VERSION ""

NS_ :

BS_:
BU_: Receiver ChassisBus VehicleBus PartyBus apb ui app aps bms gtwu odin cc cmp cp das dif dir di epas3p epas3s epbl epbr esp fc gtw hvp ibst ocs1p park pcs pmf pmr pm ptc radc rcm2 rcm sccm scm scs tas tpms umc vcfront vcleft vcright vcsec GTW
BO_ 12 ID00CUI_status: 8 VehicleBus
   SG_ UI_audioActive : 1|1@1+ (1,0) [0|1] "" Receiver
   SG_ UI_autopilotTrial : 12|2@1+ (1,0) [0|3] "" Receiver
   SG_ UI_bluetoothActive : 2|1@1+ (1,0) [0|1] "" Receiver
   SG_ UI_cameraActive : 41|1@1+ (1,0) [0|1] "" Receiver
   SG_ UI_cellActive : 3|1@1+ (1,0) [0|1] "" Receiver
   SG_ UI_cellConnected : 10|1@1+ (1,0) [0|1] "" Receiver
   SG_ UI_cellNetworkTechnology : 19|4@1+ (1,0) [0|15] "" Receiver
   SG_ UI_cellReceiverPower : 24|8@1+ (1,-128) [-128|127] "dB" Receiver
   SG_ UI_cellSignalBars : 42|3@1+ (1,0) [0|7] "" Receiver
   SG_ UI_cpuTemperature : 56|8@1- (1,40) [-20|100] "C" Receiver
   SG_ UI_developmentCar : 40|1@1+ (1,0) [0|1] "" Receiver
   SG_ UI_displayOn : 5|1@1+ (1,0) [0|1] "" Receiver
   SG_ UI_displayReady : 4|1@1+ (1,0) [0|1] "" Receiver
   SG_ UI_factoryReset : 14|2@1+ (1,0) [0|3] "" Receiver
   SG_ UI_falseTouchCounter : 32|8@1+ (1,0) [0|255] "1" Receiver
   SG_ UI_gpsActive : 16|1@1+ (1,0) [0|1] "" Receiver
   SG_ UI_pcbTemperature : 48|8@1- (1,40) [-20|100] "C" Receiver
   SG_ UI_radioActive : 18|1@1+ (1,0) [0|1] "" Receiver
   SG_ UI_readyForDrive : 9|1@1+ (1,0) [0|1] "" Receiver
   SG_ UI_screenshotActive : 17|1@1+ (1,0) [0|1] "" Receiver
   SG_ UI_systemActive : 8|1@1+ (1,0) [0|1] "" Receiver
   SG_ UI_touchActive : 0|1@1+ (1,0) [0|1] "" Receiver
   SG_ UI_vpnActive : 11|1@1+ (1,0) [0|1] "" Receiver
   SG_ UI_wifiActive : 6|1@1+ (1,0) [0|1] "" Receiver
   SG_ UI_wifiConnected : 7|1@1+ (1,0) [0|1] "" Receiver

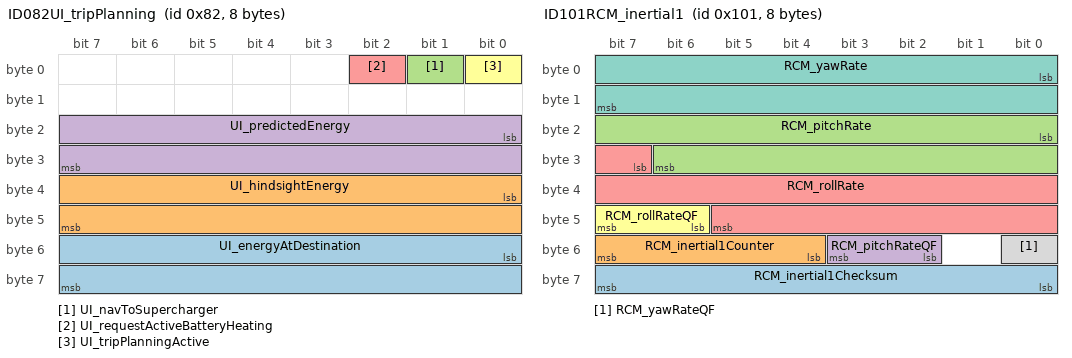
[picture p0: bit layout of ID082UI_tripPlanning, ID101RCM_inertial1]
BO_ 130 ID082UI_tripPlanning: 8 VehicleBus
   SG_ UI_energyAtDestination : 48|16@1- (0.01,0) [-327.67|327.67] "kWh" Receiver
   SG_ UI_hindsightEnergy : 32|16@1- (0.01,0) [-327.67|327.67] "kWh" Receiver
   SG_ UI_navToSupercharger : 1|1@1+ (1,0) [0|1] "" Receiver
   SG_ UI_predictedEnergy : 16|16@1- (0.01,0) [-327.67|327.67] "kWh" Receiver
   SG_ UI_requestActiveBatteryHeating : 2|1@1+ (1,0) [0|1] "" Receiver
   SG_ UI_tripPlanningActive : 0|1@1+ (1,0) [0|1] "" Receiver

BO_ 257 ID101RCM_inertial1: 8 ChassisBus
   SG_ RCM_inertial1Checksum : 56|8@1+ (1,0) [0|255] "" Receiver
   SG_ RCM_inertial1Counter : 52|4@1+ (1,0) [0|15] "" Receiver
   SG_ RCM_pitchRate : 16|15@1- (0.00025,0) [-4.096|4.09575] "rad/s" Receiver
   SG_ RCM_pitchRateQF : 50|2@1+ (1,0) [0|3] "" Receiver
   SG_ RCM_rollRate : 31|15@1- (0.00025,0) [-4.096|4.09575] "rad/s" Receiver
   SG_ RCM_rollRateQF : 46|2@1+ (1,0) [0|3] "" Receiver
   SG_ RCM_yawRate : 0|16@1- (0.0001,0) [-3.2766|3.2766] "rad/s" Receiver
   SG_ RCM_yawRateQF : 48|1@1+ (1,0) [0|1] "" Receiver

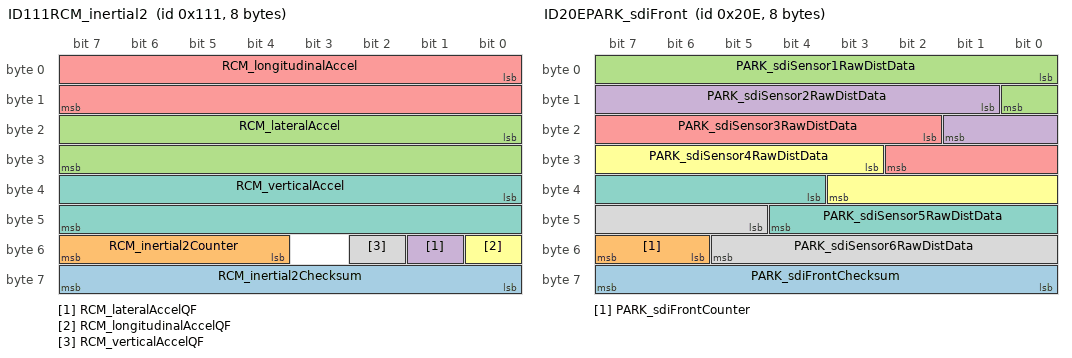
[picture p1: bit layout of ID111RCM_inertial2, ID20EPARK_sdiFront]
BO_ 273 ID111RCM_inertial2: 8 ChassisBus
   SG_ RCM_inertial2Checksum : 56|8@1+ (1,0) [0|255] "" Receiver
   SG_ RCM_inertial2Counter : 52|4@1+ (1,0) [0|15] "" Receiver
   SG_ RCM_lateralAccel : 16|16@1- (0.00125,0) [-40.9575|40.9575] "m/s^2" Receiver
   SG_ RCM_lateralAccelQF : 49|1@1+ (1,0) [0|1] "" Receiver
   SG_ RCM_longitudinalAccel : 0|16@1- (0.00125,0) [-40.9575|40.9575] "m/s^2" Receiver
   SG_ RCM_longitudinalAccelQF : 48|1@1+ (1,0) [0|1] "" Receiver
   SG_ RCM_verticalAccel : 32|16@1- (0.00125,0) [-40.9575|40.9575] "m/s^2" Receiver
   SG_ RCM_verticalAccelQF : 50|1@1+ (1,0) [0|1] "" Receiver

BO_ 258 ID102VCLEFT_doorStatus: 8 VehicleBus
   SG_ VCLEFT_frontHandlePWM : 16|7@1+ (1,0) [0|100] "%" Receiver
   SG_ VCLEFT_frontHandlePulled : 10|1@1+ (1,0) [0|1] "" Receiver
   SG_ VCLEFT_frontHandlePulledPersist : 62|1@1+ (1,0) [0|1] "" Receiver
   SG_ VCLEFT_frontIntSwitchPressed : 31|1@1+ (1,0) [0|1] "" Receiver
   SG_ VCLEFT_frontLatchStatus : 0|4@1+ (1,0) [0|8] "" Receiver
   SG_ VCLEFT_frontLatchSwitch : 8|1@1+ (1,0) [0|1] "" Receiver
   SG_ VCLEFT_frontRelActuatorSwitch : 12|1@1+ (1,0) [0|1] "" Receiver
   SG_ VCLEFT_mirrorDipped : 61|1@1+ (1,0) [0|1] "" Receiver
   SG_ VCLEFT_mirrorFoldState : 52|3@1+ (1,0) [0|4] "" Receiver
   SG_ VCLEFT_mirrorHeatState : 58|3@1+ (1,0) [0|4] "" Receiver
   SG_ VCLEFT_mirrorRecallState : 55|3@1+ (1,0) [0|5] "" Receiver
   SG_ VCLEFT_mirrorState : 49|3@1+ (1,0) [0|4] "" Receiver
   SG_ VCLEFT_mirrorTiltXPosition : 33|8@1+ (0.02,0) [0|5] "V" Receiver
   SG_ VCLEFT_mirrorTiltYPosition : 41|8@1+ (0.02,0) [0|5] "V" Receiver
   SG_ VCLEFT_rearHandlePWM : 24|7@1+ (1,0) [0|100] "%" Receiver
   SG_ VCLEFT_rearHandlePulled : 11|1@1+ (1,0) [0|1] "" Receiver
   SG_ VCLEFT_rearIntSwitchPressed : 32|1@1+ (1,0) [0|1] "" Receiver
   SG_ VCLEFT_rearLatchStatus : 4|4@1+ (1,0) [0|8] "" Receiver
   SG_ VCLEFT_rearLatchSwitch : 9|1@1+ (1,0) [0|1] "" Receiver
   SG_ VCLEFT_rearRelActuatorSwitch : 13|1@1+ (1,0) [0|1] "" Receiver

BO_ 259 ID103VCRIGHT_doorStatus: 8 VehicleBus
   SG_ VCRIGHT_frontHandlePWM : 14|7@1+ (1,0) [0|100] "%" Receiver
   SG_ VCRIGHT_frontHandlePulled : 10|1@1+ (1,0) [0|1] "" Receiver
   SG_ VCRIGHT_frontHandlePulledPersist : 30|1@1+ (1,0) [0|1] "" Receiver
   SG_ VCRIGHT_frontIntSwitchPressed : 31|1@1+ (1,0) [0|1] "" Receiver
   SG_ VCRIGHT_frontLatchStatus : 0|4@1+ (1,0) [0|8] "" Receiver
   SG_ VCRIGHT_frontLatchSwitch : 8|1@1+ (1,0) [0|1] "" Receiver
   SG_ VCRIGHT_frontRelActuatorSwitch : 12|1@1+ (1,0) [0|1] "" Receiver
   SG_ VCRIGHT_mirrorDipped : 63|1@1+ (1,0) [0|1] "" Receiver
   SG_ VCRIGHT_mirrorFoldState : 52|3@1+ (1,0) [0|4] "" Receiver
   SG_ VCRIGHT_mirrorRecallState : 60|3@1+ (1,0) [0|5] "" Receiver
   SG_ VCRIGHT_mirrorState : 49|3@1+ (1,0) [0|4] "" Receiver
   SG_ VCRIGHT_mirrorTiltXPosition : 33|8@1+ (0.02,0) [0|5] "V" Receiver
   SG_ VCRIGHT_mirrorTiltYPosition : 41|8@1+ (0.02,0) [0|5] "V" Receiver
   SG_ VCRIGHT_rearHandlePWM : 21|7@1+ (1,0) [0|100] "%" Receiver
   SG_ VCRIGHT_rearHandlePulled : 11|1@1+ (1,0) [0|1] "" Receiver
   SG_ VCRIGHT_rearIntSwitchPressed : 32|1@1+ (1,0) [0|1] "" Receiver
   SG_ VCRIGHT_rearLatchStatus : 4|4@1+ (1,0) [0|8] "" Receiver
   SG_ VCRIGHT_rearLatchSwitch : 9|1@1+ (1,0) [0|1] "" Receiver
   SG_ VCRIGHT_rearRelActuatorSwitch : 13|1@1+ (1,0) [0|1] "" Receiver
   SG_ VCRIGHT_reservedForBackCompat : 28|2@1+ (1,0) [0|3] "" Receiver
   SG_ VCRIGHT_trunkLatchStatus : 56|4@1+ (1,0) [0|8] "" Receiver

BO_ 291 ID123UI_alertMatrix1: 8 VehicleBus
   SG_ UI_a001_DriverDoorOpen : 0|1@1+ (1,0) [0|1] "" Receiver
   SG_ UI_a002_DoorOpen : 1|1@1+ (1,0) [0|1] "" Receiver
   SG_ UI_a003_TrunkOpen : 2|1@1+ (1,0) [0|1] "" Receiver
   SG_ UI_a004_FrunkOpen : 3|1@1+ (1,0) [0|1] "" Receiver
   SG_ UI_a005_HeadlightsOnDoorOpen : 4|1@1+ (1,0) [0|1] "" Receiver
   SG_ UI_a006_RemoteServiceAlert : 5|1@1+ (1,0) [0|1] "" Receiver
   SG_ UI_a007_SoftPackConfigMismatch : 6|1@1+ (1,0) [0|1] "" Receiver
   SG_ UI_a008_TouchScreenError : 7|1@1+ (1,0) [0|1] "" Receiver
   SG_ UI_a009_SquashfsError : 8|1@1+ (1,0) [0|1] "" Receiver
   SG_ UI_a010_MapsMissing : 9|1@1+ (1,0) [0|1] "" Receiver
   SG_ UI_a011_IncorrectMap : 10|1@1+ (1,0) [0|1] "" Receiver
   SG_ UI_a012_NotOnPrivateProperty : 11|1@1+ (1,0) [0|1] "" Receiver
   SG_ UI_a013_TPMSHardWarning : 12|1@1+ (1,0) [0|1] "" Receiver
   SG_ UI_a014_TPMSSoftWarning : 13|1@1+ (1,0) [0|1] "" Receiver
   SG_ UI_a015_TPMSOverPressureWarning : 14|1@1+ (1,0) [0|1] "" Receiver
   SG_ UI_a016_TPMSTemperatureWarning : 15|1@1+ (1,0) [0|1] "" Receiver
   SG_ UI_a017_TPMSSystemFault : 16|1@1+ (1,0) [0|1] "" Receiver
   SG_ UI_a018_SlipStartOn : 17|1@1+ (1,0) [0|1] "" Receiver
   SG_ UI_a019_ParkBrakeFault : 18|1@1+ (1,0) [0|1] "" Receiver
   SG_ UI_a020_SteeringReduced : 19|1@1+ (1,0) [0|1] "" Receiver
   SG_ UI_a021_RearSeatbeltUnbuckled : 20|1@1+ (1,0) [0|1] "" Receiver
   SG_ UI_a022_ApeFusesEtc : 21|1@1+ (1,0) [0|1] "" Receiver
   SG_ UI_a023_CellInternetCheckFailed : 22|1@1+ (1,0) [0|1] "" Receiver
   SG_ UI_a024_WifiInternetCheckFailed : 23|1@1+ (1,0) [0|1] "" Receiver
   SG_ UI_a025_WifiOnlineCheckFailed : 24|1@1+ (1,0) [0|1] "" Receiver
   SG_ UI_a026_ModemResetLoopDetected : 25|1@1+ (1,0) [0|1] "" Receiver
   SG_ UI_a027_AutoSteerMIA : 26|1@1+ (1,0) [0|1] "" Receiver
   SG_ UI_a028_FrontTrunkPopupClosed : 27|1@1+ (1,0) [0|1] "" Receiver
   SG_ UI_a029_ModemMIA : 28|1@1+ (1,0) [0|1] "" Receiver
   SG_ UI_a030_ModemVMCrash : 29|1@1+ (1,0) [0|1] "" Receiver
   SG_ UI_a031_BrakeFluidLow : 30|1@1+ (1,0) [0|1] "" Receiver
   SG_ UI_a032_CellModemRecoveryResets : 31|1@1+ (1,0) [0|1] "" Receiver
   SG_ UI_a033_ApTrialExpired : 32|1@1+ (1,0) [0|1] "" Receiver
   SG_ UI_a034_WakeupProblem : 33|1@1+ (1,0) [0|1] "" Receiver
   SG_ UI_a035_AudioWatchdogKernelError : 34|1@1+ (1,0) [0|1] "" Receiver
   SG_ UI_a036_AudioWatchdogHfpError : 35|1@1+ (1,0) [0|1] "" Receiver
   SG_ UI_a037_AudioWatchdogXrunStormEr : 36|1@1+ (1,0) [0|1] "" Receiver
   SG_ UI_a038_AudioWatchdogA2bI2cLocku : 37|1@1+ (1,0) [0|1] "" Receiver
   SG_ UI_a039_AudioA2bNeedRediscovery : 38|1@1+ (1,0) [0|1] "" Receiver
   SG_ UI_a040_HomelinkTransmit : 39|1@1+ (1,0) [0|1] "" Receiver
   SG_ UI_a041_AudioDmesgXrun : 40|1@1+ (1,0) [0|1] "" Receiver
   SG_ UI_a042_AudioDmesgRtThrottling : 41|1@1+ (1,0) [0|1] "" Receiver
   SG_ UI_a043_InvalidMapDataOverride : 42|1@1+ (1,0) [0|1] "" Receiver
   SG_ UI_a044_AudioDmesgDspException : 43|1@1+ (1,0) [0|1] "" Receiver
   SG_ UI_a045_ECallNeedsService : 44|1@1+ (1,0) [0|1] "" Receiver
   SG_ UI_a046_BackupCameraStreamError : 45|1@1+ (1,0) [0|1] "" Receiver
   SG_ UI_a047_CellRoamingDisallowed : 46|1@1+ (1,0) [0|1] "" Receiver
   SG_ UI_a048_AudioPremiumAmpCheckFail : 47|1@1+ (1,0) [0|1] "" Receiver
   SG_ UI_a049_BrakeShiftRequired : 48|1@1+ (1,0) [0|1] "" Receiver
   SG_ UI_a050_BackupCameraIPUTimeout : 49|1@1+ (1,0) [0|1] "" Receiver
   SG_ UI_a051_BackupCameraFrameTimeout : 50|1@1+ (1,0) [0|1] "" Receiver
   SG_ UI_a052_KernelPanicReported : 51|1@1+ (1,0) [0|1] "" Receiver
   SG_ UI_a053_QtCarExitError : 52|1@1+ (1,0) [0|1] "" Receiver
   SG_ UI_a054_AudioBoostPowerBad : 53|1@1+ (1,0) [0|1] "" Receiver
   SG_ UI_a055_ManualECallDisabled : 54|1@1+ (1,0) [0|1] "" Receiver
   SG_ UI_a056_ManualECallButtonDisconn : 55|1@1+ (1,0) [0|1] "" Receiver
   SG_ UI_a057_CellAntennaDisconnected : 56|1@1+ (1,0) [0|1] "" Receiver
   SG_ UI_a058_GPSAntennaDisconnected : 57|1@1+ (1,0) [0|1] "" Receiver
   SG_ UI_a059_ECallSpeakerDisconnected : 58|1@1+ (1,0) [0|1] "" Receiver
   SG_ UI_a060_ECallMicDisconnected : 59|1@1+ (1,0) [0|1] "" Receiver
   SG_ UI_a061_SIMTestFailed : 60|1@1+ (1,0) [0|1] "" Receiver
   SG_ UI_a062_ENSTestFailed : 61|1@1+ (1,0) [0|1] "" Receiver
   SG_ UI_a063_CellularTestFailed : 62|1@1+ (1,0) [0|1] "" Receiver
   SG_ UI_a064_ModemFirmwareTestFailed : 63|1@1+ (1,0) [0|1] "" Receiver

BO_ 322 ID142VCLEFT_liftgateStatus: 8 VehicleBus
   SG_ VCLEFT_liftgateStatusIndex M : 0|2@1+ (1,0) [0|2] "" Receiver
   SG_ VCLEFT_liftgateLatchRequest m0 : 61|3@1+ (1,0) [0|4] "" Receiver
   SG_ VCLEFT_liftgateMvmntNotAllowedCo m0 : 14|3@1+ (1,0) [0|5] "" Receiver
   SG_ VCLEFT_liftgatePhysicalChimeRequ m0 : 21|3@1+ (1,0) [0|4] "" Receiver
   SG_ VCLEFT_liftgatePosition m1 : 21|7@1- (1,33) [-5|70] "deg" Receiver
   SG_ VCLEFT_liftgatePositionCalibrate m0 : 17|1@1+ (1,0) [0|1] "" Receiver
   SG_ VCLEFT_liftgateRequestSource m0 : 7|3@1+ (1,0) [0|7] "" Receiver
   SG_ VCLEFT_liftgateSpeed m1 : 28|10@1- (0.1,0) [-30|30] "deg/s" Receiver
   SG_ VCLEFT_liftgateState m0 : 3|4@1+ (1,0) [0|12] "" Receiver
   SG_ VCLEFT_liftgateStoppingCondition m0 : 10|4@1+ (1,0) [0|11] "" Receiver
   SG_ VCLEFT_liftgateStrutCurrent m1 : 11|10@1- (0.1,0) [-30|30] "A" Receiver
   SG_ VCLEFT_liftgateStrutDutyCycle m1 : 3|8@1- (1,0) [-100|100] "%" Receiver
   SG_ VCLEFT_liftgateUIChimeRequest m0 : 18|3@1+ (1,0) [0|4] "" Receiver

BO_ 325 ID145ESP_status: 8 ChassisBus
   SG_ ESP_absBrakeEvent2 : 22|2@1+ (1,0) [0|3] "" Receiver
   SG_ ESP_absFaultLamp : 17|1@1+ (1,0) [0|1] "" Receiver
   SG_ ESP_brakeApply : 31|1@1+ (1,0) [0|1] "" Receiver
   SG_ ESP_brakeDiscWipingActive : 28|1@1+ (1,0) [0|1] "" Receiver
   SG_ ESP_brakeLamp : 21|1@1+ (1,0) [0|1] "" Receiver
   SG_ ESP_brakeTorqueTarget : 51|13@1+ (2,0) [0|16382] "Nm" Receiver
   SG_ ESP_btcTargetState : 38|2@1+ (1,0) [0|3] "" Receiver
   SG_ ESP_cdpStatus : 34|2@1+ (1,0) [0|3] "" Receiver
   SG_ ESP_driverBrakeApply : 29|2@1+ (1,0) [0|3] "" Receiver
   SG_ ESP_ebdFaultLamp : 16|1@1+ (1,0) [0|1] "" Receiver
   SG_ ESP_ebrStandstillSkid : 48|1@1+ (1,0) [0|1] "" Receiver
   SG_ ESP_ebrStatus : 49|2@1+ (1,0) [0|3] "" Receiver
   SG_ ESP_espFaultLamp : 18|1@1+ (1,0) [0|1] "" Receiver
   SG_ ESP_espLampFlash : 20|1@1+ (1,0) [0|1] "" Receiver
   SG_ ESP_espModeActive : 12|2@1+ (1,0) [0|3] "" Receiver
   SG_ ESP_hydraulicBoostEnabled : 19|1@1+ (1,0) [0|1] "" Receiver
   SG_ ESP_lateralAccelQF : 25|1@1+ (1,0) [0|1] "" Receiver
   SG_ ESP_longitudinalAccelQF : 24|1@1+ (1,0) [0|1] "" Receiver
   SG_ ESP_ptcTargetState : 36|2@1+ (1,0) [0|3] "" Receiver
   SG_ ESP_stabilityControlSts2 : 14|2@1+ (1,0) [0|3] "" Receiver
   SG_ ESP_statusChecksum : 0|8@1+ (1,0) [0|255] "" Receiver
   SG_ ESP_statusCounter : 8|4@1+ (1,0) [0|15] "" Receiver
   SG_ ESP_steeringAngleQF : 27|1@1+ (1,0) [0|1] "" Receiver
   SG_ ESP_yawRateQF : 26|1@1+ (1,0) [0|1] "" Receiver

BO_ 522 ID20AHVP_contactorState: 6 VehicleBus
   SG_ HVP_dcLinkAllowedToEnergize : 36|1@1+ (1,0) [0|1] "" Receiver
   SG_ HVP_fcContNegativeAuxOpen : 7|1@1+ (1,0) [0|1] "" Receiver
   SG_ HVP_fcContNegativeState : 12|3@1+ (1,0) [0|7] "" Receiver
   SG_ HVP_fcContPositiveAuxOpen : 6|1@1+ (1,0) [0|1] "" Receiver
   SG_ HVP_fcContPositiveState : 16|3@1+ (1,0) [0|7] "" Receiver
   SG_ HVP_fcContactorSetState : 19|4@1+ (1,0) [0|9] "" Receiver
   SG_ HVP_fcCtrsClosingAllowed : 29|1@1+ (1,0) [0|1] "" Receiver
   SG_ HVP_fcCtrsOpenNowRequested : 27|1@1+ (1,0) [0|1] "" Receiver
   SG_ HVP_fcCtrsOpenRequested : 28|1@1+ (1,0) [0|1] "" Receiver
   SG_ HVP_fcCtrsRequestStatus : 24|2@1+ (1,0) [0|2] "" Receiver
   SG_ HVP_fcCtrsResetRequestRequired : 26|1@1+ (1,0) [0|1] "" Receiver
   SG_ HVP_fcLinkAllowedToEnergize : 44|2@1+ (1,0) [0|2] "" Receiver
   SG_ HVP_hvilStatus : 40|4@1+ (1,0) [0|9] "" Receiver
   SG_ HVP_packContNegativeState : 0|3@1+ (1,0) [0|7] "" Receiver
   SG_ HVP_packContPositiveState : 3|3@1+ (1,0) [0|7] "" Receiver
   SG_ HVP_packContactorSetState : 8|4@1+ (1,0) [0|9] "" Receiver
   SG_ HVP_packCtrsClosingAllowed : 35|1@1+ (1,0) [0|1] "" Receiver
   SG_ HVP_packCtrsOpenNowRequested : 33|1@1+ (1,0) [0|1] "" Receiver
   SG_ HVP_packCtrsOpenRequested : 34|1@1+ (1,0) [0|1] "" Receiver
   SG_ HVP_packCtrsRequestStatus : 30|2@1+ (1,0) [0|2] "" Receiver
   SG_ HVP_packCtrsResetRequestRequired : 32|1@1+ (1,0) [0|1] "" Receiver
   SG_ HVP_pyroTestInProgress : 37|1@1+ (1,0) [0|1] "" Receiver

BO_ 526 ID20EPARK_sdiFront: 8 ChassisBus
   SG_ PARK_sdiFrontChecksum : 56|8@1+ (1,0) [0|255] "" Receiver
   SG_ PARK_sdiFrontCounter : 54|2@1+ (1,0) [0|3] "" Receiver
   SG_ PARK_sdiSensor1RawDistData : 0|9@1+ (1,0) [0|511] "cm" Receiver
   SG_ PARK_sdiSensor2RawDistData : 9|9@1+ (1,0) [0|511] "cm" Receiver
   SG_ PARK_sdiSensor3RawDistData : 18|9@1+ (1,0) [0|511] "cm" Receiver
   SG_ PARK_sdiSensor4RawDistData : 27|9@1+ (1,0) [0|511] "cm" Receiver
   SG_ PARK_sdiSensor5RawDistData : 36|9@1+ (1,0) [0|511] "cm" Receiver
   SG_ PARK_sdiSensor6RawDistData : 45|9@1+ (1,0) [0|511] "cm" Receiver

BO_ 537 ID219VCSEC_TPMSData: 5 ChassisBus
   SG_ VCSEC_TPMSDataIndex M : 0|2@1+ (1,0) [0|3] "" Receiver
   SG_ VCSEC_TPMSBatVoltage0 m0 : 24|8@1+ (0.01,1.5) [1.5|4.04] "V" Receiver
   SG_ VCSEC_TPMSBatVoltage1 m1 : 24|8@1+ (0.01,1.5) [1.5|4.04] "V" Receiver
   SG_ VCSEC_TPMSBatVoltage2 m2 : 24|8@1+ (0.01,1.5) [1.5|4.04] "V" Receiver
   SG_ VCSEC_TPMSBatVoltage3 m3 : 24|8@1+ (0.01,1.5) [1.5|4.04] "V" Receiver
   SG_ VCSEC_TPMSLocation0 m0 : 32|3@1+ (1,0) [0|4] "" Receiver
   SG_ VCSEC_TPMSLocation1 m1 : 32|3@1+ (1,0) [0|4] "" Receiver
   SG_ VCSEC_TPMSLocation2 m2 : 32|3@1+ (1,0) [0|4] "" Receiver
   SG_ VCSEC_TPMSLocation3 m3 : 32|3@1+ (1,0) [0|4] "" Receiver
   SG_ VCSEC_TPMSPressure0 m0 : 8|8@1+ (0.025,0) [0|6.35] "bar" Receiver
   SG_ VCSEC_TPMSPressure1 m1 : 8|8@1+ (0.025,0) [0|6.35] "bar" Receiver
   SG_ VCSEC_TPMSPressure2 m2 : 8|8@1+ (0.025,0) [0|6.35] "bar" Receiver
   SG_ VCSEC_TPMSPressure3 m3 : 8|8@1+ (0.025,0) [0|6.35] "bar" Receiver
   SG_ VCSEC_TPMSTemperature0 m0 : 16|8@1+ (1,-40) [-40|214] "C" Receiver
   SG_ VCSEC_TPMSTemperature1 m1 : 16|8@1+ (1,-40) [-40|214] "C" Receiver
   SG_ VCSEC_TPMSTemperature2 m2 : 16|8@1+ (1,-40) [-40|214] "C" Receiver
   SG_ VCSEC_TPMSTemperature3 m3 : 16|8@1+ (1,-40) [-40|214] "C" Receiver

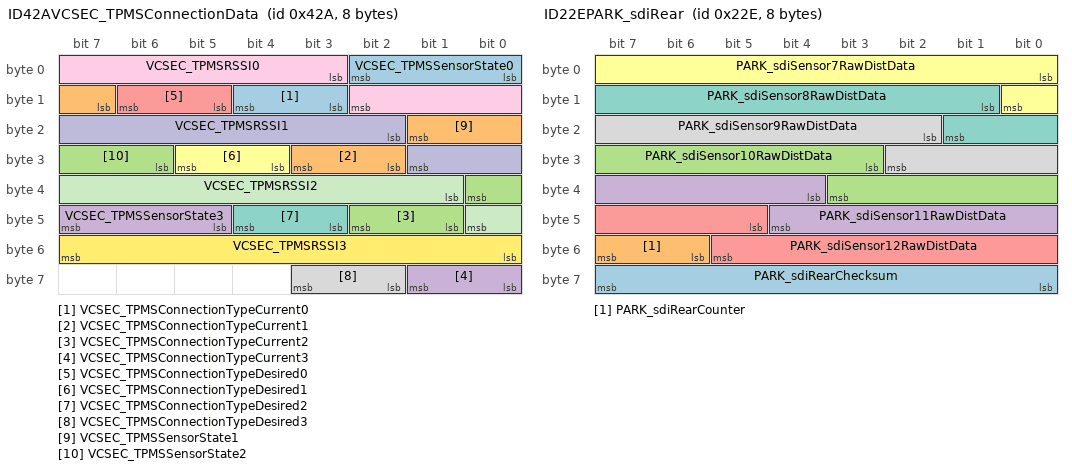
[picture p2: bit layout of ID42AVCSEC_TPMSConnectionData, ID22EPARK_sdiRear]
BO_ 1066 ID42AVCSEC_TPMSConnectionData: 8 VehicleBus
   SG_ VCSEC_TPMSConnectionTypeCurrent0 : 11|2@1+ (1,0) [0|2] "" Receiver
   SG_ VCSEC_TPMSConnectionTypeCurrent1 : 26|2@1+ (1,0) [0|2] "" Receiver
   SG_ VCSEC_TPMSConnectionTypeCurrent2 : 41|2@1+ (1,0) [0|2] "" Receiver
   SG_ VCSEC_TPMSConnectionTypeCurrent3 : 56|2@1+ (1,0) [0|2] "" Receiver
   SG_ VCSEC_TPMSConnectionTypeDesired0 : 13|2@1+ (1,0) [0|2] "" Receiver
   SG_ VCSEC_TPMSConnectionTypeDesired1 : 28|2@1+ (1,0) [0|2] "" Receiver
   SG_ VCSEC_TPMSConnectionTypeDesired2 : 43|2@1+ (1,0) [0|2] "" Receiver
   SG_ VCSEC_TPMSConnectionTypeDesired3 : 58|2@1+ (1,0) [0|2] "" Receiver
   SG_ VCSEC_TPMSRSSI0 : 3|8@1- (1,0) [-127|0] "dBm" Receiver
   SG_ VCSEC_TPMSRSSI1 : 18|8@1- (1,0) [-127|0] "dBm" Receiver
   SG_ VCSEC_TPMSRSSI2 : 33|8@1- (1,0) [-127|0] "dBm" Receiver
   SG_ VCSEC_TPMSRSSI3 : 48|8@1- (1,0) [-127|0] "dBm" Receiver
   SG_ VCSEC_TPMSSensorState0 : 0|3@1+ (1,0) [0|4] "" Receiver
   SG_ VCSEC_TPMSSensorState1 : 15|3@1+ (1,0) [0|4] "" Receiver
   SG_ VCSEC_TPMSSensorState2 : 30|3@1+ (1,0) [0|4] "" Receiver
   SG_ VCSEC_TPMSSensorState3 : 45|3@1+ (1,0) [0|4] "" Receiver

BO_ 558 ID22EPARK_sdiRear: 8 VehicleBus
   SG_ PARK_sdiRearChecksum : 56|8@1+ (1,0) [0|255] "" Receiver
   SG_ PARK_sdiRearCounter : 54|2@1+ (1,0) [0|3] "" Receiver
   SG_ PARK_sdiSensor10RawDistData : 27|9@1+ (1,0) [0|511] "cm" Receiver
   SG_ PARK_sdiSensor11RawDistData : 36|9@1+ (1,0) [0|511] "cm" Receiver
   SG_ PARK_sdiSensor12RawDistData : 45|9@1+ (1,0) [0|511] "cm" Receiver
   SG_ PARK_sdiSensor7RawDistData : 0|9@1+ (1,0) [0|511] "cm" Receiver
   SG_ PARK_sdiSensor8RawDistData : 9|9@1+ (1,0) [0|511] "cm" Receiver
   SG_ PARK_sdiSensor9RawDistData : 18|9@1+ (1,0) [0|511] "cm" Receiver

BO_ 568 ID238UI_driverAssistMapData: 8 ChassisBus
   SG_ UI_acceptBottsDots : 48|1@1+ (1,0) [0|1] "" Receiver
   SG_ UI_autosteerRestricted : 49|1@1+ (1,0) [0|1] "" Receiver
   SG_ UI_controlledAccess : 37|1@1+ (1,0) [0|1] "" Receiver
   SG_ UI_countryCode : 16|10@1+ (1,0) [0|1023] "" Receiver
   SG_ UI_gpsRoadMatch : 28|1@1+ (1,0) [0|1] "" Receiver
   SG_ UI_inSuperchargerGeofence : 6|1@1+ (1,0) [0|1] "" Receiver
   SG_ UI_mapDataChecksum : 56|8@1+ (1,0) [0|255] "" Receiver
   SG_ UI_mapDataCounter : 52|4@1+ (1,0) [0|15] "" Receiver
   SG_ UI_mapSpeedLimit : 8|5@1+ (1,0) [0|31] "" Receiver
   SG_ UI_mapSpeedLimitDependency : 0|3@1+ (1,0) [0|7] "" Receiver
   SG_ UI_mapSpeedLimitType : 13|3@1+ (1,0) [0|7] "" Receiver
   SG_ UI_mapSpeedUnits : 7|1@1+ (1,0) [0|1] "" Receiver
   SG_ UI_navRouteActive : 29|1@1+ (1,0) [0|1] "" Receiver
   SG_ UI_nextBranchDist : 32|5@1+ (10,0) [0|300] "m" Receiver
   SG_ UI_nextBranchLeftOffRamp : 38|1@1+ (1,0) [0|1] "" Receiver
   SG_ UI_nextBranchRightOffRamp : 39|1@1+ (1,0) [0|1] "" Receiver
   SG_ UI_parallelAutoparkEnabled : 30|1@1+ (1,0) [0|1] "" Receiver
   SG_ UI_perpendicularAutoparkEnabled : 31|1@1+ (1,0) [0|1] "" Receiver
   SG_ UI_pmmEnabled : 50|1@1+ (1,0) [0|1] "" Receiver
   SG_ UI_rejectAutosteer : 46|1@1+ (1,0) [0|1] "" Receiver
   SG_ UI_rejectHPP : 42|1@1+ (1,0) [0|1] "" Receiver
   SG_ UI_rejectHandsOn : 47|1@1+ (1,0) [0|1] "" Receiver
   SG_ UI_rejectLeftFreeSpace : 44|1@1+ (1,0) [0|1] "" Receiver
   SG_ UI_rejectLeftLane : 40|1@1+ (1,0) [0|1] "" Receiver
   SG_ UI_rejectNav : 43|1@1+ (1,0) [0|1] "" Receiver
   SG_ UI_rejectRightFreeSpace : 45|1@1+ (1,0) [0|1] "" Receiver
   SG_ UI_rejectRightLane : 41|1@1+ (1,0) [0|1] "" Receiver
   SG_ UI_roadClass : 3|3@1+ (1,0) [0|6] "" Receiver
   SG_ UI_scaEnabled : 51|1@1+ (1,0) [0|1] "" Receiver
   SG_ UI_streetCount : 26|2@1+ (1,0) [0|3] "" Receiver

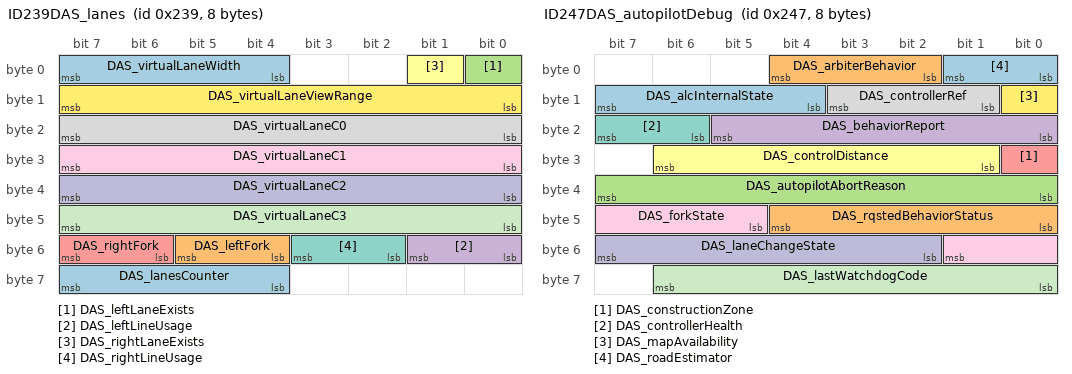
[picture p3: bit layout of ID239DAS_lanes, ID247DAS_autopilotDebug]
BO_ 569 ID239DAS_lanes: 8 ChassisBus
   SG_ DAS_lanesCounter : 60|4@1+ (1,0) [0|15] "" Receiver
   SG_ DAS_leftFork : 52|2@1+ (1,0) [0|3] "" Receiver
   SG_ DAS_leftLaneExists : 0|1@1+ (1,0) [0|1] "" Receiver
   SG_ DAS_leftLineUsage : 48|2@1+ (1,0) [0|3] "" Receiver
   SG_ DAS_rightFork : 54|2@1+ (1,0) [0|3] "" Receiver
   SG_ DAS_rightLaneExists : 1|1@1+ (1,0) [0|1] "" Receiver
   SG_ DAS_rightLineUsage : 50|2@1+ (1,0) [0|3] "" Receiver
   SG_ DAS_virtualLaneC0 : 16|8@1+ (0.035,-3.5) [-3.5|3.5] "m" Receiver
   SG_ DAS_virtualLaneC1 : 24|8@1+ (0.0016,-0.2) [-0.2|0.2] "rad" Receiver
   SG_ DAS_virtualLaneC2 : 32|8@1+ (2e-05,-0.0025) [-0.0025|0.0025] "m-1" Receiver
   SG_ DAS_virtualLaneC3 : 40|8@1+ (2.4e-07,-3e-05) [-3e-05|3e-05] "m-2" Receiver
   SG_ DAS_virtualLaneViewRange : 8|8@1+ (1,0) [0|160] "m" Receiver
   SG_ DAS_virtualLaneWidth : 4|4@1+ (0.3125,2) [2|6.6875] "m" Receiver

BO_ 583 ID247DAS_autopilotDebug: 8 VehicleBus
   SG_ DAS_alcInternalState : 12|4@1+ (1,0) [0|12] "" Receiver
   SG_ DAS_arbiterBehavior : 2|3@1+ (1,0) [0|4] "" Receiver
   SG_ DAS_autopilotAbortReason : 32|8@1+ (1,0) [0|255] "" Receiver
   SG_ DAS_behaviorReport : 16|6@1+ (1,0) [1|43] "" Receiver
   SG_ DAS_constructionZone : 24|1@1+ (1,0) [0|1] "" Receiver
   SG_ DAS_controlDistance : 25|6@1+ (2,0) [0|126] "m" Receiver
   SG_ DAS_controllerHealth : 22|2@1+ (1,0) [0|3] "" Receiver
   SG_ DAS_controllerRef : 9|3@1+ (1,0) [0|6] "" Receiver
   SG_ DAS_forkState : 45|5@1+ (1,0) [0|27] "" Receiver
   SG_ DAS_laneChangeState : 50|6@1+ (1,0) [0|63] "" Receiver
   SG_ DAS_lastWatchdogCode : 56|7@1+ (1,0) [0|80] "" Receiver
   SG_ DAS_mapAvailability : 8|1@1+ (1,0) [0|1] "" Receiver
   SG_ DAS_roadEstimator : 0|2@1+ (1,0) [0|3] "" Receiver
   SG_ DAS_rqstedBehaviorStatus : 40|5@1+ (1,0) [0|22] "" Receiver

BO_ 586 ID24ADAS_visualDebug: 8 ChassisBus
   SG_ DAS_accSmartSpeedActive : 48|1@1+ (1,0) [0|1] "" Receiver
   SG_ DAS_accSmartSpeedState : 49|3@1+ (1,0) [0|7] "" Receiver
   SG_ DAS_autosteerBottsDotsUsage : 12|2@1+ (1,0) [0|3] "" Receiver
   SG_ DAS_autosteerHPPUsage : 6|2@1+ (1,0) [0|3] "" Receiver
   SG_ DAS_autosteerHealthAnomalyLevel : 18|3@1+ (1,0) [0|7] "" Receiver
   SG_ DAS_autosteerHealthState : 21|3@1+ (1,0) [0|5] "" Receiver
   SG_ DAS_autosteerModelUsage : 10|2@1+ (1,0) [0|3] "" Receiver
   SG_ DAS_autosteerNavigationUsage : 8|2@1+ (1,0) [0|3] "" Receiver
   SG_ DAS_autosteerVehiclesUsage : 4|2@1+ (1,0) [0|3] "" Receiver
   SG_ DAS_behaviorType : 56|2@1+ (1,0) [0|3] "" Receiver
   SG_ DAS_devAppInterfaceEnabled : 38|1@1+ (1,0) [0|1] "" Receiver
   SG_ DAS_lastAutosteerAbortReason : 32|6@1+ (1,0) [0|34] "" Receiver
   SG_ DAS_lastLinePreferenceReason : 24|4@1+ (1,0) [0|15] "" Receiver
   SG_ DAS_navAvailable : 39|1@1+ (1,0) [0|1] "" Receiver
   SG_ DAS_navDistance : 40|8@1+ (100,0) [0|25500] "km" Receiver
   SG_ DAS_offsetSide : 14|2@1+ (1,0) [0|3] "" Receiver
   SG_ DAS_plannerState : 28|4@1+ (1,0) [0|7] "" Receiver
   SG_ DAS_rearLeftVehDetectedCurrent : 61|1@1+ (1,0) [0|1] "" Receiver
   SG_ DAS_rearLeftVehDetectedTrip : 63|1@1+ (1,0) [0|1] "" Receiver
   SG_ DAS_rearRightVehDetectedTrip : 62|1@1+ (1,0) [0|1] "" Receiver
   SG_ DAS_rearVehDetectedThisCycle : 60|1@1+ (1,0) [0|1] "" Receiver
   SG_ DAS_roadSurfaceType : 16|2@1+ (1,0) [0|2] "" Receiver
   SG_ DAS_ulcInProgress : 52|1@1+ (1,0) [0|1] "" Receiver
   SG_ DAS_ulcType : 58|2@1+ (1,0) [0|2] "" Receiver

BO_ 603 ID25BAPP_environment: 1 ChassisBus
   SG_ APP_environmentRainy : 0|1@1+ (1,0) [0|1] "" Receiver
   SG_ APP_environmentSnowy : 1|1@1+ (1,0) [0|1] "" Receiver

BO_ 605 ID25DCP_status: 8 VehicleBus
   SG_ CP_UHF_controlState : 38|4@1+ (1,0) [0|10] "" Receiver
   SG_ CP_UHF_handleFound : 42|1@1+ (1,0) [0|1] "" Receiver
   SG_ CP_apsVoltage : 24|8@1+ (0.0715686,0) [0|18.249] "V" Vector__XXX
   SG_ CP_chargeCablePresent : 3|1@1+ (1,0) [0|1] "" odin
   SG_ CP_chargeCableSecured : 4|1@1+ (1,0) [0|1] "" Receiver
   SG_ CP_chargeCableState : 14|2@1+ (1,0) [0|2] "" Receiver
   SG_ CP_chargeDoorOpen : 10|1@1+ (1,0) [0|1] "" Receiver
   SG_ CP_chargeDoorOpenUI : 51|1@1+ (1,0) [0|1] "" Receiver
   SG_ CP_coldWeatherMode : 60|1@1+ (1,0) [0|1] "" Receiver
   SG_ CP_coverClosed : 63|1@1+ (1,0) [0|1] "" Receiver
   SG_ CP_doorButtonPressed : 32|1@1+ (1,0) [0|1] "" Receiver
   SG_ CP_doorControlState : 11|3@1+ (1,0) [0|6] "" Receiver
   SG_ CP_doorOpenRequested : 43|1@1+ (1,0) [0|1] "" Receiver
   SG_ CP_faultLineSensed : 44|1@1+ (1,0) [0|1] "" Receiver
   SG_ CP_hvInletExposed : 61|1@1+ (1,0) [0|1] "" Receiver
   SG_ CP_inductiveDoorState : 45|3@1+ (1,0) [0|7] "" Receiver
   SG_ CP_inductiveSensorState : 48|3@1+ (1,0) [0|7] "" Receiver
   SG_ CP_insertEnableLine : 2|1@1+ (1,0) [0|1] "" Receiver
   SG_ CP_latch2ControlState : 19|3@1+ (1,0) [0|5] "" Receiver
   SG_ CP_latch2State : 8|2@1+ (1,0) [0|3] "" Receiver
   SG_ CP_latchControlState : 16|3@1+ (1,0) [0|5] "" Receiver
   SG_ CP_latchEngaged : 62|1@1+ (1,0) [0|1] "" Receiver
   SG_ CP_latchState : 5|2@1+ (1,0) [0|3] "" Receiver
   SG_ CP_ledColor : 33|4@1+ (1,0) [0|10] "" Receiver
   SG_ CP_numAlertsSet : 53|7@1+ (1,0) [0|127] "" Receiver
   SG_ CP_permanentPowerRequest : 7|1@1+ (1,0) [0|1] "" Receiver
   SG_ CP_swcanRelayClosed : 37|1@1+ (1,0) [0|1] "" Receiver
   SG_ CP_type : 0|2@1+ (1,0) [0|3] "" Receiver
   SG_ CP_vehicleUnlockRequest : 52|1@1+ (1,0) [0|1] "" Receiver

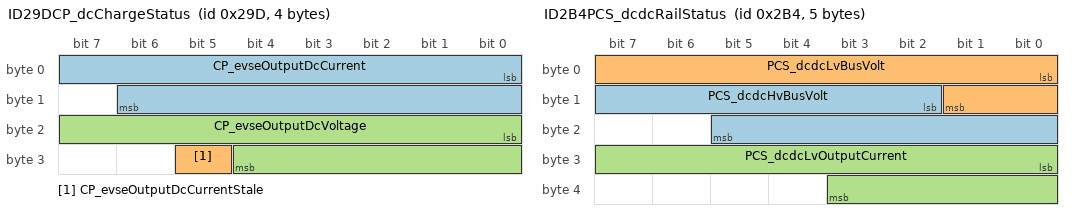
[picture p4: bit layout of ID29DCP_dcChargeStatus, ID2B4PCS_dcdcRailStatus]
BO_ 669 ID29DCP_dcChargeStatus: 4 VehicleBus
   SG_ CP_evseOutputDcCurrent : 0|15@1- (0.0732467,0) [-1200|1200] "A" Receiver
   SG_ CP_evseOutputDcCurrentStale : 29|1@1+ (1,0) [0|1] "" Receiver
   SG_ CP_evseOutputDcVoltage : 16|13@1+ (0.0732422,0) [0|599.927] "V" Receiver

BO_ 692 ID2B4PCS_dcdcRailStatus: 5 VehicleBus
   SG_ PCS_dcdcHvBusVolt : 10|12@1+ (0.146484,0) [0|599.854] "V" Receiver
   SG_ PCS_dcdcLvBusVolt : 0|10@1+ (0.0390625,0) [0|39.9609] "V" Receiver
   SG_ PCS_dcdcLvOutputCurrent : 24|12@1+ (0.1,0) [0|400] "A" Receiver

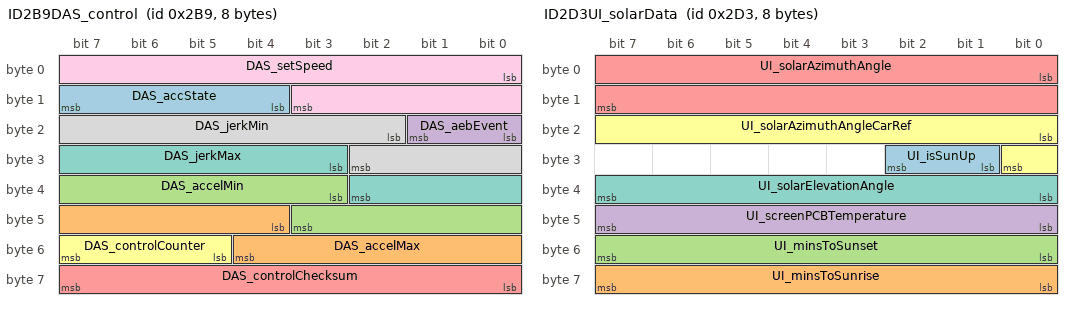
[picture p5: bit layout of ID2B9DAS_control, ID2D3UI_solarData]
BO_ 697 ID2B9DAS_control: 8 ChassisBus
   SG_ DAS_accState : 12|4@1+ (1,0) [0|15] "" Receiver
   SG_ DAS_accelMax : 44|9@1+ (0.04,-15) [-15|5.44] "m/s^2" Receiver
   SG_ DAS_accelMin : 35|9@1+ (0.04,-15) [-15|5.44] "m/s^2" Receiver
   SG_ DAS_aebEvent : 16|2@1+ (1,0) [0|3] "" Receiver
   SG_ DAS_controlChecksum : 56|8@1+ (1,0) [0|255] "" Receiver
   SG_ DAS_controlCounter : 53|3@1+ (1,0) [0|7] "" Receiver
   SG_ DAS_jerkMax : 27|8@1+ (0.059,0) [0|15.045] "m/s^3" Receiver
   SG_ DAS_jerkMin : 18|9@1+ (0.03,-15.232) [-15.232|0.098] "m/s^3" Receiver
   SG_ DAS_setSpeed : 0|12@1+ (0.1,0) [0|409.4] "kph" Receiver

BO_ 723 ID2D3UI_solarData: 8 ChassisBus
   SG_ UI_isSunUp : 25|2@1+ (1,0) [0|3] "" Receiver
   SG_ UI_minsToSunrise : 56|8@1+ (10,0) [0|2550] "min" Receiver
   SG_ UI_minsToSunset : 48|8@1+ (10,0) [0|2550] "min" Receiver
   SG_ UI_screenPCBTemperature : 40|8@1- (0.5,40) [-20|100] "C" Receiver
   SG_ UI_solarAzimuthAngle : 0|16@1- (1,0) [-32767|32767] "deg" Receiver
   SG_ UI_solarAzimuthAngleCarRef : 16|9@1- (1,0) [-256|254] "deg" Receiver
   SG_ UI_solarElevationAngle : 32|8@1- (1,0) [-128|126] "deg" Receiver

BO_ 777 ID309DAS_object: 8 VehicleBus
   SG_ DAS_objectId M : 0|3@1+ (1,0) [0|5] "" Receiver
   SG_ DAS_cutinVehDx m3 : 8|8@1+ (0.5,0) [0|127] "m" Receiver
   SG_ DAS_cutinVehDy m3 : 20|7@1+ (0.35,-22.05) [-22.05|22.4] "m" Receiver
   SG_ DAS_cutinVehHeading m5 : 56|8@1+ (0.0245437,-3.14159) [-3.14159|3.09251] "rad" Receiver
   SG_ DAS_cutinVehId m3 : 27|7@1+ (1,0) [0|127] "" Receiver
   SG_ DAS_cutinVehRelevantForControl m3 : 7|1@1+ (1,0) [0|1] "" Receiver
   SG_ DAS_cutinVehType m3 : 3|3@1+ (1,0) [0|5] "" Receiver
   SG_ DAS_cutinVehVxRel m3 : 16|4@1+ (4,-30) [-30|26] "m/s" Receiver
   SG_ DAS_leadVeh2Dx m0 : 39|8@1+ (0.5,0) [0|127] "m" Receiver
   SG_ DAS_leadVeh2Dy m0 : 51|7@1+ (0.35,-22.05) [-22.05|22.4] "m" Receiver
   SG_ DAS_leadVeh2Heading m5 : 16|8@1+ (0.0245437,-3.14159) [-3.14159|3.09251] "rad" Receiver
   SG_ DAS_leadVeh2Id m0 : 58|6@1+ (1,0) [0|63] "" Receiver
   SG_ DAS_leadVeh2RelevantForControl m0 : 38|1@1+ (1,0) [0|1] "" Receiver
   SG_ DAS_leadVeh2Type m0 : 34|3@1+ (1,0) [0|5] "" Receiver
   SG_ DAS_leadVeh2VxRel m0 : 47|4@1+ (4,-30) [-30|26] "m/s" Receiver
   SG_ DAS_leadVehDx m0 : 8|8@1+ (0.5,0) [0|127] "m" Receiver
   SG_ DAS_leadVehDy m0 : 20|7@1+ (0.35,-22.05) [-22.05|22.4] "m" Receiver
   SG_ DAS_leadVehHeading m5 : 8|8@1+ (0.0245437,-3.14159) [-3.14159|3.09251] "rad" Receiver
   SG_ DAS_leadVehId m0 : 27|7@1+ (1,0) [0|127] "" Receiver
   SG_ DAS_leadVehRelevantForControl m0 : 7|1@1+ (1,0) [0|1] "" Receiver
   SG_ DAS_leadVehType m0 : 3|3@1+ (1,0) [0|6] "" Receiver
   SG_ DAS_leadVehVxRel m0 : 16|4@1+ (4,-30) [-30|26] "m/s" Receiver
   SG_ DAS_leftVeh2Dx m1 : 39|8@1+ (0.5,0) [0|127] "m" Receiver
   SG_ DAS_leftVeh2Dy m1 : 51|7@1+ (0.35,-22.05) [-22.05|22.4] "m" Receiver
   SG_ DAS_leftVeh2Heading m5 : 32|8@1+ (0.0245437,-3.14159) [-3.14159|3.09251] "rad" Receiver
   SG_ DAS_leftVeh2Id m1 : 58|6@1+ (1,0) [0|63] "" Receiver
   SG_ DAS_leftVeh2RelevantForControl m1 : 38|1@1+ (1,0) [0|1] "" Receiver
   SG_ DAS_leftVeh2Type m1 : 34|3@1+ (1,0) [0|5] "" Receiver
   SG_ DAS_leftVeh2VxRel m1 : 47|4@1+ (4,-30) [-30|26] "m/s" Receiver
   SG_ DAS_leftVehDx m1 : 8|8@1+ (0.5,0) [0|127] "m" Receiver
   SG_ DAS_leftVehDy m1 : 20|7@1+ (0.35,-22.05) [-22.05|22.4] "m" Receiver
   SG_ DAS_leftVehHeading m5 : 24|8@1+ (0.0245437,-3.14159) [-3.14159|3.09251] "rad" Receiver
   SG_ DAS_leftVehId m1 : 27|7@1+ (1,0) [0|127] "" Receiver
   SG_ DAS_leftVehRelevantForControl m1 : 7|1@1+ (1,0) [0|1] "" Receiver
   SG_ DAS_leftVehType m1 : 3|3@1+ (1,0) [0|5] "" Receiver
   SG_ DAS_leftVehVxRel m1 : 16|4@1+ (4,-30) [-30|26] "m/s" Receiver
   SG_ DAS_rightVeh2Dx m2 : 39|8@1+ (0.5,0) [0|127] "m" Receiver
   SG_ DAS_rightVeh2Dy m2 : 51|7@1+ (0.35,-22.05) [-22.05|22.4] "m" Receiver
   SG_ DAS_rightVeh2Heading m5 : 48|8@1+ (0.0245437,-3.14159) [-3.14159|3.09251] "rad" Receiver
   SG_ DAS_rightVeh2Id m2 : 58|6@1+ (1,0) [0|63] "" Receiver
   SG_ DAS_rightVeh2RelevantForControl m2 : 38|1@1+ (1,0) [0|1] "" Receiver
   SG_ DAS_rightVeh2Type m2 : 34|3@1+ (1,0) [0|5] "" Receiver
   SG_ DAS_rightVeh2VxRel m2 : 47|4@1+ (4,-30) [-30|26] "m/s" Receiver
   SG_ DAS_rightVehDx m2 : 8|8@1+ (0.5,0) [0|127] "m" Receiver
   SG_ DAS_rightVehDy m2 : 20|7@1+ (0.35,-22.05) [-22.05|22.4] "m" Receiver
   SG_ DAS_rightVehHeading m5 : 40|8@1+ (0.0245437,-3.14159) [-3.14159|3.09251] "rad" Receiver
   SG_ DAS_rightVehId m2 : 27|7@1+ (1,0) [0|127] "" Receiver
   SG_ DAS_rightVehRelevantForControl m2 : 7|1@1+ (1,0) [0|1] "" Receiver
   SG_ DAS_rightVehType m2 : 3|3@1+ (1,0) [0|5] "" Receiver
   SG_ DAS_rightVehVxRel m2 : 16|4@1+ (4,-30) [-30|26] "m/s" Receiver
   SG_ DAS_roadSignArrow m4 : 27|3@1+ (1,0) [0|4] "" Receiver
   SG_ DAS_roadSignColor m4 : 3|3@1+ (1,0) [0|4] "" Receiver
   SG_ DAS_roadSignControlActive m4 : 24|1@1+ (1,0) [0|1] "" Receiver
   SG_ DAS_roadSignId m4 : 6|8@1+ (1,0) [0|255] "" Receiver
   SG_ DAS_roadSignOrientation m4 : 30|2@1+ (1,0) [0|2] "" Receiver
   SG_ DAS_roadSignSource m4 : 25|2@1+ (1,0) [0|2] "" Receiver
   SG_ DAS_roadSignStopLineDist m4 : 14|10@1+ (0.2,-20) [-20|184.4] "m" Receiver

BA_DEF_ BO_ "GenMsgSendType" ENUM "Cyclic","SendType1","SendType2","SendType3","SendType4","SendType5","SendType6","SendType7","SendType8","SendType9";
BA_DEF_ BO_ "GenMsgCycleTime" INT 0 0;
BA_DEF_ BO_ "GenMsgAutoGenSnd" ENUM "Cyclic","SendType1","SendType2","SendType3","SendType4","SendType5","SendType6","SendType7","SendType8","SendType9","Cyclic","SendType1","SendType2","SendType3","SendType4","SendType5","SendType6","SendType7","SendType8","SendType9","Cyclic","SendType1","SendType2","SendType3","SendType4","SendType5","SendType6","SendType7","SendType8","SendType9","Cyclic","SendType1","SendType2","SendType3","SendType4","SendType5","SendType6","SendType7","SendType8","SendType9","Cyclic","SendType1","SendType2","SendType3","SendType4","SendType5","SendType6","SendType7","SendType8","SendType9","No","Yes";
BA_DEF_ BO_ "GenMsgAutoGenDsp" ENUM "Cyclic","SendType1","SendType2","SendType3","SendType4","SendType5","SendType6","SendType7","SendType8","SendType9","Cyclic","SendType1","SendType2","SendType3","SendType4","SendType5","SendType6","SendType7","SendType8","SendType9","Cyclic","SendType1","SendType2","SendType3","SendType4","SendType5","SendType6","SendType7","SendType8","SendType9","Cyclic","SendType1","SendType2","SendType3","SendType4","SendType5","SendType6","SendType7","SendType8","SendType9","Cyclic","SendType1","SendType2","SendType3","SendType4","SendType5","SendType6","SendType7","SendType8","SendType9","No","Yes","Cyclic","SendType1","SendType2","SendType3","SendType4","SendType5","SendType6","SendType7","SendType8","SendType9","Cyclic","SendType1","SendType2","SendType3","SendType4","SendType5","SendType6","SendType7","SendType8","SendType9","Cyclic","SendType1","SendType2","SendType3","SendType4","SendType5","SendType6","SendType7","SendType8","SendType9","Cyclic","SendType1","SendType2","SendType3","SendType4","SendType5","SendType6","SendType7","SendType8","SendType9","No","Yes","Cyclic","SendType1","SendType2","SendType3","SendType4","SendType5","SendType6","SendType7","SendType8","SendType9","Cyclic","SendType1","SendType2","SendType3","SendType4","SendType5","SendType6","SendType7","SendType8","SendType9","Cyclic","SendType1","SendType2","SendType3","SendType4","SendType5","SendType6","SendType7","SendType8","SendType9","No","Yes","Cyclic","SendType1","SendType2","SendType3","SendType4","SendType5","SendType6","SendType7","SendType8","SendType9","Cyclic","SendType1","SendType2","SendType3","SendType4","SendType5","SendType6","SendType7","SendType8","SendType9","No","Yes","Cyclic","SendType1","SendType2","SendType3","SendType4","SendType5","SendType6","SendType7","SendType8","SendType9","No","Yes","No","Yes";
BA_DEF_ SG_ "GenSigAutoGenSnd" ENUM "Cyclic","SendType1","SendType2","SendType3","SendType4","SendType5","SendType6","SendType7","SendType8","SendType9","Cyclic","SendType1","SendType2","SendType3","SendType4","SendType5","SendType6","SendType7","SendType8","SendType9","Cyclic","SendType1","SendType2","SendType3","SendType4","SendType5","SendType6","SendType7","SendType8","SendType9","Cyclic","SendType1","SendType2","SendType3","SendType4","SendType5","SendType6","SendType7","SendType8","SendType9","Cyclic","SendType1","SendType2","SendType3","SendType4","SendType5","SendType6","SendType7","SendType8","SendType9","No","Yes","Cyclic","SendType1","SendType2","SendType3","SendType4","SendType5","SendType6","SendType7","SendType8","SendType9","Cyclic","SendType1","SendType2","SendType3","SendType4","SendType5","SendType6","SendType7","SendType8","SendType9","Cyclic","SendType1","SendType2","SendType3","SendType4","SendType5","SendType6","SendType7","SendType8","SendType9","Cyclic","SendType1","SendType2","SendType3","SendType4","SendType5","SendType6","SendType7","SendType8","SendType9","No","Yes","Cyclic","SendType1","SendType2","SendType3","SendType4","SendType5","SendType6","SendType7","SendType8","SendType9","Cyclic","SendType1","SendType2","SendType3","SendType4","SendType5","SendType6","SendType7","SendType8","SendType9","Cyclic","SendType1","SendType2","SendType3","SendType4","SendType5","SendType6","SendType7","SendType8","SendType9","No","Yes","Cyclic","SendType1","SendType2","SendType3","SendType4","SendType5","SendType6","SendType7","SendType8","SendType9","Cyclic","SendType1","SendType2","SendType3","SendType4","SendType5","SendType6","SendType7","SendType8","SendType9","No","Yes","Cyclic","SendType1","SendType2","SendType3","SendType4","SendType5","SendType6","SendType7","SendType8","SendType9","No","Yes","No","Yes","Cyclic","SendType1","SendType2","SendType3","SendType4","SendType5","SendType6","SendType7","SendType8","SendType9","Cyclic","SendType1","SendType2","SendType3","SendType4","SendType5","SendType6","SendType7","SendType8","SendType9","Cyclic","SendType1","SendType2","SendType3","SendType4","SendType5","SendType6","SendType7","SendType8","SendType9","Cyclic","SendType1","SendType2","SendType3","SendType4","SendType5","SendType6","SendType7","SendType8","SendType9","No","Yes","Cyclic","SendType1","SendType2","SendType3","SendType4","SendType5","SendType6","SendType7","SendType8","SendType9","Cyclic","SendType1","SendType2","SendType3","SendType4","SendType5","SendType6","SendType7","SendType8","SendType9","Cyclic","SendType1","SendType2","SendType3","SendType4","SendType5","SendType6","SendType7","SendType8","SendType9","No","Yes","Cyclic","SendType1","SendType2","SendType3","SendType4","SendType5","SendType6","SendType7","SendType8","SendType9","Cyclic","SendType1","SendType2","SendType3","SendType4","SendType5","SendType6","SendType7","SendType8","SendType9","No","Yes","Cyclic","SendType1","SendType2","SendType3","SendType4","SendType5","SendType6","SendType7","SendType8","SendType9","No","Yes","No","Yes","Cyclic","SendType1","SendType2","SendType3","SendType4","SendType5","SendType6","SendType7","SendType8","SendType9","Cyclic","SendType1","SendType2","SendType3","SendType4","SendType5","SendType6","SendType7","SendType8","SendType9","Cyclic","SendType1","SendType2","SendType3","SendType4","SendType5","SendType6","SendType7","SendType8","SendType9","No","Yes","Cyclic","SendType1","SendType2","SendType3","SendType4","SendType5","SendType6","SendType7","SendType8","SendType9","Cyclic","SendType1","SendType2","SendType3","SendType4","SendType5","SendType6","SendType7","SendType8","SendType9","No","Yes","Cyclic","SendType1","SendType2","SendType3","SendType4","SendType5","SendType6","SendType7","SendType8","SendType9","No","Yes","No","Yes","Cyclic","SendType1","SendType2","SendType3","SendType4","SendType5","SendType6","SendType7","SendType8","SendType9","Cyclic","SendType1","SendType2","SendType3","SendType4","SendType5","SendType6","SendType7","SendType8","SendType9","No","Yes","Cyclic","SendType1","SendType2","SendType3","SendType4","SendType5","SendType6","SendType7","SendType8","SendType9","No","Yes","No","Yes","Cyclic","SendType1","SendType2","SendType3","SendType4","SendType5","SendType6","SendType7","SendType8","SendType9","No","Yes","No","Yes","No","Yes";
BA_DEF_ SG_ "GenSigAutoGenDsp" ENUM "Cyclic","SendType1","SendType2","SendType3","SendType4","SendType5","SendType6","SendType7","SendType8","SendType9","Cyclic","SendType1","SendType2","SendType3","SendType4","SendType5","SendType6","SendType7","SendType8","SendType9","Cyclic","SendType1","SendType2","SendType3","SendType4","SendType5","SendType6","SendType7","SendType8","SendType9","Cyclic","SendType1","SendType2","SendType3","SendType4","SendType5","SendType6","SendType7","SendType8","SendType9","Cyclic","SendType1","SendType2","SendType3","SendType4","SendType5","SendType6","SendType7","SendType8","SendType9","No","Yes","Cyclic","SendType1","SendType2","SendType3","SendType4","SendType5","SendType6","SendType7","SendType8","SendType9","Cyclic","SendType1","SendType2","SendType3","SendType4","SendType5","SendType6","SendType7","SendType8","SendType9","Cyclic","SendType1","SendType2","SendType3","SendType4","SendType5","SendType6","SendType7","SendType8","SendType9","Cyclic","SendType1","SendType2","SendType3","SendType4","SendType5","SendType6","SendType7","SendType8","SendType9","No","Yes","Cyclic","SendType1","SendType2","SendType3","SendType4","SendType5","SendType6","SendType7","SendType8","SendType9","Cyclic","SendType1","SendType2","SendType3","SendType4","SendType5","SendType6","SendType7","SendType8","SendType9","Cyclic","SendType1","SendType2","SendType3","SendType4","SendType5","SendType6","SendType7","SendType8","SendType9","No","Yes","Cyclic","SendType1","SendType2","SendType3","SendType4","SendType5","SendType6","SendType7","SendType8","SendType9","Cyclic","SendType1","SendType2","SendType3","SendType4","SendType5","SendType6","SendType7","SendType8","SendType9","No","Yes","Cyclic","SendType1","SendType2","SendType3","SendType4","SendType5","SendType6","SendType7","SendType8","SendType9","No","Yes","No","Yes","Cyclic","SendType1","SendType2","SendType3","SendType4","SendType5","SendType6","SendType7","SendType8","SendType9","Cyclic","SendType1","SendType2","SendType3","SendType4","SendType5","SendType6","SendType7","SendType8","SendType9","Cyclic","SendType1","SendType2","SendType3","SendType4","SendType5","SendType6","SendType7","SendType8","SendType9","Cyclic","SendType1","SendType2","SendType3","SendType4","SendType5","SendType6","SendType7","SendType8","SendType9","No","Yes","Cyclic","SendType1","SendType2","SendType3","SendType4","SendType5","SendType6","SendType7","SendType8","SendType9","Cyclic","SendType1","SendType2","SendType3","SendType4","SendType5","SendType6","SendType7","SendType8","SendType9","Cyclic","SendType1","SendType2","SendType3","SendType4","SendType5","SendType6","SendType7","SendType8","SendType9","No","Yes","Cyclic","SendType1","SendType2","SendType3","SendType4","SendType5","SendType6","SendType7","SendType8","SendType9","Cyclic","SendType1","SendType2","SendType3","SendType4","SendType5","SendType6","SendType7","SendType8","SendType9","No","Yes","Cyclic","SendType1","SendType2","SendType3","SendType4","SendType5","SendType6","SendType7","SendType8","SendType9","No","Yes","No","Yes","Cyclic","SendType1","SendType2","SendType3","SendType4","SendType5","SendType6","SendType7","SendType8","SendType9","Cyclic","SendType1","SendType2","SendType3","SendType4","SendType5","SendType6","SendType7","SendType8","SendType9","Cyclic","SendType1","SendType2","SendType3","SendType4","SendType5","SendType6","SendType7","SendType8","SendType9","No","Yes","Cyclic","SendType1","SendType2","SendType3","SendType4","SendType5","SendType6","SendType7","SendType8","SendType9","Cyclic","SendType1","SendType2","SendType3","SendType4","SendType5","SendType6","SendType7","SendType8","SendType9","No","Yes","Cyclic","SendType1","SendType2","SendType3","SendType4","SendType5","SendType6","SendType7","SendType8","SendType9","No","Yes","No","Yes","Cyclic","SendType1","SendType2","SendType3","SendType4","SendType5","SendType6","SendType7","SendType8","SendType9","Cyclic","SendType1","SendType2","SendType3","SendType4","SendType5","SendType6","SendType7","SendType8","SendType9","No","Yes","Cyclic","SendType1","SendType2","SendType3","SendType4","SendType5","SendType6","SendType7","SendType8","SendType9","No","Yes","No","Yes","Cyclic","SendType1","SendType2","SendType3","SendType4","SendType5","SendType6","SendType7","SendType8","SendType9","No","Yes","No","Yes","No","Yes","Cyclic","SendType1","SendType2","SendType3","SendType4","SendType5","SendType6","SendType7","SendType8","SendType9","Cyclic","SendType1","SendType2","SendType3","SendType4","SendType5","SendType6","SendType7","SendType8","SendType9","Cyclic","SendType1","SendType2","SendType3","SendType4","SendType5","SendType6","SendType7","SendType8","SendType9","Cyclic","SendType1","SendType2","SendType3","SendType4","SendType5","SendType6","SendType7","SendType8","SendType9","No","Yes","Cyclic","SendType1","SendType2","SendType3","SendType4","SendType5","SendType6","SendType7","SendType8","SendType9","Cyclic","SendType1","SendType2","SendType3","SendType4","SendType5","SendType6","SendType7","SendType8","SendType9","Cyclic","SendType1","SendType2","SendType3","SendType4","SendType5","SendType6","SendType7","SendType8","SendType9","No","Yes","Cyclic","SendType1","SendType2","SendType3","SendType4","SendType5","SendType6","SendType7","SendType8","SendType9","Cyclic","SendType1","SendType2","SendType3","SendType4","SendType5","SendType6","SendType7","SendType8","SendType9","No","Yes","Cyclic","SendType1","SendType2","SendType3","SendType4","SendType5","SendType6","SendType7","SendType8","SendType9","No","Yes","No","Yes","Cyclic","SendType1","SendType2","SendType3","SendType4","SendType5","SendType6","SendType7","SendType8","SendType9","Cyclic","SendType1","SendType2","SendType3","SendType4","SendType5","SendType6","SendType7","SendType8","SendType9","Cyclic","SendType1","SendType2","SendType3","SendType4","SendType5","SendType6","SendType7","SendType8","SendType9","No","Yes","Cyclic","SendType1","SendType2","SendType3","SendType4","SendType5","SendType6","SendType7","SendType8","SendType9","Cyclic","SendType1","SendType2","SendType3","SendType4","SendType5","SendType6","SendType7","SendType8","SendType9","No","Yes","Cyclic","SendType1","SendType2","SendType3","SendType4","SendType5","SendType6","SendType7","SendType8","SendType9","No","Yes","No","Yes","Cyclic","SendType1","SendType2","SendType3","SendType4","SendType5","SendType6","SendType7","SendType8","SendType9","Cyclic","SendType1","SendType2","SendType3","SendType4","SendType5","SendType6","SendType7","SendType8","SendType9","No","Yes","Cyclic","SendType1","SendType2","SendType3","SendType4","SendType5","SendType6","SendType7","SendType8","SendType9","No","Yes","No","Yes","Cyclic","SendType1","SendType2","SendType3","SendType4","SendType5","SendType6","SendType7","SendType8","SendType9","No","Yes","No","Yes","No","Yes","Cyclic","SendType1","SendType2","SendType3","SendType4","SendType5","SendType6","SendType7","SendType8","SendType9","Cyclic","SendType1","SendType2","SendType3","SendType4","SendType5","SendType6","SendType7","SendType8","SendType9","Cyclic","SendType1","SendType2","SendType3","SendType4","SendType5","SendType6","SendType7","SendType8","SendType9","No","Yes","Cyclic","SendType1","SendType2","SendType3","SendType4","SendType5","SendType6","SendType7","SendType8","SendType9","Cyclic","SendType1","SendType2","SendType3","SendType4","SendType5","SendType6","SendType7","SendType8","SendType9","No","Yes","Cyclic","SendType1","SendType2","SendType3","SendType4","SendType5","SendType6","SendType7","SendType8","SendType9","No","Yes","No","Yes","Cyclic","SendType1","SendType2","SendType3","SendType4","SendType5","SendType6","SendType7","SendType8","SendType9","Cyclic","SendType1","SendType2","SendType3","SendType4","SendType5","SendType6","SendType7","SendType8","SendType9","No","Yes","Cyclic","SendType1","SendType2","SendType3","SendType4","SendType5","SendType6","SendType7","SendType8","SendType9","No","Yes","No","Yes","Cyclic","SendType1","SendType2","SendType3","SendType4","SendType5","SendType6","SendType7","SendType8","SendType9","No","Yes","No","Yes","No","Yes","Cyclic","SendType1","SendType2","SendType3","SendType4","SendType5","SendType6","SendType7","SendType8","SendType9","Cyclic","SendType1","SendType2","SendType3","SendType4","SendType5","SendType6","SendType7","SendType8","SendType9","No","Yes","Cyclic","SendType1","SendType2","SendType3","SendType4","SendType5","SendType6","SendType7","SendType8","SendType9","No","Yes","No","Yes","Cyclic","SendType1","SendType2","SendType3","SendType4","SendType5","SendType6","SendType7","SendType8","SendType9","No","Yes","No","Yes","No","Yes","Cyclic","SendType1","SendType2","SendType3","SendType4","SendType5","SendType6","SendType7","SendType8","SendType9","No","Yes","No","Yes","No","Yes","No","Yes";
BA_DEF_ SG_ "GenSigEnvVarType" ENUM "Cyclic","SendType1","SendType2","SendType3","SendType4","SendType5","SendType6","SendType7","SendType8","SendType9","Cyclic","SendType1","SendType2","SendType3","SendType4","SendType5","SendType6","SendType7","SendType8","SendType9","Cyclic","SendType1","SendType2","SendType3","SendType4","SendType5","SendType6","SendType7","SendType8","SendType9","Cyclic","SendType1","SendType2","SendType3","SendType4","SendType5","SendType6","SendType7","SendType8","SendType9","Cyclic","SendType1","SendType2","SendType3","SendType4","SendType5","SendType6","SendType7","SendType8","SendType9","No","Yes","Cyclic","SendType1","SendType2","SendType3","SendType4","SendType5","SendType6","SendType7","SendType8","SendType9","Cyclic","SendType1","SendType2","SendType3","SendType4","SendType5","SendType6","SendType7","SendType8","SendType9","Cyclic","SendType1","SendType2","SendType3","SendType4","SendType5","SendType6","SendType7","SendType8","SendType9","Cyclic","SendType1","SendType2","SendType3","SendType4","SendType5","SendType6","SendType7","SendType8","SendType9","No","Yes","Cyclic","SendType1","SendType2","SendType3","SendType4","SendType5","SendType6","SendType7","SendType8","SendType9","Cyclic","SendType1","SendType2","SendType3","SendType4","SendType5","SendType6","SendType7","SendType8","SendType9","Cyclic","SendType1","SendType2","SendType3","SendType4","SendType5","SendType6","SendType7","SendType8","SendType9","No","Yes","Cyclic","SendType1","SendType2","SendType3","SendType4","SendType5","SendType6","SendType7","SendType8","SendType9","Cyclic","SendType1","SendType2","SendType3","SendType4","SendType5","SendType6","SendType7","SendType8","SendType9","No","Yes","Cyclic","SendType1","SendType2","SendType3","SendType4","SendType5","SendType6","SendType7","SendType8","SendType9","No","Yes","No","Yes","Cyclic","SendType1","SendType2","SendType3","SendType4","SendType5","SendType6","SendType7","SendType8","SendType9","Cyclic","SendType1","SendType2","SendType3","SendType4","SendType5","SendType6","SendType7","SendType8","SendType9","Cyclic","SendType1","SendType2","SendType3","SendType4","SendType5","SendType6","SendType7","SendType8","SendType9","Cyclic","SendType1","SendType2","SendType3","SendType4","SendType5","SendType6","SendType7","SendType8","SendType9","No","Yes","Cyclic","SendType1","SendType2","SendType3","SendType4","SendType5","SendType6","SendType7","SendType8","SendType9","Cyclic","SendType1","SendType2","SendType3","SendType4","SendType5","SendType6","SendType7","SendType8","SendType9","Cyclic","SendType1","SendType2","SendType3","SendType4","SendType5","SendType6","SendType7","SendType8","SendType9","No","Yes","Cyclic","SendType1","SendType2","SendType3","SendType4","SendType5","SendType6","SendType7","SendType8","SendType9","Cyclic","SendType1","SendType2","SendType3","SendType4","SendType5","SendType6","SendType7","SendType8","SendType9","No","Yes","Cyclic","SendType1","SendType2","SendType3","SendType4","SendType5","SendType6","SendType7","SendType8","SendType9","No","Yes","No","Yes","Cyclic","SendType1","SendType2","SendType3","SendType4","SendType5","SendType6","SendType7","SendType8","SendType9","Cyclic","SendType1","SendType2","SendType3","SendType4","SendType5","SendType6","SendType7","SendType8","SendType9","Cyclic","SendType1","SendType2","SendType3","SendType4","SendType5","SendType6","SendType7","SendType8","SendType9","No","Yes","Cyclic","SendType1","SendType2","SendType3","SendType4","SendType5","SendType6","SendType7","SendType8","SendType9","Cyclic","SendType1","SendType2","SendType3","SendType4","SendType5","SendType6","SendType7","SendType8","SendType9","No","Yes","Cyclic","SendType1","SendType2","SendType3","SendType4","SendType5","SendType6","SendType7","SendType8","SendType9","No","Yes","No","Yes","Cyclic","SendType1","SendType2","SendType3","SendType4","SendType5","SendType6","SendType7","SendType8","SendType9","Cyclic","SendType1","SendType2","SendType3","SendType4","SendType5","SendType6","SendType7","SendType8","SendType9","No","Yes","Cyclic","SendType1","SendType2","SendType3","SendType4","SendType5","SendType6","SendType7","SendType8","SendType9","No","Yes","No","Yes","Cyclic","SendType1","SendType2","SendType3","SendType4","SendType5","SendType6","SendType7","SendType8","SendType9","No","Yes","No","Yes","No","Yes","Cyclic","SendType1","SendType2","SendType3","SendType4","SendType5","SendType6","SendType7","SendType8","SendType9","Cyclic","SendType1","SendType2","SendType3","SendType4","SendType5","SendType6","SendType7","SendType8","SendType9","Cyclic","SendType1","SendType2","SendType3","SendType4","SendType5","SendType6","SendType7","SendType8","SendType9","Cyclic","SendType1","SendType2","SendType3","SendType4","SendType5","SendType6","SendType7","SendType8","SendType9","No","Yes","Cyclic","SendType1","SendType2","SendType3","SendType4","SendType5","SendType6","SendType7","SendType8","SendType9","Cyclic","SendType1","SendType2","SendType3","SendType4","SendType5","SendType6","SendType7","SendType8","SendType9","Cyclic","SendType1","SendType2","SendType3","SendType4","SendType5","SendType6","SendType7","SendType8","SendType9","No","Yes","Cyclic","SendType1","SendType2","SendType3","SendType4","SendType5","SendType6","SendType7","SendType8","SendType9","Cyclic","SendType1","SendType2","SendType3","SendType4","SendType5","SendType6","SendType7","SendType8","SendType9","No","Yes","Cyclic","SendType1","SendType2","SendType3","SendType4","SendType5","SendType6","SendType7","SendType8","SendType9","No","Yes","No","Yes","Cyclic","SendType1","SendType2","SendType3","SendType4","SendType5","SendType6","SendType7","SendType8","SendType9","Cyclic","SendType1","SendType2","SendType3","SendType4","SendType5","SendType6","SendType7","SendType8","SendType9","Cyclic","SendType1","SendType2","SendType3","SendType4","SendType5","SendType6","SendType7","SendType8","SendType9","No","Yes","Cyclic","SendType1","SendType2","SendType3","SendType4","SendType5","SendType6","SendType7","SendType8","SendType9","Cyclic","SendType1","SendType2","SendType3","SendType4","SendType5","SendType6","SendType7","SendType8","SendType9","No","Yes","Cyclic","SendType1","SendType2","SendType3","SendType4","SendType5","SendType6","SendType7","SendType8","SendType9","No","Yes","No","Yes","Cyclic","SendType1","SendType2","SendType3","SendType4","SendType5","SendType6","SendType7","SendType8","SendType9","Cyclic","SendType1","SendType2","SendType3","SendType4","SendType5","SendType6","SendType7","SendType8","SendType9","No","Yes","Cyclic","SendType1","SendType2","SendType3","SendType4","SendType5","SendType6","SendType7","SendType8","SendType9","No","Yes","No","Yes","Cyclic","SendType1","SendType2","SendType3","SendType4","SendType5","SendType6","SendType7","SendType8","SendType9","No","Yes","No","Yes","No","Yes","Cyclic","SendType1","SendType2","SendType3","SendType4","SendType5","SendType6","SendType7","SendType8","SendType9","Cyclic","SendType1","SendType2","SendType3","SendType4","SendType5","SendType6","SendType7","SendType8","SendType9","Cyclic","SendType1","SendType2","SendType3","SendType4","SendType5","SendType6","SendType7","SendType8","SendType9","No","Yes","Cyclic","SendType1","SendType2","SendType3","SendType4","SendType5","SendType6","SendType7","SendType8","SendType9","Cyclic","SendType1","SendType2","SendType3","SendType4","SendType5","SendType6","SendType7","SendType8","SendType9","No","Yes","Cyclic","SendType1","SendType2","SendType3","SendType4","SendType5","SendType6","SendType7","SendType8","SendType9","No","Yes","No","Yes","Cyclic","SendType1","SendType2","SendType3","SendType4","SendType5","SendType6","SendType7","SendType8","SendType9","Cyclic","SendType1","SendType2","SendType3","SendType4","SendType5","SendType6","SendType7","SendType8","SendType9","No","Yes","Cyclic","SendType1","SendType2","SendType3","SendType4","SendType5","SendType6","SendType7","SendType8","SendType9","No","Yes","No","Yes","Cyclic","SendType1","SendType2","SendType3","SendType4","SendType5","SendType6","SendType7","SendType8","SendType9","No","Yes","No","Yes","No","Yes","Cyclic","SendType1","SendType2","SendType3","SendType4","SendType5","SendType6","SendType7","SendType8","SendType9","Cyclic","SendType1","SendType2","SendType3","SendType4","SendType5","SendType6","SendType7","SendType8","SendType9","No","Yes","Cyclic","SendType1","SendType2","SendType3","SendType4","SendType5","SendType6","SendType7","SendType8","SendType9","No","Yes","No","Yes","Cyclic","SendType1","SendType2","SendType3","SendType4","SendType5","SendType6","SendType7","SendType8","SendType9","No","Yes","No","Yes","No","Yes","Cyclic","SendType1","SendType2","SendType3","SendType4","SendType5","SendType6","SendType7","SendType8","SendType9","No","Yes","No","Yes","No","Yes","No","Yes","Cyclic","SendType1","SendType2","SendType3","SendType4","SendType5","SendType6","SendType7","SendType8","SendType9","Cyclic","SendType1","SendType2","SendType3","SendType4","SendType5","SendType6","SendType7","SendType8","SendType9","Cyclic","SendType1","SendType2","SendType3","SendType4","SendType5","SendType6","SendType7","SendType8","SendType9","Cyclic","SendType1","SendType2","SendType3","SendType4","SendType5","SendType6","SendType7","SendType8","SendType9","No","Yes","Cyclic","SendType1","SendType2","SendType3","SendType4","SendType5","SendType6","SendType7","SendType8","SendType9","Cyclic","SendType1","SendType2","SendType3","SendType4","SendType5","SendType6","SendType7","SendType8","SendType9","Cyclic","SendType1","SendType2","SendType3","SendType4","SendType5","SendType6","SendType7","SendType8","SendType9","No","Yes","Cyclic","SendType1","SendType2","SendType3","SendType4","SendType5","SendType6","SendType7","SendType8","SendType9","Cyclic","SendType1","SendType2","SendType3","SendType4","SendType5","SendType6","SendType7","SendType8","SendType9","No","Yes","Cyclic","SendType1","SendType2","SendType3","SendType4","SendType5","SendType6","SendType7","SendType8","SendType9","No","Yes","No","Yes","Cyclic","SendType1","SendType2","SendType3","SendType4","SendType5","SendType6","SendType7","SendType8","SendType9","Cyclic","SendType1","SendType2","SendType3","SendType4","SendType5","SendType6","SendType7","SendType8","SendType9","Cyclic","SendType1","SendType2","SendType3","SendType4","SendType5","SendType6","SendType7","SendType8","SendType9","No","Yes","Cyclic","SendType1","SendType2","SendType3","SendType4","SendType5","SendType6","SendType7","SendType8","SendType9","Cyclic","SendType1","SendType2","SendType3","SendType4","SendType5","SendType6","SendType7","SendType8","SendType9","No","Yes","Cyclic","SendType1","SendType2","SendType3","SendType4","SendType5","SendType6","SendType7","SendType8","SendType9","No","Yes","No","Yes","Cyclic","SendType1","SendType2","SendType3","SendType4","SendType5","SendType6","SendType7","SendType8","SendType9","Cyclic","SendType1","SendType2","SendType3","SendType4","SendType5","SendType6","SendType7","SendType8","SendType9","No","Yes","Cyclic","SendType1","SendType2","SendType3","SendType4","SendType5","SendType6","SendType7","SendType8","SendType9","No","Yes","No","Yes","Cyclic","SendType1","SendType2","SendType3","SendType4","SendType5","SendType6","SendType7","SendType8","SendType9","No","Yes","No","Yes","No","Yes","Cyclic","SendType1","SendType2","SendType3","SendType4","SendType5","SendType6","SendType7","SendType8","SendType9","Cyclic","SendType1","SendType2","SendType3","SendType4","SendType5","SendType6","SendType7","SendType8","SendType9","Cyclic","SendType1","SendType2","SendType3","SendType4","SendType5","SendType6","SendType7","SendType8","SendType9","No","Yes","Cyclic","SendType1","SendType2","SendType3","SendType4","SendType5","SendType6","SendType7","SendType8","SendType9","Cyclic","SendType1","SendType2","SendType3","SendType4","SendType5","SendType6","SendType7","SendType8","SendType9","No","Yes","Cyclic","SendType1","SendType2","SendType3","SendType4","SendType5","SendType6","SendType7","SendType8","SendType9","No","Yes","No","Yes","Cyclic","SendType1","SendType2","SendType3","SendType4","SendType5","SendType6","SendType7","SendType8","SendType9","Cyclic","SendType1","SendType2","SendType3","SendType4","SendType5","SendType6","SendType7","SendType8","SendType9","No","Yes","Cyclic","SendType1","SendType2","SendType3","SendType4","SendType5","SendType6","SendType7","SendType8","SendType9","No","Yes","No","Yes","Cyclic","SendType1","SendType2","SendType3","SendType4","SendType5","SendType6","SendType7","SendType8","SendType9","No","Yes","No","Yes","No","Yes","Cyclic","SendType1","SendType2","SendType3","SendType4","SendType5","SendType6","SendType7","SendType8","SendType9","Cyclic","SendType1","SendType2","SendType3","SendType4","SendType5","SendType6","SendType7","SendType8","SendType9","No","Yes","Cyclic","SendType1","SendType2","SendType3","SendType4","SendType5","SendType6","SendType7","SendType8","SendType9","No","Yes","No","Yes","Cyclic","SendType1","SendType2","SendType3","SendType4","SendType5","SendType6","SendType7","SendType8","SendType9","No","Yes","No","Yes","No","Yes","Cyclic","SendType1","SendType2","SendType3","SendType4","SendType5","SendType6","SendType7","SendType8","SendType9","No","Yes","No","Yes","No","Yes","No","Yes","Cyclic","SendType1","SendType2","SendType3","SendType4","SendType5","SendType6","SendType7","SendType8","SendType9","Cyclic","SendType1","SendType2","SendType3","SendType4","SendType5","SendType6","SendType7","SendType8","SendType9","Cyclic","SendType1","SendType2","SendType3","SendType4","SendType5","SendType6","SendType7","SendType8","SendType9","No","Yes","Cyclic","SendType1","SendType2","SendType3","SendType4","SendType5","SendType6","SendType7","SendType8","SendType9","Cyclic","SendType1","SendType2","SendType3","SendType4","SendType5","SendType6","SendType7","SendType8","SendType9","No","Yes","Cyclic","SendType1","SendType2","SendType3","SendType4","SendType5","SendType6","SendType7","SendType8","SendType9","No","Yes","No","Yes","Cyclic","SendType1","SendType2","SendType3","SendType4","SendType5","SendType6","SendType7","SendType8","SendType9","Cyclic","SendType1","SendType2","SendType3","SendType4","SendType5","SendType6","SendType7","SendType8","SendType9","No","Yes","Cyclic","SendType1","SendType2","SendType3","SendType4","SendType5","SendType6","SendType7","SendType8","SendType9","No","Yes","No","Yes","Cyclic","SendType1","SendType2","SendType3","SendType4","SendType5","SendType6","SendType7","SendType8","SendType9","No","Yes","No","Yes","No","Yes","Cyclic","SendType1","SendType2","SendType3","SendType4","SendType5","SendType6","SendType7","SendType8","SendType9","Cyclic","SendType1","SendType2","SendType3","SendType4","SendType5","SendType6","SendType7","SendType8","SendType9","No","Yes","Cyclic","SendType1","SendType2","SendType3","SendType4","SendType5","SendType6","SendType7","SendType8","SendType9","No","Yes","No","Yes","Cyclic","SendType1","SendType2","SendType3","SendType4","SendType5","SendType6","SendType7","SendType8","SendType9","No","Yes","No","Yes","No","Yes","Cyclic","SendType1","SendType2","SendType3","SendType4","SendType5","SendType6","SendType7","SendType8","SendType9","No","Yes","No","Yes","No","Yes","No","Yes","Cyclic","SendType1","SendType2","SendType3","SendType4","SendType5","SendType6","SendType7","SendType8","SendType9","Cyclic","SendType1","SendType2","SendType3","SendType4","SendType5","SendType6","SendType7","SendType8","SendType9","No","Yes","Cyclic","SendType1","SendType2","SendType3","SendType4","SendType5","SendType6","SendType7","SendType8","SendType9","No","Yes","No","Yes","Cyclic","SendType1","SendType2","SendType3","SendType4","SendType5","SendType6","SendType7","SendType8","SendType9","No","Yes","No","Yes","No","Yes","Cyclic","SendType1","SendType2","SendType3","SendType4","SendType5","SendType6","SendType7","SendType8","SendType9","No","Yes","No","Yes","No","Yes","No","Yes","Cyclic","SendType1","SendType2","SendType3","SendType4","SendType5","SendType6","SendType7","SendType8","SendType9","No","Yes","No","Yes","No","Yes","No","Yes","int","float","undef";
BA_DEF_ BU_ "GenNodAutoGenSnd" ENUM "Cyclic","SendType1","SendType2","SendType3","SendType4","SendType5","SendType6","SendType7","SendType8","SendType9","Cyclic","SendType1","SendType2","SendType3","SendType4","SendType5","SendType6","SendType7","SendType8","SendType9","Cyclic","SendType1","SendType2","SendType3","SendType4","SendType5","SendType6","SendType7","SendType8","SendType9","Cyclic","SendType1","SendType2","SendType3","SendType4","SendType5","SendType6","SendType7","SendType8","SendType9","Cyclic","SendType1","SendType2","SendType3","SendType4","SendType5","SendType6","SendType7","SendType8","SendType9","No","Yes","Cyclic","SendType1","SendType2","SendType3","SendType4","SendType5","SendType6","SendType7","SendType8","SendType9","Cyclic","SendType1","SendType2","SendType3","SendType4","SendType5","SendType6","SendType7","SendType8","SendType9","Cyclic","SendType1","SendType2","SendType3","SendType4","SendType5","SendType6","SendType7","SendType8","SendType9","Cyclic","SendType1","SendType2","SendType3","SendType4","SendType5","SendType6","SendType7","SendType8","SendType9","No","Yes","Cyclic","SendType1","SendType2","SendType3","SendType4","SendType5","SendType6","SendType7","SendType8","SendType9","Cyclic","SendType1","SendType2","SendType3","SendType4","SendType5","SendType6","SendType7","SendType8","SendType9","Cyclic","SendType1","SendType2","SendType3","SendType4","SendType5","SendType6","SendType7","SendType8","SendType9","No","Yes","Cyclic","SendType1","SendType2","SendType3","SendType4","SendType5","SendType6","SendType7","SendType8","SendType9","Cyclic","SendType1","SendType2","SendType3","SendType4","SendType5","SendType6","SendType7","SendType8","SendType9","No","Yes","Cyclic","SendType1","SendType2","SendType3","SendType4","SendType5","SendType6","SendType7","SendType8","SendType9","No","Yes","No","Yes","Cyclic","SendType1","SendType2","SendType3","SendType4","SendType5","SendType6","SendType7","SendType8","SendType9","Cyclic","SendType1","SendType2","SendType3","SendType4","SendType5","SendType6","SendType7","SendType8","SendType9","Cyclic","SendType1","SendType2","SendType3","SendType4","SendType5","SendType6","SendType7","SendType8","SendType9","Cyclic","SendType1","SendType2","SendType3","SendType4","SendType5","SendType6","SendType7","SendType8","SendType9","No","Yes","Cyclic","SendType1","SendType2","SendType3","SendType4","SendType5","SendType6","SendType7","SendType8","SendType9","Cyclic","SendType1","SendType2","SendType3","SendType4","SendType5","SendType6","SendType7","SendType8","SendType9","Cyclic","SendType1","SendType2","SendType3","SendType4","SendType5","SendType6","SendType7","SendType8","SendType9","No","Yes","Cyclic","SendType1","SendType2","SendType3","SendType4","SendType5","SendType6","SendType7","SendType8","SendType9","Cyclic","SendType1","SendType2","SendType3","SendType4","SendType5","SendType6","SendType7","SendType8","SendType9","No","Yes","Cyclic","SendType1","SendType2","SendType3","SendType4","SendType5","SendType6","SendType7","SendType8","SendType9","No","Yes","No","Yes","Cyclic","SendType1","SendType2","SendType3","SendType4","SendType5","SendType6","SendType7","SendType8","SendType9","Cyclic","SendType1","SendType2","SendType3","SendType4","SendType5","SendType6","SendType7","SendType8","SendType9","Cyclic","SendType1","SendType2","SendType3","SendType4","SendType5","SendType6","SendType7","SendType8","SendType9","No","Yes","Cyclic","SendType1","SendType2","SendType3","SendType4","SendType5","SendType6","SendType7","SendType8","SendType9","Cyclic","SendType1","SendType2","SendType3","SendType4","SendType5","SendType6","SendType7","SendType8","SendType9","No","Yes","Cyclic","SendType1","SendType2","SendType3","SendType4","SendType5","SendType6","SendType7","SendType8","SendType9","No","Yes","No","Yes","Cyclic","SendType1","SendType2","SendType3","SendType4","SendType5","SendType6","SendType7","SendType8","SendType9","Cyclic","SendType1","SendType2","SendType3","SendType4","SendType5","SendType6","SendType7","SendType8","SendType9","No","Yes","Cyclic","SendType1","SendType2","SendType3","SendType4","SendType5","SendType6","SendType7","SendType8","SendType9","No","Yes","No","Yes","Cyclic","SendType1","SendType2","SendType3","SendType4","SendType5","SendType6","SendType7","SendType8","SendType9","No","Yes","No","Yes","No","Yes","Cyclic","SendType1","SendType2","SendType3","SendType4","SendType5","SendType6","SendType7","SendType8","SendType9","Cyclic","SendType1","SendType2","SendType3","SendType4","SendType5","SendType6","SendType7","SendType8","SendType9","Cyclic","SendType1","SendType2","SendType3","SendType4","SendType5","SendType6","SendType7","SendType8","SendType9","Cyclic","SendType1","SendType2","SendType3","SendType4","SendType5","SendType6","SendType7","SendType8","SendType9","No","Yes","Cyclic","SendType1","SendType2","SendType3","SendType4","SendType5","SendType6","SendType7","SendType8","SendType9","Cyclic","SendType1","SendType2","SendType3","SendType4","SendType5","SendType6","SendType7","SendType8","SendType9","Cyclic","SendType1","SendType2","SendType3","SendType4","SendType5","SendType6","SendType7","SendType8","SendType9","No","Yes","Cyclic","SendType1","SendType2","SendType3","SendType4","SendType5","SendType6","SendType7","SendType8","SendType9","Cyclic","SendType1","SendType2","SendType3","SendType4","SendType5","SendType6","SendType7","SendType8","SendType9","No","Yes","Cyclic","SendType1","SendType2","SendType3","SendType4","SendType5","SendType6","SendType7","SendType8","SendType9","No","Yes","No","Yes","Cyclic","SendType1","SendType2","SendType3","SendType4","SendType5","SendType6","SendType7","SendType8","SendType9","Cyclic","SendType1","SendType2","SendType3","SendType4","SendType5","SendType6","SendType7","SendType8","SendType9","Cyclic","SendType1","SendType2","SendType3","SendType4","SendType5","SendType6","SendType7","SendType8","SendType9","No","Yes","Cyclic","SendType1","SendType2","SendType3","SendType4","SendType5","SendType6","SendType7","SendType8","SendType9","Cyclic","SendType1","SendType2","SendType3","SendType4","SendType5","SendType6","SendType7","SendType8","SendType9","No","Yes","Cyclic","SendType1","SendType2","SendType3","SendType4","SendType5","SendType6","SendType7","SendType8","SendType9","No","Yes","No","Yes","Cyclic","SendType1","SendType2","SendType3","SendType4","SendType5","SendType6","SendType7","SendType8","SendType9","Cyclic","SendType1","SendType2","SendType3","SendType4","SendType5","SendType6","SendType7","SendType8","SendType9","No","Yes","Cyclic","SendType1","SendType2","SendType3","SendType4","SendType5","SendType6","SendType7","SendType8","SendType9","No","Yes","No","Yes","Cyclic","SendType1","SendType2","SendType3","SendType4","SendType5","SendType6","SendType7","SendType8","SendType9","No","Yes","No","Yes","No","Yes","Cyclic","SendType1","SendType2","SendType3","SendType4","SendType5","SendType6","SendType7","SendType8","SendType9","Cyclic","SendType1","SendType2","SendType3","SendType4","SendType5","SendType6","SendType7","SendType8","SendType9","Cyclic","SendType1","SendType2","SendType3","SendType4","SendType5","SendType6","SendType7","SendType8","SendType9","No","Yes","Cyclic","SendType1","SendType2","SendType3","SendType4","SendType5","SendType6","SendType7","SendType8","SendType9","Cyclic","SendType1","SendType2","SendType3","SendType4","SendType5","SendType6","SendType7","SendType8","SendType9","No","Yes","Cyclic","SendType1","SendType2","SendType3","SendType4","SendType5","SendType6","SendType7","SendType8","SendType9","No","Yes","No","Yes","Cyclic","SendType1","SendType2","SendType3","SendType4","SendType5","SendType6","SendType7","SendType8","SendType9","Cyclic","SendType1","SendType2","SendType3","SendType4","SendType5","SendType6","SendType7","SendType8","SendType9","No","Yes","Cyclic","SendType1","SendType2","SendType3","SendType4","SendType5","SendType6","SendType7","SendType8","SendType9","No","Yes","No","Yes","Cyclic","SendType1","SendType2","SendType3","SendType4","SendType5","SendType6","SendType7","SendType8","SendType9","No","Yes","No","Yes","No","Yes","Cyclic","SendType1","SendType2","SendType3","SendType4","SendType5","SendType6","SendType7","SendType8","SendType9","Cyclic","SendType1","SendType2","SendType3","SendType4","SendType5","SendType6","SendType7","SendType8","SendType9","No","Yes","Cyclic","SendType1","SendType2","SendType3","SendType4","SendType5","SendType6","SendType7","SendType8","SendType9","No","Yes","No","Yes","Cyclic","SendType1","SendType2","SendType3","SendType4","SendType5","SendType6","SendType7","SendType8","SendType9","No","Yes","No","Yes","No","Yes","Cyclic","SendType1","SendType2","SendType3","SendType4","SendType5","SendType6","SendType7","SendType8","SendType9","No","Yes","No","Yes","No","Yes","No","Yes","Cyclic","SendType1","SendType2","SendType3","SendType4","SendType5","SendType6","SendType7","SendType8","SendType9","Cyclic","SendType1","SendType2","SendType3","SendType4","SendType5","SendType6","SendType7","SendType8","SendType9","Cyclic","SendType1","SendType2","SendType3","SendType4","SendType5","SendType6","SendType7","SendType8","SendType9","Cyclic","SendType1","SendType2","SendType3","SendType4","SendType5","SendType6","SendType7","SendType8","SendType9","No","Yes","Cyclic","SendType1","SendType2","SendType3","SendType4","SendType5","SendType6","SendType7","SendType8","SendType9","Cyclic","SendType1","SendType2","SendType3","SendType4","SendType5","SendType6","SendType7","SendType8","SendType9","Cyclic","SendType1","SendType2","SendType3","SendType4","SendType5","SendType6","SendType7","SendType8","SendType9","No","Yes","Cyclic","SendType1","SendType2","SendType3","SendType4","SendType5","SendType6","SendType7","SendType8","SendType9","Cyclic","SendType1","SendType2","SendType3","SendType4","SendType5","SendType6","SendType7","SendType8","SendType9","No","Yes","Cyclic","SendType1","SendType2","SendType3","SendType4","SendType5","SendType6","SendType7","SendType8","SendType9","No","Yes","No","Yes","Cyclic","SendType1","SendType2","SendType3","SendType4","SendType5","SendType6","SendType7","SendType8","SendType9","Cyclic","SendType1","SendType2","SendType3","SendType4","SendType5","SendType6","SendType7","SendType8","SendType9","Cyclic","SendType1","SendType2","SendType3","SendType4","SendType5","SendType6","SendType7","SendType8","SendType9","No","Yes","Cyclic","SendType1","SendType2","SendType3","SendType4","SendType5","SendType6","SendType7","SendType8","SendType9","Cyclic","SendType1","SendType2","SendType3","SendType4","SendType5","SendType6","SendType7","SendType8","SendType9","No","Yes","Cyclic","SendType1","SendType2","SendType3","SendType4","SendType5","SendType6","SendType7","SendType8","SendType9","No","Yes","No","Yes","Cyclic","SendType1","SendType2","SendType3","SendType4","SendType5","SendType6","SendType7","SendType8","SendType9","Cyclic","SendType1","SendType2","SendType3","SendType4","SendType5","SendType6","SendType7","SendType8","SendType9","No","Yes","Cyclic","SendType1","SendType2","SendType3","SendType4","SendType5","SendType6","SendType7","SendType8","SendType9","No","Yes","No","Yes","Cyclic","SendType1","SendType2","SendType3","SendType4","SendType5","SendType6","SendType7","SendType8","SendType9","No","Yes","No","Yes","No","Yes","Cyclic","SendType1","SendType2","SendType3","SendType4","SendType5","SendType6","SendType7","SendType8","SendType9","Cyclic","SendType1","SendType2","SendType3","SendType4","SendType5","SendType6","SendType7","SendType8","SendType9","Cyclic","SendType1","SendType2","SendType3","SendType4","SendType5","SendType6","SendType7","SendType8","SendType9","No","Yes","Cyclic","SendType1","SendType2","SendType3","SendType4","SendType5","SendType6","SendType7","SendType8","SendType9","Cyclic","SendType1","SendType2","SendType3","SendType4","SendType5","SendType6","SendType7","SendType8","SendType9","No","Yes","Cyclic","SendType1","SendType2","SendType3","SendType4","SendType5","SendType6","SendType7","SendType8","SendType9","No","Yes","No","Yes","Cyclic","SendType1","SendType2","SendType3","SendType4","SendType5","SendType6","SendType7","SendType8","SendType9","Cyclic","SendType1","SendType2","SendType3","SendType4","SendType5","SendType6","SendType7","SendType8","SendType9","No","Yes","Cyclic","SendType1","SendType2","SendType3","SendType4","SendType5","SendType6","SendType7","SendType8","SendType9","No","Yes","No","Yes","Cyclic","SendType1","SendType2","SendType3","SendType4","SendType5","SendType6","SendType7","SendType8","SendType9","No","Yes","No","Yes","No","Yes","Cyclic","SendType1","SendType2","SendType3","SendType4","SendType5","SendType6","SendType7","SendType8","SendType9","Cyclic","SendType1","SendType2","SendType3","SendType4","SendType5","SendType6","SendType7","SendType8","SendType9","No","Yes","Cyclic","SendType1","SendType2","SendType3","SendType4","SendType5","SendType6","SendType7","SendType8","SendType9","No","Yes","No","Yes","Cyclic","SendType1","SendType2","SendType3","SendType4","SendType5","SendType6","SendType7","SendType8","SendType9","No","Yes","No","Yes","No","Yes","Cyclic","SendType1","SendType2","SendType3","SendType4","SendType5","SendType6","SendType7","SendType8","SendType9","No","Yes","No","Yes","No","Yes","No","Yes","Cyclic","SendType1","SendType2","SendType3","SendType4","SendType5","SendType6","SendType7","SendType8","SendType9","Cyclic","SendType1","SendType2","SendType3","SendType4","SendType5","SendType6","SendType7","SendType8","SendType9","Cyclic","SendType1","SendType2","SendType3","SendType4","SendType5","SendType6","SendType7","SendType8","SendType9","No","Yes","Cyclic","SendType1","SendType2","SendType3","SendType4","SendType5","SendType6","SendType7","SendType8","SendType9","Cyclic","SendType1","SendType2","SendType3","SendType4","SendType5","SendType6","SendType7","SendType8","SendType9","No","Yes","Cyclic","SendType1","SendType2","SendType3","SendType4","SendType5","SendType6","SendType7","SendType8","SendType9","No","Yes","No","Yes","Cyclic","SendType1","SendType2","SendType3","SendType4","SendType5","SendType6","SendType7","SendType8","SendType9","Cyclic","SendType1","SendType2","SendType3","SendType4","SendType5","SendType6","SendType7","SendType8","SendType9","No","Yes","Cyclic","SendType1","SendType2","SendType3","SendType4","SendType5","SendType6","SendType7","SendType8","SendType9","No","Yes","No","Yes","Cyclic","SendType1","SendType2","SendType3","SendType4","SendType5","SendType6","SendType7","SendType8","SendType9","No","Yes","No","Yes","No","Yes","Cyclic","SendType1","SendType2","SendType3","SendType4","SendType5","SendType6","SendType7","SendType8","SendType9","Cyclic","SendType1","SendType2","SendType3","SendType4","SendType5","SendType6","SendType7","SendType8","SendType9","No","Yes","Cyclic","SendType1","SendType2","SendType3","SendType4","SendType5","SendType6","SendType7","SendType8","SendType9","No","Yes","No","Yes","Cyclic","SendType1","SendType2","SendType3","SendType4","SendType5","SendType6","SendType7","SendType8","SendType9","No","Yes","No","Yes","No","Yes","Cyclic","SendType1","SendType2","SendType3","SendType4","SendType5","SendType6","SendType7","SendType8","SendType9","No","Yes","No","Yes","No","Yes","No","Yes","Cyclic","SendType1","SendType2","SendType3","SendType4","SendType5","SendType6","SendType7","SendType8","SendType9","Cyclic","SendType1","SendType2","SendType3","SendType4","SendType5","SendType6","SendType7","SendType8","SendType9","No","Yes","Cyclic","SendType1","SendType2","SendType3","SendType4","SendType5","SendType6","SendType7","SendType8","SendType9","No","Yes","No","Yes","Cyclic","SendType1","SendType2","SendType3","SendType4","SendType5","SendType6","SendType7","SendType8","SendType9","No","Yes","No","Yes","No","Yes","Cyclic","SendType1","SendType2","SendType3","SendType4","SendType5","SendType6","SendType7","SendType8","SendType9","No","Yes","No","Yes","No","Yes","No","Yes","Cyclic","SendType1","SendType2","SendType3","SendType4","SendType5","SendType6","SendType7","SendType8","SendType9","No","Yes","No","Yes","No","Yes","No","Yes","int","float","undef","Cyclic","SendType1","SendType2","SendType3","SendType4","SendType5","SendType6","SendType7","SendType8","SendType9","Cyclic","SendType1","SendType2","SendType3","SendType4","SendType5","SendType6","SendType7","SendType8","SendType9","Cyclic","SendType1","SendType2","SendType3","SendType4","SendType5","SendType6","SendType7","SendType8","SendType9","Cyclic","SendType1","SendType2","SendType3","SendType4","SendType5","SendType6","SendType7","SendType8","SendType9","No","Yes","Cyclic","SendType1","SendType2","SendType3","SendType4","SendType5","SendType6","SendType7","SendType8","SendType9","Cyclic","SendType1","SendType2","SendType3","SendType4","SendType5","SendType6","SendType7","SendType8","SendType9","Cyclic","SendType1","SendType2","SendType3","SendType4","SendType5","SendType6","SendType7","SendType8","SendType9","No","Yes","Cyclic","SendType1","SendType2","SendType3","SendType4","SendType5","SendType6","SendType7","SendType8","SendType9","Cyclic","SendType1","SendType2","SendType3","SendType4","SendType5","SendType6","SendType7","SendType8","SendType9","No","Yes","Cyclic","SendType1","SendType2","SendType3","SendType4","SendType5","SendType6","SendType7","SendType8","SendType9","No","Yes","No","Yes","Cyclic","SendType1","SendType2","SendType3","SendType4","SendType5","SendType6","SendType7","SendType8","SendType9","Cyclic","SendType1","SendType2","SendType3","SendType4","SendType5","SendType6","SendType7","SendType8","SendType9","Cyclic","SendType1","SendType2","SendType3","SendType4","SendType5","SendType6","SendType7","SendType8","SendType9","No","Yes","Cyclic","SendType1","SendType2","SendType3","SendType4","SendType5","SendType6","SendType7","SendType8","SendType9","Cyclic","SendType1","SendType2","SendType3","SendType4","SendType5","SendType6","SendType7","SendType8","SendType9","No","Yes","Cyclic","SendType1","SendType2","SendType3","SendType4","SendType5","SendType6","SendType7","SendType8","SendType9","No","Yes","No","Yes","Cyclic","SendType1","SendType2","SendType3","SendType4","SendType5","SendType6","SendType7","SendType8","SendType9","Cyclic","SendType1","SendType2","SendType3","SendType4","SendType5","SendType6","SendType7","SendType8","SendType9","No","Yes","Cyclic","SendType1","SendType2","SendType3","SendType4","SendType5","SendType6","SendType7","SendType8","SendType9","No","Yes","No","Yes","Cyclic","SendType1","SendType2","SendType3","SendType4","SendType5","SendType6","SendType7","SendType8","SendType9","No","Yes","No","Yes","No","Yes","Cyclic","SendType1","SendType2","SendType3","SendType4","SendType5","SendType6","SendType7","SendType8","SendType9","Cyclic","SendType1","SendType2","SendType3","SendType4","SendType5","SendType6","SendType7","SendType8","SendType9","Cyclic","SendType1","SendType2","SendType3","SendType4","SendType5","SendType6","SendType7","SendType8","SendType9","No","Yes","Cyclic","SendType1","SendType2","SendType3","SendType4","SendType5","SendType6","SendType7","SendType8","SendType9","Cyclic","SendType1","SendType2","SendType3","SendType4","SendType5","SendType6","SendType7","SendType8","SendType9","No","Yes","Cyclic","SendType1","SendType2","SendType3","SendType4","SendType5","SendType6","SendType7","SendType8","SendType9","No","Yes","No","Yes","Cyclic","SendType1","SendType2","SendType3","SendType4","SendType5","SendType6","SendType7","SendType8","SendType9","Cyclic","SendType1","SendType2","SendType3","SendType4","SendType5","SendType6","SendType7","SendType8","SendType9","No","Yes","Cyclic","SendType1","SendType2","SendType3","SendType4","SendType5","SendType6","SendType7","SendType8","SendType9","No","Yes","No","Yes","Cyclic","SendType1","SendType2","SendType3","SendType4","SendType5","SendType6","SendType7","SendType8","SendType9","No","Yes","No","Yes","No","Yes","Cyclic","SendType1","SendType2","SendType3","SendType4","SendType5","SendType6","SendType7","SendType8","SendType9","Cyclic","SendType1","SendType2","SendType3","SendType4","SendType5","SendType6","SendType7","SendType8","SendType9","No","Yes","Cyclic","SendType1","SendType2","SendType3","SendType4","SendType5","SendType6","SendType7","SendType8","SendType9","No","Yes","No","Yes","Cyclic","SendType1","SendType2","SendType3","SendType4","SendType5","SendType6","SendType7","SendType8","SendType9","No","Yes","No","Yes","No","Yes","Cyclic","SendType1","SendType2","SendType3","SendType4","SendType5","SendType6","SendType7","SendType8","SendType9","No","Yes","No","Yes","No","Yes","No","Yes","Cyclic","SendType1","SendType2","SendType3","SendType4","SendType5","SendType6","SendType7","SendType8","SendType9","Cyclic","SendType1","SendType2","SendType3","SendType4","SendType5","SendType6","SendType7","SendType8","SendType9","Cyclic","SendType1","SendType2","SendType3","SendType4","SendType5","SendType6","SendType7","SendType8","SendType9","No","Yes","Cyclic","SendType1","SendType2","SendType3","SendType4","SendType5","SendType6","SendType7","SendType8","SendType9","Cyclic","SendType1","SendType2","SendType3","SendType4","SendType5","SendType6","SendType7","SendType8","SendType9","No","Yes","Cyclic","SendType1","SendType2","SendType3","SendType4","SendType5","SendType6","SendType7","SendType8","SendType9","No","Yes","No","Yes","Cyclic","SendType1","SendType2","SendType3","SendType4","SendType5","SendType6","SendType7","SendType8","SendType9","Cyclic","SendType1","SendType2","SendType3","SendType4","SendType5","SendType6","SendType7","SendType8","SendType9","No","Yes","Cyclic","SendType1","SendType2","SendType3","SendType4","SendType5","SendType6","SendType7","SendType8","SendType9","No","Yes","No","Yes","Cyclic","SendType1","SendType2","SendType3","SendType4","SendType5","SendType6","SendType7","SendType8","SendType9","No","Yes","No","Yes","No","Yes","Cyclic","SendType1","SendType2","SendType3","SendType4","SendType5","SendType6","SendType7","SendType8","SendType9","Cyclic","SendType1","SendType2","SendType3","SendType4","SendType5","SendType6","SendType7","SendType8","SendType9","No","Yes","Cyclic","SendType1","SendType2","SendType3","SendType4","SendType5","SendType6","SendType7","SendType8","SendType9","No","Yes","No","Yes","Cyclic","SendType1","SendType2","SendType3","SendType4","SendType5","SendType6","SendType7","SendType8","SendType9","No","Yes","No","Yes","No","Yes","Cyclic","SendType1","SendType2","SendType3","SendType4","SendType5","SendType6","SendType7","SendType8","SendType9","No","Yes","No","Yes","No","Yes","No","Yes","Cyclic","SendType1","SendType2","SendType3","SendType4","SendType5","SendType6","SendType7","SendType8","SendType9","Cyclic","SendType1","SendType2","SendType3","SendType4","SendType5","SendType6","SendType7","SendType8","SendType9","No","Yes","Cyclic","SendType1","SendType2","SendType3","SendType4","SendType5","SendType6","SendType7","SendType8","SendType9","No","Yes","No","Yes","Cyclic","SendType1","SendType2","SendType3","SendType4","SendType5","SendType6","SendType7","SendType8","SendType9","No","Yes","No","Yes","No","Yes","Cyclic","SendType1","SendType2","SendType3","SendType4","SendType5","SendType6","SendType7","SendType8","SendType9","No","Yes","No","Yes","No","Yes","No","Yes","Cyclic","SendType1","SendType2","SendType3","SendType4","SendType5","SendType6","SendType7","SendType8","SendType9","No","Yes","No","Yes","No","Yes","No","Yes","int","float","undef","Cyclic","SendType1","SendType2","SendType3","SendType4","SendType5","SendType6","SendType7","SendType8","SendType9","Cyclic","SendType1","SendType2","SendType3","SendType4","SendType5","SendType6","SendType7","SendType8","SendType9","Cyclic","SendType1","SendType2","SendType3","SendType4","SendType5","SendType6","SendType7","SendType8","SendType9","No","Yes","Cyclic","SendType1","SendType2","SendType3","SendType4","SendType5","SendType6","SendType7","SendType8","SendType9","Cyclic","SendType1","SendType2","SendType3","SendType4","SendType5","SendType6","SendType7","SendType8","SendType9","No","Yes","Cyclic","SendType1","SendType2","SendType3","SendType4","SendType5","SendType6","SendType7","SendType8","SendType9","No","Yes","No","Yes","Cyclic","SendType1","SendType2","SendType3","SendType4","SendType5","SendType6","SendType7","SendType8","SendType9","Cyclic","SendType1","SendType2","SendType3","SendType4","SendType5","SendType6","SendType7","SendType8","SendType9","No","Yes","Cyclic","SendType1","SendType2","SendType3","SendType4","SendType5","SendType6","SendType7","SendType8","SendType9","No","Yes","No","Yes","Cyclic","SendType1","SendType2","SendType3","SendType4","SendType5","SendType6","SendType7","SendType8","SendType9","No","Yes","No","Yes","No","Yes","Cyclic","SendType1","SendType2","SendType3","SendType4","SendType5","SendType6","SendType7","SendType8","SendType9","Cyclic","SendType1","SendType2","SendType3","SendType4","SendType5","SendType6","SendType7","SendType8","SendType9","No","Yes","Cyclic","SendType1","SendType2","SendType3","SendType4","SendType5","SendType6","SendType7","SendType8","SendType9","No","Yes","No","Yes","Cyclic","SendType1","SendType2","SendType3","SendType4","SendType5","SendType6","SendType7","SendType8","SendType9","No","Yes","No","Yes","No","Yes","Cyclic","SendType1","SendType2","SendType3","SendType4","SendType5","SendType6","SendType7","SendType8","SendType9","No","Yes","No","Yes","No","Yes","No","Yes","Cyclic","SendType1","SendType2","SendType3","SendType4","SendType5","SendType6","SendType7","SendType8","SendType9","Cyclic","SendType1","SendType2","SendType3","SendType4","SendType5","SendType6","SendType7","SendType8","SendType9","No","Yes","Cyclic","SendType1","SendType2","SendType3","SendType4","SendType5","SendType6","SendType7","SendType8","SendType9","No","Yes","No","Yes","Cyclic","SendType1","SendType2","SendType3","SendType4","SendType5","SendType6","SendType7","SendType8","SendType9","No","Yes","No","Yes","No","Yes","Cyclic","SendType1","SendType2","SendType3","SendType4","SendType5","SendType6","SendType7","SendType8","SendType9","No","Yes","No","Yes","No","Yes","No","Yes","Cyclic","SendType1","SendType2","SendType3","SendType4","SendType5","SendType6","SendType7","SendType8","SendType9","No","Yes","No","Yes","No","Yes","No","Yes","int","float","undef","Cyclic","SendType1","SendType2","SendType3","SendType4","SendType5","SendType6","SendType7","SendType8","SendType9","Cyclic","SendType1","SendType2","SendType3","SendType4","SendType5","SendType6","SendType7","SendType8","SendType9","No","Yes","Cyclic","SendType1","SendType2","SendType3","SendType4","SendType5","SendType6","SendType7","SendType8","SendType9","No","Yes","No","Yes","Cyclic","SendType1","SendType2","SendType3","SendType4","SendType5","SendType6","SendType7","SendType8","SendType9","No","Yes","No","Yes","No","Yes","Cyclic","SendType1","SendType2","SendType3","SendType4","SendType5","SendType6","SendType7","SendType8","SendType9","No","Yes","No","Yes","No","Yes","No","Yes","Cyclic","SendType1","SendType2","SendType3","SendType4","SendType5","SendType6","SendType7","SendType8","SendType9","No","Yes","No","Yes","No","Yes","No","Yes","int","float","undef","Cyclic","SendType1","SendType2","SendType3","SendType4","SendType5","SendType6","SendType7","SendType8","SendType9","No","Yes","No","Yes","No","Yes","No","Yes","int","float","undef","No","Yes";
BA_DEF_ BU_ "GenNodAutoGenDsp" ENUM "Cyclic","SendType1","SendType2","SendType3","SendType4","SendType5","SendType6","SendType7","SendType8","SendType9","Cyclic","SendType1","SendType2","SendType3","SendType4","SendType5","SendType6","SendType7","SendType8","SendType9","Cyclic","SendType1","SendType2","SendType3","SendType4","SendType5","SendType6","SendType7","SendType8","SendType9","Cyclic","SendType1","SendType2","SendType3","SendType4","SendType5","SendType6","SendType7","SendType8","SendType9","Cyclic","SendType1","SendType2","SendType3","SendType4","SendType5","SendType6","SendType7","SendType8","SendType9","No","Yes","Cyclic","SendType1","SendType2","SendType3","SendType4","SendType5","SendType6","SendType7","SendType8","SendType9","Cyclic","SendType1","SendType2","SendType3","SendType4","SendType5","SendType6","SendType7","SendType8","SendType9","Cyclic","SendType1","SendType2","SendType3","SendType4","SendType5","SendType6","SendType7","SendType8","SendType9","Cyclic","SendType1","SendType2","SendType3","SendType4","SendType5","SendType6","SendType7","SendType8","SendType9","No","Yes","Cyclic","SendType1","SendType2","SendType3","SendType4","SendType5","SendType6","SendType7","SendType8","SendType9","Cyclic","SendType1","SendType2","SendType3","SendType4","SendType5","SendType6","SendType7","SendType8","SendType9","Cyclic","SendType1","SendType2","SendType3","SendType4","SendType5","SendType6","SendType7","SendType8","SendType9","No","Yes","Cyclic","SendType1","SendType2","SendType3","SendType4","SendType5","SendType6","SendType7","SendType8","SendType9","Cyclic","SendType1","SendType2","SendType3","SendType4","SendType5","SendType6","SendType7","SendType8","SendType9","No","Yes","Cyclic","SendType1","SendType2","SendType3","SendType4","SendType5","SendType6","SendType7","SendType8","SendType9","No","Yes","No","Yes","Cyclic","SendType1","SendType2","SendType3","SendType4","SendType5","SendType6","SendType7","SendType8","SendType9","Cyclic","SendType1","SendType2","SendType3","SendType4","SendType5","SendType6","SendType7","SendType8","SendType9","Cyclic","SendType1","SendType2","SendType3","SendType4","SendType5","SendType6","SendType7","SendType8","SendType9","Cyclic","SendType1","SendType2","SendType3","SendType4","SendType5","SendType6","SendType7","SendType8","SendType9","No","Yes","Cyclic","SendType1","SendType2","SendType3","SendType4","SendType5","SendType6","SendType7","SendType8","SendType9","Cyclic","SendType1","SendType2","SendType3","SendType4","SendType5","SendType6","SendType7","SendType8","SendType9","Cyclic","SendType1","SendType2","SendType3","SendType4","SendType5","SendType6","SendType7","SendType8","SendType9","No","Yes","Cyclic","SendType1","SendType2","SendType3","SendType4","SendType5","SendType6","SendType7","SendType8","SendType9","Cyclic","SendType1","SendType2","SendType3","SendType4","SendType5","SendType6","SendType7","SendType8","SendType9","No","Yes","Cyclic","SendType1","SendType2","SendType3","SendType4","SendType5","SendType6","SendType7","SendType8","SendType9","No","Yes","No","Yes","Cyclic","SendType1","SendType2","SendType3","SendType4","SendType5","SendType6","SendType7","SendType8","SendType9","Cyclic","SendType1","SendType2","SendType3","SendType4","SendType5","SendType6","SendType7","SendType8","SendType9","Cyclic","SendType1","SendType2","SendType3","SendType4","SendType5","SendType6","SendType7","SendType8","SendType9","No","Yes","Cyclic","SendType1","SendType2","SendType3","SendType4","SendType5","SendType6","SendType7","SendType8","SendType9","Cyclic","SendType1","SendType2","SendType3","SendType4","SendType5","SendType6","SendType7","SendType8","SendType9","No","Yes","Cyclic","SendType1","SendType2","SendType3","SendType4","SendType5","SendType6","SendType7","SendType8","SendType9","No","Yes","No","Yes","Cyclic","SendType1","SendType2","SendType3","SendType4","SendType5","SendType6","SendType7","SendType8","SendType9","Cyclic","SendType1","SendType2","SendType3","SendType4","SendType5","SendType6","SendType7","SendType8","SendType9","No","Yes","Cyclic","SendType1","SendType2","SendType3","SendType4","SendType5","SendType6","SendType7","SendType8","SendType9","No","Yes","No","Yes","Cyclic","SendType1","SendType2","SendType3","SendType4","SendType5","SendType6","SendType7","SendType8","SendType9","No","Yes","No","Yes","No","Yes","Cyclic","SendType1","SendType2","SendType3","SendType4","SendType5","SendType6","SendType7","SendType8","SendType9","Cyclic","SendType1","SendType2","SendType3","SendType4","SendType5","SendType6","SendType7","SendType8","SendType9","Cyclic","SendType1","SendType2","SendType3","SendType4","SendType5","SendType6","SendType7","SendType8","SendType9","Cyclic","SendType1","SendType2","SendType3","SendType4","SendType5","SendType6","SendType7","SendType8","SendType9","No","Yes","Cyclic","SendType1","SendType2","SendType3","SendType4","SendType5","SendType6","SendType7","SendType8","SendType9","Cyclic","SendType1","SendType2","SendType3","SendType4","SendType5","SendType6","SendType7","SendType8","SendType9","Cyclic","SendType1","SendType2","SendType3","SendType4","SendType5","SendType6","SendType7","SendType8","SendType9","No","Yes","Cyclic","SendType1","SendType2","SendType3","SendType4","SendType5","SendType6","SendType7","SendType8","SendType9","Cyclic","SendType1","SendType2","SendType3","SendType4","SendType5","SendType6","SendType7","SendType8","SendType9","No","Yes","Cyclic","SendType1","SendType2","SendType3","SendType4","SendType5","SendType6","SendType7","SendType8","SendType9","No","Yes","No","Yes","Cyclic","SendType1","SendType2","SendType3","SendType4","SendType5","SendType6","SendType7","SendType8","SendType9","Cyclic","SendType1","SendType2","SendType3","SendType4","SendType5","SendType6","SendType7","SendType8","SendType9","Cyclic","SendType1","SendType2","SendType3","SendType4","SendType5","SendType6","SendType7","SendType8","SendType9","No","Yes","Cyclic","SendType1","SendType2","SendType3","SendType4","SendType5","SendType6","SendType7","SendType8","SendType9","Cyclic","SendType1","SendType2","SendType3","SendType4","SendType5","SendType6","SendType7","SendType8","SendType9","No","Yes","Cyclic","SendType1","SendType2","SendType3","SendType4","SendType5","SendType6","SendType7","SendType8","SendType9","No","Yes","No","Yes","Cyclic","SendType1","SendType2","SendType3","SendType4","SendType5","SendType6","SendType7","SendType8","SendType9","Cyclic","SendType1","SendType2","SendType3","SendType4","SendType5","SendType6","SendType7","SendType8","SendType9","No","Yes","Cyclic","SendType1","SendType2","SendType3","SendType4","SendType5","SendType6","SendType7","SendType8","SendType9","No","Yes","No","Yes","Cyclic","SendType1","SendType2","SendType3","SendType4","SendType5","SendType6","SendType7","SendType8","SendType9","No","Yes","No","Yes","No","Yes","Cyclic","SendType1","SendType2","SendType3","SendType4","SendType5","SendType6","SendType7","SendType8","SendType9","Cyclic","SendType1","SendType2","SendType3","SendType4","SendType5","SendType6","SendType7","SendType8","SendType9","Cyclic","SendType1","SendType2","SendType3","SendType4","SendType5","SendType6","SendType7","SendType8","SendType9","No","Yes","Cyclic","SendType1","SendType2","SendType3","SendType4","SendType5","SendType6","SendType7","SendType8","SendType9","Cyclic","SendType1","SendType2","SendType3","SendType4","SendType5","SendType6","SendType7","SendType8","SendType9","No","Yes","Cyclic","SendType1","SendType2","SendType3","SendType4","SendType5","SendType6","SendType7","SendType8","SendType9","No","Yes","No","Yes","Cyclic","SendType1","SendType2","SendType3","SendType4","SendType5","SendType6","SendType7","SendType8","SendType9","Cyclic","SendType1","SendType2","SendType3","SendType4","SendType5","SendType6","SendType7","SendType8","SendType9","No","Yes","Cyclic","SendType1","SendType2","SendType3","SendType4","SendType5","SendType6","SendType7","SendType8","SendType9","No","Yes","No","Yes","Cyclic","SendType1","SendType2","SendType3","SendType4","SendType5","SendType6","SendType7","SendType8","SendType9","No","Yes","No","Yes","No","Yes","Cyclic","SendType1","SendType2","SendType3","SendType4","SendType5","SendType6","SendType7","SendType8","SendType9","Cyclic","SendType1","SendType2","SendType3","SendType4","SendType5","SendType6","SendType7","SendType8","SendType9","No","Yes","Cyclic","SendType1","SendType2","SendType3","SendType4","SendType5","SendType6","SendType7","SendType8","SendType9","No","Yes","No","Yes","Cyclic","SendType1","SendType2","SendType3","SendType4","SendType5","SendType6","SendType7","SendType8","SendType9","No","Yes","No","Yes","No","Yes","Cyclic","SendType1","SendType2","SendType3","SendType4","SendType5","SendType6","SendType7","SendType8","SendType9","No","Yes","No","Yes","No","Yes","No","Yes","Cyclic","SendType1","SendType2","SendType3","SendType4","SendType5","SendType6","SendType7","SendType8","SendType9","Cyclic","SendType1","SendType2","SendType3","SendType4","SendType5","SendType6","SendType7","SendType8","SendType9","Cyclic","SendType1","SendType2","SendType3","SendType4","SendType5","SendType6","SendType7","SendType8","SendType9","Cyclic","SendType1","SendType2","SendType3","SendType4","SendType5","SendType6","SendType7","SendType8","SendType9","No","Yes","Cyclic","SendType1","SendType2","SendType3","SendType4","SendType5","SendType6","SendType7","SendType8","SendType9","Cyclic","SendType1","SendType2","SendType3","SendType4","SendType5","SendType6","SendType7","SendType8","SendType9","Cyclic","SendType1","SendType2","SendType3","SendType4","SendType5","SendType6","SendType7","SendType8","SendType9","No","Yes","Cyclic","SendType1","SendType2","SendType3","SendType4","SendType5","SendType6","SendType7","SendType8","SendType9","Cyclic","SendType1","SendType2","SendType3","SendType4","SendType5","SendType6","SendType7","SendType8","SendType9","No","Yes","Cyclic","SendType1","SendType2","SendType3","SendType4","SendType5","SendType6","SendType7","SendType8","SendType9","No","Yes","No","Yes","Cyclic","SendType1","SendType2","SendType3","SendType4","SendType5","SendType6","SendType7","SendType8","SendType9","Cyclic","SendType1","SendType2","SendType3","SendType4","SendType5","SendType6","SendType7","SendType8","SendType9","Cyclic","SendType1","SendType2","SendType3","SendType4","SendType5","SendType6","SendType7","SendType8","SendType9","No","Yes","Cyclic","SendType1","SendType2","SendType3","SendType4","SendType5","SendType6","SendType7","SendType8","SendType9","Cyclic","SendType1","SendType2","SendType3","SendType4","SendType5","SendType6","SendType7","SendType8","SendType9","No","Yes","Cyclic","SendType1","SendType2","SendType3","SendType4","SendType5","SendType6","SendType7","SendType8","SendType9","No","Yes","No","Yes","Cyclic","SendType1","SendType2","SendType3","SendType4","SendType5","SendType6","SendType7","SendType8","SendType9","Cyclic","SendType1","SendType2","SendType3","SendType4","SendType5","SendType6","SendType7","SendType8","SendType9","No","Yes","Cyclic","SendType1","SendType2","SendType3","SendType4","SendType5","SendType6","SendType7","SendType8","SendType9","No","Yes","No","Yes","Cyclic","SendType1","SendType2","SendType3","SendType4","SendType5","SendType6","SendType7","SendType8","SendType9","No","Yes","No","Yes","No","Yes","Cyclic","SendType1","SendType2","SendType3","SendType4","SendType5","SendType6","SendType7","SendType8","SendType9","Cyclic","SendType1","SendType2","SendType3","SendType4","SendType5","SendType6","SendType7","SendType8","SendType9","Cyclic","SendType1","SendType2","SendType3","SendType4","SendType5","SendType6","SendType7","SendType8","SendType9","No","Yes","Cyclic","SendType1","SendType2","SendType3","SendType4","SendType5","SendType6","SendType7","SendType8","SendType9","Cyclic","SendType1","SendType2","SendType3","SendType4","SendType5","SendType6","SendType7","SendType8","SendType9","No","Yes","Cyclic","SendType1","SendType2","SendType3","SendType4","SendType5","SendType6","SendType7","SendType8","SendType9","No","Yes","No","Yes","Cyclic","SendType1","SendType2","SendType3","SendType4","SendType5","SendType6","SendType7","SendType8","SendType9","Cyclic","SendType1","SendType2","SendType3","SendType4","SendType5","SendType6","SendType7","SendType8","SendType9","No","Yes","Cyclic","SendType1","SendType2","SendType3","SendType4","SendType5","SendType6","SendType7","SendType8","SendType9","No","Yes","No","Yes","Cyclic","SendType1","SendType2","SendType3","SendType4","SendType5","SendType6","SendType7","SendType8","SendType9","No","Yes","No","Yes","No","Yes","Cyclic","SendType1","SendType2","SendType3","SendType4","SendType5","SendType6","SendType7","SendType8","SendType9","Cyclic","SendType1","SendType2","SendType3","SendType4","SendType5","SendType6","SendType7","SendType8","SendType9","No","Yes","Cyclic","SendType1","SendType2","SendType3","SendType4","SendType5","SendType6","SendType7","SendType8","SendType9","No","Yes","No","Yes","Cyclic","SendType1","SendType2","SendType3","SendType4","SendType5","SendType6","SendType7","SendType8","SendType9","No","Yes","No","Yes","No","Yes","Cyclic","SendType1","SendType2","SendType3","SendType4","SendType5","SendType6","SendType7","SendType8","SendType9","No","Yes","No","Yes","No","Yes","No","Yes","Cyclic","SendType1","SendType2","SendType3","SendType4","SendType5","SendType6","SendType7","SendType8","SendType9","Cyclic","SendType1","SendType2","SendType3","SendType4","SendType5","SendType6","SendType7","SendType8","SendType9","Cyclic","SendType1","SendType2","SendType3","SendType4","SendType5","SendType6","SendType7","SendType8","SendType9","No","Yes","Cyclic","SendType1","SendType2","SendType3","SendType4","SendType5","SendType6","SendType7","SendType8","SendType9","Cyclic","SendType1","SendType2","SendType3","SendType4","SendType5","SendType6","SendType7","SendType8","SendType9","No","Yes","Cyclic","SendType1","SendType2","SendType3","SendType4","SendType5","SendType6","SendType7","SendType8","SendType9","No","Yes","No","Yes","Cyclic","SendType1","SendType2","SendType3","SendType4","SendType5","SendType6","SendType7","SendType8","SendType9","Cyclic","SendType1","SendType2","SendType3","SendType4","SendType5","SendType6","SendType7","SendType8","SendType9","No","Yes","Cyclic","SendType1","SendType2","SendType3","SendType4","SendType5","SendType6","SendType7","SendType8","SendType9","No","Yes","No","Yes","Cyclic","SendType1","SendType2","SendType3","SendType4","SendType5","SendType6","SendType7","SendType8","SendType9","No","Yes","No","Yes","No","Yes","Cyclic","SendType1","SendType2","SendType3","SendType4","SendType5","SendType6","SendType7","SendType8","SendType9","Cyclic","SendType1","SendType2","SendType3","SendType4","SendType5","SendType6","SendType7","SendType8","SendType9","No","Yes","Cyclic","SendType1","SendType2","SendType3","SendType4","SendType5","SendType6","SendType7","SendType8","SendType9","No","Yes","No","Yes","Cyclic","SendType1","SendType2","SendType3","SendType4","SendType5","SendType6","SendType7","SendType8","SendType9","No","Yes","No","Yes","No","Yes","Cyclic","SendType1","SendType2","SendType3","SendType4","SendType5","SendType6","SendType7","SendType8","SendType9","No","Yes","No","Yes","No","Yes","No","Yes","Cyclic","SendType1","SendType2","SendType3","SendType4","SendType5","SendType6","SendType7","SendType8","SendType9","Cyclic","SendType1","SendType2","SendType3","SendType4","SendType5","SendType6","SendType7","SendType8","SendType9","No","Yes","Cyclic","SendType1","SendType2","SendType3","SendType4","SendType5","SendType6","SendType7","SendType8","SendType9","No","Yes","No","Yes","Cyclic","SendType1","SendType2","SendType3","SendType4","SendType5","SendType6","SendType7","SendType8","SendType9","No","Yes","No","Yes","No","Yes","Cyclic","SendType1","SendType2","SendType3","SendType4","SendType5","SendType6","SendType7","SendType8","SendType9","No","Yes","No","Yes","No","Yes","No","Yes","Cyclic","SendType1","SendType2","SendType3","SendType4","SendType5","SendType6","SendType7","SendType8","SendType9","No","Yes","No","Yes","No","Yes","No","Yes","int","float","undef","Cyclic","SendType1","SendType2","SendType3","SendType4","SendType5","SendType6","SendType7","SendType8","SendType9","Cyclic","SendType1","SendType2","SendType3","SendType4","SendType5","SendType6","SendType7","SendType8","SendType9","Cyclic","SendType1","SendType2","SendType3","SendType4","SendType5","SendType6","SendType7","SendType8","SendType9","Cyclic","SendType1","SendType2","SendType3","SendType4","SendType5","SendType6","SendType7","SendType8","SendType9","No","Yes","Cyclic","SendType1","SendType2","SendType3","SendType4","SendType5","SendType6","SendType7","SendType8","SendType9","Cyclic","SendType1","SendType2","SendType3","SendType4","SendType5","SendType6","SendType7","SendType8","SendType9","Cyclic","SendType1","SendType2","SendType3","SendType4","SendType5","SendType6","SendType7","SendType8","SendType9","No","Yes","Cyclic","SendType1","SendType2","SendType3","SendType4","SendType5","SendType6","SendType7","SendType8","SendType9","Cyclic","SendType1","SendType2","SendType3","SendType4","SendType5","SendType6","SendType7","SendType8","SendType9","No","Yes","Cyclic","SendType1","SendType2","SendType3","SendType4","SendType5","SendType6","SendType7","SendType8","SendType9","No","Yes","No","Yes","Cyclic","SendType1","SendType2","SendType3","SendType4","SendType5","SendType6","SendType7","SendType8","SendType9","Cyclic","SendType1","SendType2","SendType3","SendType4","SendType5","SendType6","SendType7","SendType8","SendType9","Cyclic","SendType1","SendType2","SendType3","SendType4","SendType5","SendType6","SendType7","SendType8","SendType9","No","Yes","Cyclic","SendType1","SendType2","SendType3","SendType4","SendType5","SendType6","SendType7","SendType8","SendType9","Cyclic","SendType1","SendType2","SendType3","SendType4","SendType5","SendType6","SendType7","SendType8","SendType9","No","Yes","Cyclic","SendType1","SendType2","SendType3","SendType4","SendType5","SendType6","SendType7","SendType8","SendType9","No","Yes","No","Yes","Cyclic","SendType1","SendType2","SendType3","SendType4","SendType5","SendType6","SendType7","SendType8","SendType9","Cyclic","SendType1","SendType2","SendType3","SendType4","SendType5","SendType6","SendType7","SendType8","SendType9","No","Yes","Cyclic","SendType1","SendType2","SendType3","SendType4","SendType5","SendType6","SendType7","SendType8","SendType9","No","Yes","No","Yes","Cyclic","SendType1","SendType2","SendType3","SendType4","SendType5","SendType6","SendType7","SendType8","SendType9","No","Yes","No","Yes","No","Yes","Cyclic","SendType1","SendType2","SendType3","SendType4","SendType5","SendType6","SendType7","SendType8","SendType9","Cyclic","SendType1","SendType2","SendType3","SendType4","SendType5","SendType6","SendType7","SendType8","SendType9","Cyclic","SendType1","SendType2","SendType3","SendType4","SendType5","SendType6","SendType7","SendType8","SendType9","No","Yes","Cyclic","SendType1","SendType2","SendType3","SendType4","SendType5","SendType6","SendType7","SendType8","SendType9","Cyclic","SendType1","SendType2","SendType3","SendType4","SendType5","SendType6","SendType7","SendType8","SendType9","No","Yes","Cyclic","SendType1","SendType2","SendType3","SendType4","SendType5","SendType6","SendType7","SendType8","SendType9","No","Yes","No","Yes","Cyclic","SendType1","SendType2","SendType3","SendType4","SendType5","SendType6","SendType7","SendType8","SendType9","Cyclic","SendType1","SendType2","SendType3","SendType4","SendType5","SendType6","SendType7","SendType8","SendType9","No","Yes","Cyclic","SendType1","SendType2","SendType3","SendType4","SendType5","SendType6","SendType7","SendType8","SendType9","No","Yes","No","Yes","Cyclic","SendType1","SendType2","SendType3","SendType4","SendType5","SendType6","SendType7","SendType8","SendType9","No","Yes","No","Yes","No","Yes","Cyclic","SendType1","SendType2","SendType3","SendType4","SendType5","SendType6","SendType7","SendType8","SendType9","Cyclic","SendType1","SendType2","SendType3","SendType4","SendType5","SendType6","SendType7","SendType8","SendType9","No","Yes","Cyclic","SendType1","SendType2","SendType3","SendType4","SendType5","SendType6","SendType7","SendType8","SendType9","No","Yes","No","Yes","Cyclic","SendType1","SendType2","SendType3","SendType4","SendType5","SendType6","SendType7","SendType8","SendType9","No","Yes","No","Yes","No","Yes","Cyclic","SendType1","SendType2","SendType3","SendType4","SendType5","SendType6","SendType7","SendType8","SendType9","No","Yes","No","Yes","No","Yes","No","Yes","Cyclic","SendType1","SendType2","SendType3","SendType4","SendType5","SendType6","SendType7","SendType8","SendType9","Cyclic","SendType1","SendType2","SendType3","SendType4","SendType5","SendType6","SendType7","SendType8","SendType9","Cyclic","SendType1","SendType2","SendType3","SendType4","SendType5","SendType6","SendType7","SendType8","SendType9","No","Yes","Cyclic","SendType1","SendType2","SendType3","SendType4","SendType5","SendType6","SendType7","SendType8","SendType9","Cyclic","SendType1","SendType2","SendType3","SendType4","SendType5","SendType6","SendType7","SendType8","SendType9","No","Yes","Cyclic","SendType1","SendType2","SendType3","SendType4","SendType5","SendType6","SendType7","SendType8","SendType9","No","Yes","No","Yes","Cyclic","SendType1","SendType2","SendType3","SendType4","SendType5","SendType6","SendType7","SendType8","SendType9","Cyclic","SendType1","SendType2","SendType3","SendType4","SendType5","SendType6","SendType7","SendType8","SendType9","No","Yes","Cyclic","SendType1","SendType2","SendType3","SendType4","SendType5","SendType6","SendType7","SendType8","SendType9","No","Yes","No","Yes","Cyclic","SendType1","SendType2","SendType3","SendType4","SendType5","SendType6","SendType7","SendType8","SendType9","No","Yes","No","Yes","No","Yes","Cyclic","SendType1","SendType2","SendType3","SendType4","SendType5","SendType6","SendType7","SendType8","SendType9","Cyclic","SendType1","SendType2","SendType3","SendType4","SendType5","SendType6","SendType7","SendType8","SendType9","No","Yes","Cyclic","SendType1","SendType2","SendType3","SendType4","SendType5","SendType6","SendType7","SendType8","SendType9","No","Yes","No","Yes","Cyclic","SendType1","SendType2","SendType3","SendType4","SendType5","SendType6","SendType7","SendType8","SendType9","No","Yes","No","Yes","No","Yes","Cyclic","SendType1","SendType2","SendType3","SendType4","SendType5","SendType6","SendType7","SendType8","SendType9","No","Yes","No","Yes","No","Yes","No","Yes","Cyclic","SendType1","SendType2","SendType3","SendType4","SendType5","SendType6","SendType7","SendType8","SendType9","Cyclic","SendType1","SendType2","SendType3","SendType4","SendType5","SendType6","SendType7","SendType8","SendType9","No","Yes","Cyclic","SendType1","SendType2","SendType3","SendType4","SendType5","SendType6","SendType7","SendType8","SendType9","No","Yes","No","Yes","Cyclic","SendType1","SendType2","SendType3","SendType4","SendType5","SendType6","SendType7","SendType8","SendType9","No","Yes","No","Yes","No","Yes","Cyclic","SendType1","SendType2","SendType3","SendType4","SendType5","SendType6","SendType7","SendType8","SendType9","No","Yes","No","Yes","No","Yes","No","Yes","Cyclic","SendType1","SendType2","SendType3","SendType4","SendType5","SendType6","SendType7","SendType8","SendType9","No","Yes","No","Yes","No","Yes","No","Yes","int","float","undef","Cyclic","SendType1","SendType2","SendType3","SendType4","SendType5","SendType6","SendType7","SendType8","SendType9","Cyclic","SendType1","SendType2","SendType3","SendType4","SendType5","SendType6","SendType7","SendType8","SendType9","Cyclic","SendType1","SendType2","SendType3","SendType4","SendType5","SendType6","SendType7","SendType8","SendType9","No","Yes","Cyclic","SendType1","SendType2","SendType3","SendType4","SendType5","SendType6","SendType7","SendType8","SendType9","Cyclic","SendType1","SendType2","SendType3","SendType4","SendType5","SendType6","SendType7","SendType8","SendType9","No","Yes","Cyclic","SendType1","SendType2","SendType3","SendType4","SendType5","SendType6","SendType7","SendType8","SendType9","No","Yes","No","Yes","Cyclic","SendType1","SendType2","SendType3","SendType4","SendType5","SendType6","SendType7","SendType8","SendType9","Cyclic","SendType1","SendType2","SendType3","SendType4","SendType5","SendType6","SendType7","SendType8","SendType9","No","Yes","Cyclic","SendType1","SendType2","SendType3","SendType4","SendType5","SendType6","SendType7","SendType8","SendType9","No","Yes","No","Yes","Cyclic","SendType1","SendType2","SendType3","SendType4","SendType5","SendType6","SendType7","SendType8","SendType9","No","Yes","No","Yes","No","Yes","Cyclic","SendType1","SendType2","SendType3","SendType4","SendType5","SendType6","SendType7","SendType8","SendType9","Cyclic","SendType1","SendType2","SendType3","SendType4","SendType5","SendType6","SendType7","SendType8","SendType9","No","Yes","Cyclic","SendType1","SendType2","SendType3","SendType4","SendType5","SendType6","SendType7","SendType8","SendType9","No","Yes","No","Yes","Cyclic","SendType1","SendType2","SendType3","SendType4","SendType5","SendType6","SendType7","SendType8","SendType9","No","Yes","No","Yes","No","Yes","Cyclic","SendType1","SendType2","SendType3","SendType4","SendType5","SendType6","SendType7","SendType8","SendType9","No","Yes","No","Yes","No","Yes","No","Yes","Cyclic","SendType1","SendType2","SendType3","SendType4","SendType5","SendType6","SendType7","SendType8","SendType9","Cyclic","SendType1","SendType2","SendType3","SendType4","SendType5","SendType6","SendType7","SendType8","SendType9","No","Yes","Cyclic","SendType1","SendType2","SendType3","SendType4","SendType5","SendType6","SendType7","SendType8","SendType9","No","Yes","No","Yes","Cyclic","SendType1","SendType2","SendType3","SendType4","SendType5","SendType6","SendType7","SendType8","SendType9","No","Yes","No","Yes","No","Yes","Cyclic","SendType1","SendType2","SendType3","SendType4","SendType5","SendType6","SendType7","SendType8","SendType9","No","Yes","No","Yes","No","Yes","No","Yes","Cyclic","SendType1","SendType2","SendType3","SendType4","SendType5","SendType6","SendType7","SendType8","SendType9","No","Yes","No","Yes","No","Yes","No","Yes","int","float","undef","Cyclic","SendType1","SendType2","SendType3","SendType4","SendType5","SendType6","SendType7","SendType8","SendType9","Cyclic","SendType1","SendType2","SendType3","SendType4","SendType5","SendType6","SendType7","SendType8","SendType9","No","Yes","Cyclic","SendType1","SendType2","SendType3","SendType4","SendType5","SendType6","SendType7","SendType8","SendType9","No","Yes","No","Yes","Cyclic","SendType1","SendType2","SendType3","SendType4","SendType5","SendType6","SendType7","SendType8","SendType9","No","Yes","No","Yes","No","Yes","Cyclic","SendType1","SendType2","SendType3","SendType4","SendType5","SendType6","SendType7","SendType8","SendType9","No","Yes","No","Yes","No","Yes","No","Yes","Cyclic","SendType1","SendType2","SendType3","SendType4","SendType5","SendType6","SendType7","SendType8","SendType9","No","Yes","No","Yes","No","Yes","No","Yes","int","float","undef","Cyclic","SendType1","SendType2","SendType3","SendType4","SendType5","SendType6","SendType7","SendType8","SendType9","No","Yes","No","Yes","No","Yes","No","Yes","int","float","undef","No","Yes","Cyclic","SendType1","SendType2","SendType3","SendType4","SendType5","SendType6","SendType7","SendType8","SendType9","Cyclic","SendType1","SendType2","SendType3","SendType4","SendType5","SendType6","SendType7","SendType8","SendType9","Cyclic","SendType1","SendType2","SendType3","SendType4","SendType5","SendType6","SendType7","SendType8","SendType9","Cyclic","SendType1","SendType2","SendType3","SendType4","SendType5","SendType6","SendType7","SendType8","SendType9","No","Yes","Cyclic","SendType1","SendType2","SendType3","SendType4","SendType5","SendType6","SendType7","SendType8","SendType9","Cyclic","SendType1","SendType2","SendType3","SendType4","SendType5","SendType6","SendType7","SendType8","SendType9","Cyclic","SendType1","SendType2","SendType3","SendType4","SendType5","SendType6","SendType7","SendType8","SendType9","No","Yes","Cyclic","SendType1","SendType2","SendType3","SendType4","SendType5","SendType6","SendType7","SendType8","SendType9","Cyclic","SendType1","SendType2","SendType3","SendType4","SendType5","SendType6","SendType7","SendType8","SendType9","No","Yes","Cyclic","SendType1","SendType2","SendType3","SendType4","SendType5","SendType6","SendType7","SendType8","SendType9","No","Yes","No","Yes","Cyclic","SendType1","SendType2","SendType3","SendType4","SendType5","SendType6","SendType7","SendType8","SendType9","Cyclic","SendType1","SendType2","SendType3","SendType4","SendType5","SendType6","SendType7","SendType8","SendType9","Cyclic","SendType1","SendType2","SendType3","SendType4","SendType5","SendType6","SendType7","SendType8","SendType9","No","Yes","Cyclic","SendType1","SendType2","SendType3","SendType4","SendType5","SendType6","SendType7","SendType8","SendType9","Cyclic","SendType1","SendType2","SendType3","SendType4","SendType5","SendType6","SendType7","SendType8","SendType9","No","Yes","Cyclic","SendType1","SendType2","SendType3","SendType4","SendType5","SendType6","SendType7","SendType8","SendType9","No","Yes","No","Yes","Cyclic","SendType1","SendType2","SendType3","SendType4","SendType5","SendType6","SendType7","SendType8","SendType9","Cyclic","SendType1","SendType2","SendType3","SendType4","SendType5","SendType6","SendType7","SendType8","SendType9","No","Yes","Cyclic","SendType1","SendType2","SendType3","SendType4","SendType5","SendType6","SendType7","SendType8","SendType9","No","Yes","No","Yes","Cyclic","SendType1","SendType2","SendType3","SendType4","SendType5","SendType6","SendType7","SendType8","SendType9","No","Yes","No","Yes","No","Yes","Cyclic","SendType1","SendType2","SendType3","SendType4","SendType5","SendType6","SendType7","SendType8","SendType9","Cyclic","SendType1","SendType2","SendType3","SendType4","SendType5","SendType6","SendType7","SendType8","SendType9","Cyclic","SendType1","SendType2","SendType3","SendType4","SendType5","SendType6","SendType7","SendType8","SendType9","No","Yes","Cyclic","SendType1","SendType2","SendType3","SendType4","SendType5","SendType6","SendType7","SendType8","SendType9","Cyclic","SendType1","SendType2","SendType3","SendType4","SendType5","SendType6","SendType7","SendType8","SendType9","No","Yes","Cyclic","SendType1","SendType2","SendType3","SendType4","SendType5","SendType6","SendType7","SendType8","SendType9","No","Yes","No","Yes","Cyclic","SendType1","SendType2","SendType3","SendType4","SendType5","SendType6","SendType7","SendType8","SendType9","Cyclic","SendType1","SendType2","SendType3","SendType4","SendType5","SendType6","SendType7","SendType8","SendType9","No","Yes","Cyclic","SendType1","SendType2","SendType3","SendType4","SendType5","SendType6","SendType7","SendType8","SendType9","No","Yes","No","Yes","Cyclic","SendType1","SendType2","SendType3","SendType4","SendType5","SendType6","SendType7","SendType8","SendType9","No","Yes","No","Yes","No","Yes","Cyclic","SendType1","SendType2","SendType3","SendType4","SendType5","SendType6","SendType7","SendType8","SendType9","Cyclic","SendType1","SendType2","SendType3","SendType4","SendType5","SendType6","SendType7","SendType8","SendType9","No","Yes","Cyclic","SendType1","SendType2","SendType3","SendType4","SendType5","SendType6","SendType7","SendType8","SendType9","No","Yes","No","Yes","Cyclic","SendType1","SendType2","SendType3","SendType4","SendType5","SendType6","SendType7","SendType8","SendType9","No","Yes","No","Yes","No","Yes","Cyclic","SendType1","SendType2","SendType3","SendType4","SendType5","SendType6","SendType7","SendType8","SendType9","No","Yes","No","Yes","No","Yes","No","Yes","Cyclic","SendType1","SendType2","SendType3","SendType4","SendType5","SendType6","SendType7","SendType8","SendType9","Cyclic","SendType1","SendType2","SendType3","SendType4","SendType5","SendType6","SendType7","SendType8","SendType9","Cyclic","SendType1","SendType2","SendType3","SendType4","SendType5","SendType6","SendType7","SendType8","SendType9","No","Yes","Cyclic","SendType1","SendType2","SendType3","SendType4","SendType5","SendType6","SendType7","SendType8","SendType9","Cyclic","SendType1","SendType2","SendType3","SendType4","SendType5","SendType6","SendType7","SendType8","SendType9","No","Yes","Cyclic","SendType1","SendType2","SendType3","SendType4","SendType5","SendType6","SendType7","SendType8","SendType9","No","Yes","No","Yes","Cyclic","SendType1","SendType2","SendType3","SendType4","SendType5","SendType6","SendType7","SendType8","SendType9","Cyclic","SendType1","SendType2","SendType3","SendType4","SendType5","SendType6","SendType7","SendType8","SendType9","No","Yes","Cyclic","SendType1","SendType2","SendType3","SendType4","SendType5","SendType6","SendType7","SendType8","SendType9","No","Yes","No","Yes","Cyclic","SendType1","SendType2","SendType3","SendType4","SendType5","SendType6","SendType7","SendType8","SendType9","No","Yes","No","Yes","No","Yes","Cyclic","SendType1","SendType2","SendType3","SendType4","SendType5","SendType6","SendType7","SendType8","SendType9","Cyclic","SendType1","SendType2","SendType3","SendType4","SendType5","SendType6","SendType7","SendType8","SendType9","No","Yes","Cyclic","SendType1","SendType2","SendType3","SendType4","SendType5","SendType6","SendType7","SendType8","SendType9","No","Yes","No","Yes","Cyclic","SendType1","SendType2","SendType3","SendType4","SendType5","SendType6","SendType7","SendType8","SendType9","No","Yes","No","Yes","No","Yes","Cyclic","SendType1","SendType2","SendType3","SendType4","SendType5","SendType6","SendType7","SendType8","SendType9","No","Yes","No","Yes","No","Yes","No","Yes","Cyclic","SendType1","SendType2","SendType3","SendType4","SendType5","SendType6","SendType7","SendType8","SendType9","Cyclic","SendType1","SendType2","SendType3","SendType4","SendType5","SendType6","SendType7","SendType8","SendType9","No","Yes","Cyclic","SendType1","SendType2","SendType3","SendType4","SendType5","SendType6","SendType7","SendType8","SendType9","No","Yes","No","Yes","Cyclic","SendType1","SendType2","SendType3","SendType4","SendType5","SendType6","SendType7","SendType8","SendType9","No","Yes","No","Yes","No","Yes","Cyclic","SendType1","SendType2","SendType3","SendType4","SendType5","SendType6","SendType7","SendType8","SendType9","No","Yes","No","Yes","No","Yes","No","Yes","Cyclic","SendType1","SendType2","SendType3","SendType4","SendType5","SendType6","SendType7","SendType8","SendType9","No","Yes","No","Yes","No","Yes","No","Yes","int","float","undef","Cyclic","SendType1","SendType2","SendType3","SendType4","SendType5","SendType6","SendType7","SendType8","SendType9","Cyclic","SendType1","SendType2","SendType3","SendType4","SendType5","SendType6","SendType7","SendType8","SendType9","Cyclic","SendType1","SendType2","SendType3","SendType4","SendType5","SendType6","SendType7","SendType8","SendType9","No","Yes","Cyclic","SendType1","SendType2","SendType3","SendType4","SendType5","SendType6","SendType7","SendType8","SendType9","Cyclic","SendType1","SendType2","SendType3","SendType4","SendType5","SendType6","SendType7","SendType8","SendType9","No","Yes","Cyclic","SendType1","SendType2","SendType3","SendType4","SendType5","SendType6","SendType7","SendType8","SendType9","No","Yes","No","Yes","Cyclic","SendType1","SendType2","SendType3","SendType4","SendType5","SendType6","SendType7","SendType8","SendType9","Cyclic","SendType1","SendType2","SendType3","SendType4","SendType5","SendType6","SendType7","SendType8","SendType9","No","Yes","Cyclic","SendType1","SendType2","SendType3","SendType4","SendType5","SendType6","SendType7","SendType8","SendType9","No","Yes","No","Yes","Cyclic","SendType1","SendType2","SendType3","SendType4","SendType5","SendType6","SendType7","SendType8","SendType9","No","Yes","No","Yes","No","Yes","Cyclic","SendType1","SendType2","SendType3","SendType4","SendType5","SendType6","SendType7","SendType8","SendType9","Cyclic","SendType1","SendType2","SendType3","SendType4","SendType5","SendType6","SendType7","SendType8","SendType9","No","Yes","Cyclic","SendType1","SendType2","SendType3","SendType4","SendType5","SendType6","SendType7","SendType8","SendType9","No","Yes","No","Yes","Cyclic","SendType1","SendType2","SendType3","SendType4","SendType5","SendType6","SendType7","SendType8","SendType9","No","Yes","No","Yes","No","Yes","Cyclic","SendType1","SendType2","SendType3","SendType4","SendType5","SendType6","SendType7","SendType8","SendType9","No","Yes","No","Yes","No","Yes","No","Yes","Cyclic","SendType1","SendType2","SendType3","SendType4","SendType5","SendType6","SendType7","SendType8","SendType9","Cyclic","SendType1","SendType2","SendType3","SendType4","SendType5","SendType6","SendType7","SendType8","SendType9","No","Yes","Cyclic","SendType1","SendType2","SendType3","SendType4","SendType5","SendType6","SendType7","SendType8","SendType9","No","Yes","No","Yes","Cyclic","SendType1","SendType2","SendType3","SendType4","SendType5","SendType6","SendType7","SendType8","SendType9","No","Yes","No","Yes","No","Yes","Cyclic","SendType1","SendType2","SendType3","SendType4","SendType5","SendType6","SendType7","SendType8","SendType9","No","Yes","No","Yes","No","Yes","No","Yes","Cyclic","SendType1","SendType2","SendType3","SendType4","SendType5","SendType6","SendType7","SendType8","SendType9","No","Yes","No","Yes","No","Yes","No","Yes","int","float","undef","Cyclic","SendType1","SendType2","SendType3","SendType4","SendType5","SendType6","SendType7","SendType8","SendType9","Cyclic","SendType1","SendType2","SendType3","SendType4","SendType5","SendType6","SendType7","SendType8","SendType9","No","Yes","Cyclic","SendType1","SendType2","SendType3","SendType4","SendType5","SendType6","SendType7","SendType8","SendType9","No","Yes","No","Yes","Cyclic","SendType1","SendType2","SendType3","SendType4","SendType5","SendType6","SendType7","SendType8","SendType9","No","Yes","No","Yes","No","Yes","Cyclic","SendType1","SendType2","SendType3","SendType4","SendType5","SendType6","SendType7","SendType8","SendType9","No","Yes","No","Yes","No","Yes","No","Yes","Cyclic","SendType1","SendType2","SendType3","SendType4","SendType5","SendType6","SendType7","SendType8","SendType9","No","Yes","No","Yes","No","Yes","No","Yes","int","float","undef","Cyclic","SendType1","SendType2","SendType3","SendType4","SendType5","SendType6","SendType7","SendType8","SendType9","No","Yes","No","Yes","No","Yes","No","Yes","int","float","undef","No","Yes","Cyclic","SendType1","SendType2","SendType3","SendType4","SendType5","SendType6","SendType7","SendType8","SendType9","Cyclic","SendType1","SendType2","SendType3","SendType4","SendType5","SendType6","SendType7","SendType8","SendType9","Cyclic","SendType1","SendType2","SendType3","SendType4","SendType5","SendType6","SendType7","SendType8","SendType9","No","Yes","Cyclic","SendType1","SendType2","SendType3","SendType4","SendType5","SendType6","SendType7","SendType8","SendType9","Cyclic","SendType1","SendType2","SendType3","SendType4","SendType5","SendType6","SendType7","SendType8","SendType9","No","Yes","Cyclic","SendType1","SendType2","SendType3","SendType4","SendType5","SendType6","SendType7","SendType8","SendType9","No","Yes","No","Yes","Cyclic","SendType1","SendType2","SendType3","SendType4","SendType5","SendType6","SendType7","SendType8","SendType9","Cyclic","SendType1","SendType2","SendType3","SendType4","SendType5","SendType6","SendType7","SendType8","SendType9","No","Yes","Cyclic","SendType1","SendType2","SendType3","SendType4","SendType5","SendType6","SendType7","SendType8","SendType9","No","Yes","No","Yes","Cyclic","SendType1","SendType2","SendType3","SendType4","SendType5","SendType6","SendType7","SendType8","SendType9","No","Yes","No","Yes","No","Yes","Cyclic","SendType1","SendType2","SendType3","SendType4","SendType5","SendType6","SendType7","SendType8","SendType9","Cyclic","SendType1","SendType2","SendType3","SendType4","SendType5","SendType6","SendType7","SendType8","SendType9","No","Yes","Cyclic","SendType1","SendType2","SendType3","SendType4","SendType5","SendType6","SendType7","SendType8","SendType9","No","Yes","No","Yes","Cyclic","SendType1","SendType2","SendType3","SendType4","SendType5","SendType6","SendType7","SendType8","SendType9","No","Yes","No","Yes","No","Yes","Cyclic","SendType1","SendType2","SendType3","SendType4","SendType5","SendType6","SendType7","SendType8","SendType9","No","Yes","No","Yes","No","Yes","No","Yes","Cyclic","SendType1","SendType2","SendType3","SendType4","SendType5","SendType6","SendType7","SendType8","SendType9","Cyclic","SendType1","SendType2","SendType3","SendType4","SendType5","SendType6","SendType7","SendType8","SendType9","No","Yes","Cyclic","SendType1","SendType2","SendType3","SendType4","SendType5","SendType6","SendType7","SendType8","SendType9","No","Yes","No","Yes","Cyclic","SendType1","SendType2","SendType3","SendType4","SendType5","SendType6","SendType7","SendType8","SendType9","No","Yes","No","Yes","No","Yes","Cyclic","SendType1","SendType2","SendType3","SendType4","SendType5","SendType6","SendType7","SendType8","SendType9","No","Yes","No","Yes","No","Yes","No","Yes","Cyclic","SendType1","SendType2","SendType3","SendType4","SendType5","SendType6","SendType7","SendType8","SendType9","No","Yes","No","Yes","No","Yes","No","Yes","int","float","undef","Cyclic","SendType1","SendType2","SendType3","SendType4","SendType5","SendType6","SendType7","SendType8","SendType9","Cyclic","SendType1","SendType2","SendType3","SendType4","SendType5","SendType6","SendType7","SendType8","SendType9","No","Yes","Cyclic","SendType1","SendType2","SendType3","SendType4","SendType5","SendType6","SendType7","SendType8","SendType9","No","Yes","No","Yes","Cyclic","SendType1","SendType2","SendType3","SendType4","SendType5","SendType6","SendType7","SendType8","SendType9","No","Yes","No","Yes","No","Yes","Cyclic","SendType1","SendType2","SendType3","SendType4","SendType5","SendType6","SendType7","SendType8","SendType9","No","Yes","No","Yes","No","Yes","No","Yes","Cyclic","SendType1","SendType2","SendType3","SendType4","SendType5","SendType6","SendType7","SendType8","SendType9","No","Yes","No","Yes","No","Yes","No","Yes","int","float","undef","Cyclic","SendType1","SendType2","SendType3","SendType4","SendType5","SendType6","SendType7","SendType8","SendType9","No","Yes","No","Yes","No","Yes","No","Yes","int","float","undef","No","Yes","Cyclic","SendType1","SendType2","SendType3","SendType4","SendType5","SendType6","SendType7","SendType8","SendType9","Cyclic","SendType1","SendType2","SendType3","SendType4","SendType5","SendType6","SendType7","SendType8","SendType9","No","Yes","Cyclic","SendType1","SendType2","SendType3","SendType4","SendType5","SendType6","SendType7","SendType8","SendType9","No","Yes","No","Yes","Cyclic","SendType1","SendType2","SendType3","SendType4","SendType5","SendType6","SendType7","SendType8","SendType9","No","Yes","No","Yes","No","Yes","Cyclic","SendType1","SendType2","SendType3","SendType4","SendType5","SendType6","SendType7","SendType8","SendType9","No","Yes","No","Yes","No","Yes","No","Yes","Cyclic","SendType1","SendType2","SendType3","SendType4","SendType5","SendType6","SendType7","SendType8","SendType9","No","Yes","No","Yes","No","Yes","No","Yes","int","float","undef","Cyclic","SendType1","SendType2","SendType3","SendType4","SendType5","SendType6","SendType7","SendType8","SendType9","No","Yes","No","Yes","No","Yes","No","Yes","int","float","undef","No","Yes","Cyclic","SendType1","SendType2","SendType3","SendType4","SendType5","SendType6","SendType7","SendType8","SendType9","No","Yes","No","Yes","No","Yes","No","Yes","int","float","undef","No","Yes","No","Yes";
BA_DEF_ "GenEnvVarEndingDsp" STRING ;
BA_DEF_ "GenEnvVarEndingSnd" STRING ;
BA_DEF_ "GenEnvVarPrefix" STRING ;
BA_DEF_ "Modified" STRING ;
BA_DEF_ SG_ "SystemSignalLongSymbol" STRING ;
BA_DEF_ BO_ "SystemMessageLongSymbol" STRING ;
BA_DEF_ BO_ "GenMsgBackgroundColor" STRING ;
BA_DEF_ BO_ "GenMsgForegroundColor" STRING ;
BA_ "SystemSignalLongSymbol" SG_ 291 UI_a037_AudioWatchdogXrunStormEr "UI_a037_AudioWatchdogXrunStormEr";
BA_ "SystemSignalLongSymbol" SG_ 291 UI_a038_AudioWatchdogA2bI2cLocku "UI_a038_AudioWatchdogA2bI2cLocku";
BA_ "SystemSignalLongSymbol" SG_ 291 UI_a048_AudioPremiumAmpCheckFail "UI_a048_AudioPremiumAmpCheckFail";
BA_ "SystemSignalLongSymbol" SG_ 291 UI_a056_ManualECallButtonDisconn "UI_a056_ManualECallButtonDisconn";
BA_DEF_DEF_ "GenMsgSendType" "Cyclic";
BA_DEF_DEF_ "GenMsgCycleTime" 0;
BA_DEF_DEF_ "GenMsgAutoGenSnd" "Yes";
BA_DEF_DEF_ "GenMsgAutoGenDsp" "Yes";
BA_DEF_DEF_ "GenSigAutoGenSnd" "Cyclic";
BA_DEF_DEF_ "GenSigAutoGenDsp" "Cyclic";
BA_DEF_DEF_ "GenSigEnvVarType" "undef";
BA_DEF_DEF_ "GenNodAutoGenSnd" "Yes";
BA_DEF_DEF_ "GenNodAutoGenDsp" "Yes";
BA_DEF_DEF_ "GenEnvVarEndingDsp" "Dsp";
BA_DEF_DEF_ "GenEnvVarEndingSnd" "Snd";
BA_DEF_DEF_ "GenEnvVarPrefix" "Env";
BA_DEF_DEF_ "Modified" "JW2020Jul22";
BA_DEF_DEF_ "SystemSignalLongSymbol" "";
BA_DEF_DEF_ "SystemMessageLongSymbol" "";
BA_DEF_DEF_ "GenMsgBackgroundColor" "#ffffff";
BA_DEF_DEF_ "GenMsgForegroundColor" "#000000";
CM_ SG_ 130 UI_tripPlanningActive "Navigation Active";
CM_ SG_ 257 RCM_pitchRate "Pitch";
CM_ SG_ 257 RCM_rollRate "Roll";
CM_ SG_ 257 RCM_yawRate "Yaw";
CM_ SG_ 273 RCM_lateralAccel "L/R Acceleration";
CM_ SG_ 273 RCM_longitudinalAccel "F/B Acceleration";
CM_ SG_ 273 RCM_verticalAccel "Vertical Acceleration";
CM_ SG_ 692 PCS_dcdcHvBusVolt "DCDC HV Voltage";
CM_ SG_ 692 PCS_dcdcLvBusVolt "DCDC 12v Voltage";
CM_ SG_ 692 PCS_dcdcLvOutputCurrent "DCDC 12v Output Current";
VAL_ 12 UI_autopilotTrial 3 "ACTIVE" 0 "NONE" 1 "START" 2 "STOP";
VAL_ 12 UI_cellNetworkTechnology 9 "CELL_NETWORK_CDMA" 2 "CELL_NETWORK_EDGE" 1 "CELL_NETWORK_GPRS" 8 "CELL_NETWORK_GSM" 4 "CELL_NETWORK_HSDPA" 6 "CELL_NETWORK_HSPA" 5 "CELL_NETWORK_HSUPA" 7 "CELL_NETWORK_LTE" 0 "CELL_NETWORK_NONE" 15 "CELL_NETWORK_SNA" 3 "CELL_NETWORK_UMTS" 10 "CELL_NETWORK_WCDMA";
VAL_ 12 UI_cellSignalBars 5 "FIVE" 4 "FOUR" 1 "ONE" 7 "SNA" 3 "THREE" 2 "TWO" 0 "ZERO";
VAL_ 12 UI_factoryReset 3 "CUSTOMER" 1 "DEVELOPER" 2 "DIAGNOSTIC" 0 "NONE_SNA";
VAL_ 130 UI_energyAtDestination 32768 "SNA" 32767 "TRIP_TOO_LONG";
VAL_ 130 UI_hindsightEnergy 32768 "SNA" 32767 "TRIP_TOO_LONG";
VAL_ 130 UI_predictedEnergy 32768 "SNA" 32767 "TRIP_TOO_LONG";
VAL_ 257 RCM_pitchRate 16384 "SNA";
VAL_ 257 RCM_pitchRateQF 3 "FAULTED" 0 "INIT" 2 "TEMP_INVALID" 1 "VALID";
VAL_ 257 RCM_rollRate 16384 "SNA";
VAL_ 257 RCM_rollRateQF 3 "FAULTED" 0 "INIT" 2 "TEMP_INVALID" 1 "VALID";
VAL_ 257 RCM_yawRate 32768 "SNA";
VAL_ 257 RCM_yawRateQF 0 "FAULTED" 1 "NOT_FAULTED";
VAL_ 273 RCM_lateralAccel 32768 "SNA";
VAL_ 273 RCM_lateralAccelQF 0 "FAULTED" 1 "NOT_FAULTED";
VAL_ 273 RCM_longitudinalAccel 32768 "SNA";
VAL_ 273 RCM_longitudinalAccelQF 0 "FAULTED" 1 "NOT_FAULTED";
VAL_ 273 RCM_verticalAccel 32768 "SNA";
VAL_ 273 RCM_verticalAccelQF 0 "FAULTED" 1 "NOT_FAULTED";
VAL_ 258 VCLEFT_frontLatchStatus 5 "LATCH_AJAR" 2 "LATCH_CLOSED" 3 "LATCH_CLOSING" 7 "LATCH_DEFAULT" 8 "LATCH_FAULT" 1 "LATCH_OPENED" 4 "LATCH_OPENING" 0 "LATCH_SNA" 6 "LATCH_TIMEOUT";
VAL_ 258 VCLEFT_mirrorFoldState 1 "MIRROR_FOLD_STATE_FOLDED" 3 "MIRROR_FOLD_STATE_FOLDING" 2 "MIRROR_FOLD_STATE_UNFOLDED" 4 "MIRROR_FOLD_STATE_UNFOLDING" 0 "MIRROR_FOLD_STATE_UNKNOWN";
VAL_ 258 VCLEFT_mirrorHeatState 4 "HEATER_STATE_FAULT" 2 "HEATER_STATE_OFF" 3 "HEATER_STATE_OFF_UNAVAILABLE" 1 "HEATER_STATE_ON" 0 "HEATER_STATE_SNA";
VAL_ 258 VCLEFT_mirrorRecallState 0 "MIRROR_RECALL_STATE_INIT" 1 "MIRROR_RECALL_STATE_RECALLING_AXIS_1" 2 "MIRROR_RECALL_STATE_RECALLING_AXIS_2" 3 "MIRROR_RECALL_STATE_RECALLING_COMPLETE" 4 "MIRROR_RECALL_STATE_RECALLING_FAILED" 5 "MIRROR_RECALL_STATE_RECALLING_STOPPED";
VAL_ 258 VCLEFT_mirrorState 3 "MIRROR_STATE_FOLD_UNFOLD" 0 "MIRROR_STATE_IDLE" 4 "MIRROR_STATE_RECALL" 1 "MIRROR_STATE_TILT_X" 2 "MIRROR_STATE_TILT_Y";
VAL_ 258 VCLEFT_rearLatchStatus 5 "LATCH_AJAR" 2 "LATCH_CLOSED" 3 "LATCH_CLOSING" 7 "LATCH_DEFAULT" 8 "LATCH_FAULT" 1 "LATCH_OPENED" 4 "LATCH_OPENING" 0 "LATCH_SNA" 6 "LATCH_TIMEOUT";
VAL_ 259 VCRIGHT_frontLatchStatus 5 "LATCH_AJAR" 2 "LATCH_CLOSED" 3 "LATCH_CLOSING" 7 "LATCH_DEFAULT" 8 "LATCH_FAULT" 1 "LATCH_OPENED" 4 "LATCH_OPENING" 0 "LATCH_SNA" 6 "LATCH_TIMEOUT";
VAL_ 259 VCRIGHT_mirrorFoldState 1 "MIRROR_FOLD_STATE_FOLDED" 3 "MIRROR_FOLD_STATE_FOLDING" 2 "MIRROR_FOLD_STATE_UNFOLDED" 4 "MIRROR_FOLD_STATE_UNFOLDING" 0 "MIRROR_FOLD_STATE_UNKNOWN";
VAL_ 259 VCRIGHT_mirrorRecallState 0 "MIRROR_RECALL_STATE_INIT" 1 "MIRROR_RECALL_STATE_RECALLING_AXIS_1" 2 "MIRROR_RECALL_STATE_RECALLING_AXIS_2" 3 "MIRROR_RECALL_STATE_RECALLING_COMPLETE" 4 "MIRROR_RECALL_STATE_RECALLING_FAILED" 5 "MIRROR_RECALL_STATE_RECALLING_STOPPED";
VAL_ 259 VCRIGHT_mirrorState 3 "MIRROR_STATE_FOLD_UNFOLD" 0 "MIRROR_STATE_IDLE" 4 "MIRROR_STATE_RECALL" 1 "MIRROR_STATE_TILT_X" 2 "MIRROR_STATE_TILT_Y";
VAL_ 259 VCRIGHT_rearLatchStatus 5 "LATCH_AJAR" 2 "LATCH_CLOSED" 3 "LATCH_CLOSING" 7 "LATCH_DEFAULT" 8 "LATCH_FAULT" 1 "LATCH_OPENED" 4 "LATCH_OPENING" 0 "LATCH_SNA" 6 "LATCH_TIMEOUT";
VAL_ 259 VCRIGHT_trunkLatchStatus 5 "LATCH_AJAR" 2 "LATCH_CLOSED" 3 "LATCH_CLOSING" 7 "LATCH_DEFAULT" 8 "LATCH_FAULT" 1 "LATCH_OPENED" 4 "LATCH_OPENING" 0 "LATCH_SNA" 6 "LATCH_TIMEOUT";
VAL_ 322 VCLEFT_liftgateStatusIndex 0 "LIFTGATE_STATUS_INDEX_0" 1 "LIFTGATE_STATUS_INDEX_1" 2 "LIFTGATE_STATUS_INDEX_INVALID";
VAL_ 322 VCLEFT_liftgateLatchRequest 1 "LATCH_REQUEST_CINCH" 3 "LATCH_REQUEST_FORCE_RELEASE" 0 "LATCH_REQUEST_NONE" 2 "LATCH_REQUEST_RELEASE" 4 "LATCH_REQUEST_RESET";
VAL_ 322 VCLEFT_liftgateMvmntNotAllowedCo 4 "PLG_MVMT_NOT_ALLOWED_EXTERIOR_PRESS_AT_MAX_OPEN" 5 "PLG_MVMT_NOT_ALLOWED_LOCKED" 1 "PLG_MVMT_NOT_ALLOWED_LOW_12V" 0 "PLG_MVMT_NOT_ALLOWED_NONE" 3 "PLG_MVMT_NOT_ALLOWED_UNCALIBRATED" 2 "PLG_MVMT_NOT_ALLOWED_VEHICLE_AT_SPEED";
VAL_ 322 VCLEFT_liftgatePhysicalChimeRequ 0 "LIFTGATE_CHIME_REQUEST_NONE" 4 "LIFTGATE_CHIME_REQUEST_ONE_LONG" 1 "LIFTGATE_CHIME_REQUEST_ONE_SHORT" 3 "LIFTGATE_CHIME_REQUEST_THREE_SHORT" 2 "LIFTGATE_CHIME_REQUEST_TWO_SHORT";
VAL_ 322 VCLEFT_liftgateRequestSource 5 "PLG_REQUEST_SOURCE_CLOSE_ALL" 2 "PLG_REQUEST_SOURCE_EXTERIOR" 4 "PLG_REQUEST_SOURCE_KEY_TRUNK_BUTTON" 6 "PLG_REQUEST_SOURCE_MCU_CLOSE" 1 "PLG_REQUEST_SOURCE_MCU_SWITCH" 0 "PLG_REQUEST_SOURCE_NONE" 3 "PLG_REQUEST_SOURCE_SHUTFACE" 7 "PLG_REQUEST_SOURCE_UDS";
VAL_ 322 VCLEFT_liftgateState 2 "PLG_STATE_BACKOFF" 5 "PLG_STATE_CLOSED" 4 "PLG_STATE_CLOSING" 11 "PLG_STATE_END_OF_TRAVEL" 0 "PLG_STATE_INIT" 7 "PLG_STATE_LATCH_CLOSING" 12 "PLG_STATE_LATCH_ENTRY" 10 "PLG_STATE_LATCH_EXIT" 6 "PLG_STATE_LATCH_OPENING" 8 "PLG_STATE_NOT_INSTALLED" 1 "PLG_STATE_OFF" 3 "PLG_STATE_OPENING" 9 "PLG_STATE_UNKNOWN";
VAL_ 322 VCLEFT_liftgateStoppingCondition 11 "PLG_STOPPING_CONDITION_COUNT" 10 "PLG_STOPPING_CONDITION_LATCH_FAULT" 3 "PLG_STOPPING_CONDITION_LOW_12V" 0 "PLG_STOPPING_CONDITION_NONE" 6 "PLG_STOPPING_CONDITION_OBSTACLE_CURRENT" 2 "PLG_STOPPING_CONDITION_OBSTACLE_STALL" 7 "PLG_STOPPING_CONDITION_OBSTACLE_TRAJ_POS" 8 "PLG_STOPPING_CONDITION_OBSTACLE_TRAJ_VEL" 1 "PLG_STOPPING_CONDITION_PINCH" 4 "PLG_STOPPING_CONDITION_STATE_TIMEOUT" 9 "PLG_STOPPING_CONDITION_UNCALIBRATED" 5 "PLG_STOPPING_CONDITION_VEHICLE_AT_SPEED";
VAL_ 322 VCLEFT_liftgateUIChimeRequest 0 "LIFTGATE_CHIME_REQUEST_NONE" 4 "LIFTGATE_CHIME_REQUEST_ONE_LONG" 1 "LIFTGATE_CHIME_REQUEST_ONE_SHORT" 3 "LIFTGATE_CHIME_REQUEST_THREE_SHORT" 2 "LIFTGATE_CHIME_REQUEST_TWO_SHORT";
VAL_ 325 ESP_absBrakeEvent2 2 "ABS_EVENT_ACTIVE_FRONT" 1 "ABS_EVENT_ACTIVE_FRONT_REAR" 3 "ABS_EVENT_ACTIVE_REAR" 0 "ABS_EVENT_NOT_ACTIVE";
VAL_ 325 ESP_absFaultLamp 0 "ABS_FAULT_LAMP_OFF" 1 "ABS_FAULT_LAMP_ON";
VAL_ 325 ESP_brakeApply 1 "BLS_ACTIVE" 0 "BLS_INACTIVE";
VAL_ 325 ESP_brakeDiscWipingActive 1 "BDW_ACTIVE" 0 "BDW_INACTIVE";
VAL_ 325 ESP_brakeLamp 0 "LAMP_OFF" 1 "LAMP_ON";
VAL_ 325 ESP_brakeTorqueTarget 8191 "SNA";
VAL_ 325 ESP_btcTargetState 1 "BACKUP" 0 "OFF" 2 "ON" 3 "SNA";
VAL_ 325 ESP_cdpStatus 2 "ACTUATING_EPB_CDP" 3 "CDP_COMMAND_INVALID" 1 "CDP_IS_AVAILABLE" 0 "CDP_IS_NOT_AVAILABLE";
VAL_ 325 ESP_driverBrakeApply 2 "Driver_applying_brakes" 3 "Faulty_SNA" 0 "NotInit_orOff" 1 "Not_Applied";
VAL_ 325 ESP_ebdFaultLamp 0 "EBD_FAULT_LAMP_OFF" 1 "EBD_FAULT_LAMP_ON";
VAL_ 325 ESP_ebrStandstillSkid 0 "NO_STANDSTILL_SKID" 1 "STANDSTILL_SKID_DETECTED";
VAL_ 325 ESP_ebrStatus 2 "ACTUATING_DI_EBR" 3 "EBR_COMMAND_INVALID" 1 "EBR_IS_AVAILABLE" 0 "EBR_IS_NOT_AVAILABLE";
VAL_ 325 ESP_espFaultLamp 0 "ESP_FAULT_LAMP_OFF" 1 "ESP_FAULT_LAMP_ON";
VAL_ 325 ESP_espLampFlash 1 "ESP_LAMP_FLASH" 0 "ESP_LAMP_OFF";
VAL_ 325 ESP_espModeActive 0 "ESP_MODE_00_NORMAL" 1 "ESP_MODE_01" 2 "ESP_MODE_02" 3 "ESP_MODE_03";
VAL_ 325 ESP_lateralAccelQF 1 "IN_SPEC" 0 "UNDEFINABLE_ACCURACY";
VAL_ 325 ESP_longitudinalAccelQF 1 "IN_SPEC" 0 "UNDEFINABLE_ACCURACY";
VAL_ 325 ESP_ptcTargetState 1 "BACKUP" 0 "FAULT" 2 "ON" 3 "SNA";
VAL_ 325 ESP_stabilityControlSts2 2 "ENGAGED" 3 "FAULTED" 0 "INIT" 1 "ON";
VAL_ 325 ESP_steeringAngleQF 1 "IN_SPEC" 0 "UNDEFINABLE_ACCURACY";
VAL_ 325 ESP_yawRateQF 1 "IN_SPEC" 0 "UNDEFINABLE_ACCURACY";
VAL_ 522 HVP_fcContNegativeState 3 "CONTACTOR_STATE_BLOCKED" 6 "CONTACTOR_STATE_ECONOMIZED" 1 "CONTACTOR_STATE_OPEN" 5 "CONTACTOR_STATE_OPENING" 2 "CONTACTOR_STATE_PRECHARGE" 4 "CONTACTOR_STATE_PULLED_IN" 0 "CONTACTOR_STATE_SNA" 7 "CONTACTOR_STATE_WELDED";
VAL_ 522 HVP_fcContPositiveState 3 "CONTACTOR_STATE_BLOCKED" 6 "CONTACTOR_STATE_ECONOMIZED" 1 "CONTACTOR_STATE_OPEN" 5 "CONTACTOR_STATE_OPENING" 2 "CONTACTOR_STATE_PRECHARGE" 4 "CONTACTOR_STATE_PULLED_IN" 0 "CONTACTOR_STATE_SNA" 7 "CONTACTOR_STATE_WELDED";
VAL_ 522 HVP_fcContactorSetState 3 "CONTACTOR_SET_STATE_BLOCKED" 5 "CONTACTOR_SET_STATE_CLOSED" 2 "CONTACTOR_SET_STATE_CLOSING" 9 "CONTACTOR_SET_STATE_NEGATIVE_CLOSED" 1 "CONTACTOR_SET_STATE_OPEN" 4 "CONTACTOR_SET_STATE_OPENING" 6 "CONTACTOR_SET_STATE_PARTIAL_WELD" 8 "CONTACTOR_SET_STATE_POSITIVE_CLOSED" 0 "CONTACTOR_SET_STATE_SNA" 7 "CONTACTOR_SET_STATE_WELDED";
VAL_ 522 HVP_fcCtrsRequestStatus 1 "REQUEST_ACTIVE" 2 "REQUEST_COMPLETED" 0 "REQUEST_NOT_ACTIVE";
VAL_ 522 HVP_fcLinkAllowedToEnergize 1 "FC_LINK_ENERGY_AC" 2 "FC_LINK_ENERGY_DC" 0 "FC_LINK_ENERGY_NONE";
VAL_ 522 HVP_hvilStatus 2 "CURRENT_SOURCE_FAULT" 3 "INTERNAL_OPEN_FAULT" 8 "NO_12V_SUPPLY" 5 "PENTHOUSE_LID_OPEN_FAULT" 1 "STATUS_OK" 0 "UNKNOWN" 6 "UNKNOWN_LOCATION_OPEN_FAULT" 7 "VEHICLE_NODE_FAULT" 4 "VEHICLE_OPEN_FAULT" 9 "VEHICLE_OR_PENTHOUSE_LID_OPEN_FAULT";
VAL_ 522 HVP_packContNegativeState 3 "CONTACTOR_STATE_BLOCKED" 6 "CONTACTOR_STATE_ECONOMIZED" 1 "CONTACTOR_STATE_OPEN" 5 "CONTACTOR_STATE_OPENING" 2 "CONTACTOR_STATE_PRECHARGE" 4 "CONTACTOR_STATE_PULLED_IN" 0 "CONTACTOR_STATE_SNA" 7 "CONTACTOR_STATE_WELDED";
VAL_ 522 HVP_packContPositiveState 3 "CONTACTOR_STATE_BLOCKED" 6 "CONTACTOR_STATE_ECONOMIZED" 1 "CONTACTOR_STATE_OPEN" 5 "CONTACTOR_STATE_OPENING" 2 "CONTACTOR_STATE_PRECHARGE" 4 "CONTACTOR_STATE_PULLED_IN" 0 "CONTACTOR_STATE_SNA" 7 "CONTACTOR_STATE_WELDED";
VAL_ 522 HVP_packContactorSetState 3 "CONTACTOR_SET_STATE_BLOCKED" 5 "CONTACTOR_SET_STATE_CLOSED" 2 "CONTACTOR_SET_STATE_CLOSING" 9 "CONTACTOR_SET_STATE_NEGATIVE_CLOSED" 1 "CONTACTOR_SET_STATE_OPEN" 4 "CONTACTOR_SET_STATE_OPENING" 6 "CONTACTOR_SET_STATE_PARTIAL_WELD" 8 "CONTACTOR_SET_STATE_POSITIVE_CLOSED" 0 "CONTACTOR_SET_STATE_SNA" 7 "CONTACTOR_SET_STATE_WELDED";
VAL_ 522 HVP_packCtrsRequestStatus 1 "REQUEST_ACTIVE" 2 "REQUEST_COMPLETED" 0 "REQUEST_NOT_ACTIVE";
VAL_ 526 PARK_sdiSensor1RawDistData 0 "BLOCKED" 1 "NEAR_DETECTION" 500 "NO_OBJECT_DETECTED" 511 "SNA";
VAL_ 526 PARK_sdiSensor2RawDistData 0 "BLOCKED" 1 "NEAR_DETECTION" 500 "NO_OBJECT_DETECTED" 511 "SNA";
VAL_ 526 PARK_sdiSensor3RawDistData 0 "BLOCKED" 1 "NEAR_DETECTION" 500 "NO_OBJECT_DETECTED" 511 "SNA";
VAL_ 526 PARK_sdiSensor4RawDistData 0 "BLOCKED" 1 "NEAR_DETECTION" 500 "NO_OBJECT_DETECTED" 511 "SNA";
VAL_ 526 PARK_sdiSensor5RawDistData 0 "BLOCKED" 1 "NEAR_DETECTION" 500 "NO_OBJECT_DETECTED" 511 "SNA";
VAL_ 526 PARK_sdiSensor6RawDistData 0 "BLOCKED" 1 "NEAR_DETECTION" 500 "NO_OBJECT_DETECTED" 511 "SNA";
VAL_ 537 VCSEC_TPMSDataIndex 0 "TPMS_DATA_SENSOR_0" 1 "TPMS_DATA_SENSOR_1" 2 "TPMS_DATA_SENSOR_2" 3 "TPMS_DATA_SENSOR_3";
VAL_ 537 VCSEC_TPMSBatVoltage0 255 "SNA";
VAL_ 537 VCSEC_TPMSBatVoltage1 255 "SNA";
VAL_ 537 VCSEC_TPMSBatVoltage2 255 "SNA";
VAL_ 537 VCSEC_TPMSBatVoltage3 255 "SNA";
VAL_ 537 VCSEC_TPMSLocation0 0 "LOCATION_FL" 1 "LOCATION_FR" 2 "LOCATION_RL" 3 "LOCATION_RR" 4 "LOCATION_UNKNOWN";
VAL_ 537 VCSEC_TPMSLocation1 0 "LOCATION_FL" 1 "LOCATION_FR" 2 "LOCATION_RL" 3 "LOCATION_RR" 4 "LOCATION_UNKNOWN";
VAL_ 537 VCSEC_TPMSLocation2 0 "LOCATION_FL" 1 "LOCATION_FR" 2 "LOCATION_RL" 3 "LOCATION_RR" 4 "LOCATION_UNKNOWN";
VAL_ 537 VCSEC_TPMSLocation3 0 "LOCATION_FL" 1 "LOCATION_FR" 2 "LOCATION_RL" 3 "LOCATION_RR" 4 "LOCATION_UNKNOWN";
VAL_ 537 VCSEC_TPMSPressure0 255 "SNA";
VAL_ 537 VCSEC_TPMSPressure1 255 "SNA";
VAL_ 537 VCSEC_TPMSPressure2 255 "SNA";
VAL_ 537 VCSEC_TPMSPressure3 255 "SNA";
VAL_ 537 VCSEC_TPMSTemperature0 255 "SNA";
VAL_ 537 VCSEC_TPMSTemperature1 255 "SNA";
VAL_ 537 VCSEC_TPMSTemperature2 255 "SNA";
VAL_ 537 VCSEC_TPMSTemperature3 255 "SNA";
VAL_ 1066 VCSEC_TPMSConnectionTypeCurrent0 0 "CONNECTIONTYPE_FAST" 1 "CONNECTIONTYPE_SLOW" 2 "CONNECTIONTYPE_UNKNOWN";
VAL_ 1066 VCSEC_TPMSConnectionTypeCurrent1 0 "CONNECTIONTYPE_FAST" 1 "CONNECTIONTYPE_SLOW" 2 "CONNECTIONTYPE_UNKNOWN";
VAL_ 1066 VCSEC_TPMSConnectionTypeCurrent2 0 "CONNECTIONTYPE_FAST" 1 "CONNECTIONTYPE_SLOW" 2 "CONNECTIONTYPE_UNKNOWN";
VAL_ 1066 VCSEC_TPMSConnectionTypeCurrent3 0 "CONNECTIONTYPE_FAST" 1 "CONNECTIONTYPE_SLOW" 2 "CONNECTIONTYPE_UNKNOWN";
VAL_ 1066 VCSEC_TPMSConnectionTypeDesired0 0 "CONNECTIONTYPE_FAST" 1 "CONNECTIONTYPE_SLOW" 2 "CONNECTIONTYPE_UNKNOWN";
VAL_ 1066 VCSEC_TPMSConnectionTypeDesired1 0 "CONNECTIONTYPE_FAST" 1 "CONNECTIONTYPE_SLOW" 2 "CONNECTIONTYPE_UNKNOWN";
VAL_ 1066 VCSEC_TPMSConnectionTypeDesired2 0 "CONNECTIONTYPE_FAST" 1 "CONNECTIONTYPE_SLOW" 2 "CONNECTIONTYPE_UNKNOWN";
VAL_ 1066 VCSEC_TPMSConnectionTypeDesired3 0 "CONNECTIONTYPE_FAST" 1 "CONNECTIONTYPE_SLOW" 2 "CONNECTIONTYPE_UNKNOWN";
VAL_ 1066 VCSEC_TPMSSensorState0 3 "SENSOR_CONNECTED" 4 "SENSOR_DISCONNECTING" 0 "SENSOR_NOT_PAIRED" 1 "SENSOR_WAIT_FOR_ADV" 2 "SENSOR_WAIT_FOR_CONN";
VAL_ 1066 VCSEC_TPMSSensorState1 3 "SENSOR_CONNECTED" 4 "SENSOR_DISCONNECTING" 0 "SENSOR_NOT_PAIRED" 1 "SENSOR_WAIT_FOR_ADV" 2 "SENSOR_WAIT_FOR_CONN";
VAL_ 1066 VCSEC_TPMSSensorState2 3 "SENSOR_CONNECTED" 4 "SENSOR_DISCONNECTING" 0 "SENSOR_NOT_PAIRED" 1 "SENSOR_WAIT_FOR_ADV" 2 "SENSOR_WAIT_FOR_CONN";
VAL_ 1066 VCSEC_TPMSSensorState3 3 "SENSOR_CONNECTED" 4 "SENSOR_DISCONNECTING" 0 "SENSOR_NOT_PAIRED" 1 "SENSOR_WAIT_FOR_ADV" 2 "SENSOR_WAIT_FOR_CONN";
VAL_ 558 PARK_sdiSensor10RawDistData 0 "BLOCKED" 1 "NEAR_DETECTION" 500 "NO_OBJECT_DETECTED" 511 "SNA";
VAL_ 558 PARK_sdiSensor11RawDistData 0 "BLOCKED" 1 "NEAR_DETECTION" 500 "NO_OBJECT_DETECTED" 511 "SNA";
VAL_ 558 PARK_sdiSensor12RawDistData 0 "BLOCKED" 1 "NEAR_DETECTION" 500 "NO_OBJECT_DETECTED" 511 "SNA";
VAL_ 558 PARK_sdiSensor7RawDistData 0 "BLOCKED" 1 "NEAR_DETECTION" 500 "NO_OBJECT_DETECTED" 511 "SNA";
VAL_ 558 PARK_sdiSensor8RawDistData 0 "BLOCKED" 1 "NEAR_DETECTION" 500 "NO_OBJECT_DETECTED" 511 "SNA";
VAL_ 558 PARK_sdiSensor9RawDistData 0 "BLOCKED" 1 "NEAR_DETECTION" 500 "NO_OBJECT_DETECTED" 511 "SNA";
VAL_ 568 UI_countryCode 1023 "SNA" 0 "UNKNOWN";
VAL_ 568 UI_mapSpeedLimit 3 "LESS_OR_EQ_10" 21 "LESS_OR_EQ_100" 22 "LESS_OR_EQ_105" 23 "LESS_OR_EQ_110" 24 "LESS_OR_EQ_115" 25 "LESS_OR_EQ_120" 26 "LESS_OR_EQ_130" 27 "LESS_OR_EQ_140" 4 "LESS_OR_EQ_15" 28 "LESS_OR_EQ_150" 29 "LESS_OR_EQ_160" 5 "LESS_OR_EQ_20" 6 "LESS_OR_EQ_25" 7 "LESS_OR_EQ_30" 8 "LESS_OR_EQ_35" 9 "LESS_OR_EQ_40" 10 "LESS_OR_EQ_45" 1 "LESS_OR_EQ_5" 11 "LESS_OR_EQ_50" 12 "LESS_OR_EQ_55" 13 "LESS_OR_EQ_60" 14 "LESS_OR_EQ_65" 2 "LESS_OR_EQ_7" 15 "LESS_OR_EQ_70" 16 "LESS_OR_EQ_75" 17 "LESS_OR_EQ_80" 18 "LESS_OR_EQ_85" 19 "LESS_OR_EQ_90" 20 "LESS_OR_EQ_95" 31 "SNA" 0 "UNKNOWN" 30 "UNLIMITED";
VAL_ 568 UI_mapSpeedLimitDependency 6 "LANE" 0 "NONE" 2 "RAIN" 1 "SCHOOL" 5 "SEASON" 7 "SNA" 3 "SNOW" 4 "TIME";
VAL_ 568 UI_mapSpeedLimitType 2 "ADVISORY" 4 "BUMPS" 3 "DEPENDENT" 1 "REGULAR" 7 "UNKNOWN_SNA";
VAL_ 568 UI_mapSpeedUnits 1 "KPH" 0 "MPH";
VAL_ 568 UI_nextBranchDist 31 "SNA";
VAL_ 568 UI_roadClass 1 "CLASS_1_MAJOR" 2 "CLASS_2" 3 "CLASS_3" 4 "CLASS_4" 5 "CLASS_5" 6 "CLASS_6_MINOR" 0 "UNKNOWN_INVALID_SNA";
VAL_ 569 DAS_leftFork 1 "LEFT_FORK_AVAILABLE" 0 "LEFT_FORK_NONE" 2 "LEFT_FORK_SELECTED" 3 "LEFT_FORK_UNAVAILABLE";
VAL_ 569 DAS_leftLineUsage 1 "AVAILABLE" 3 "BLACKLISTED" 2 "FUSED" 0 "REJECTED_UNAVAILABLE";
VAL_ 569 DAS_rightFork 1 "RIGHT_FORK_AVAILABLE" 0 "RIGHT_FORK_NONE" 2 "RIGHT_FORK_SELECTED" 3 "RIGHT_FORK_UNAVAILABLE";
VAL_ 569 DAS_rightLineUsage 1 "AVAILABLE" 3 "BLACKLISTED" 2 "FUSED" 0 "REJECTED_UNAVAILABLE";
VAL_ 583 DAS_alcInternalState 2 "ALC_ABORTING" 8 "ALC_ACTIVE_ACC_LEFT" 9 "ALC_ACTIVE_ACC_RIGHT" 6 "ALC_ACTIVE_LEFT" 7 "ALC_ACTIVE_RIGHT" 3 "ALC_BEHAVIOR_CHECK" 0 "ALC_DISABLED" 1 "ALC_IDLE" 4 "ALC_PRE_ACTIVE_LEFT" 5 "ALC_PRE_ACTIVE_RIGHT" 12 "ALC_RETRY" 10 "ALC_SOFT_ABORTING_LEFT" 11 "ALC_SOFT_ABORTING_RIGHT";
VAL_ 583 DAS_arbiterBehavior 4 "ARBITER_CITY_STREETS" 0 "ARBITER_INVALID" 1 "ARBITER_IN_LANE" 2 "ARBITER_LANE_CHANGE_LEFT" 3 "ARBITER_LANE_CHANGE_RIGHT";
VAL_ 583 DAS_autopilotAbortReason 21 "ABORT_ACC_CANCEL_GENERIC" 22 "ABORT_ACC_CANCEL_SILENT" 23 "ABORT_ACC_FAULT" 33 "ABORT_AEB" 18 "ABORT_CAMERA_CALIBRATION" 17 "ABORT_CAMERA_FAILSAFES" 32 "ABORT_CONTROLLER_BAD_REF_UPDATE" 27 "ABORT_CONTROLLER_NOT_ALLOWED" 25 "ABORT_CONTROLLER_REFERENCE" 34 "ABORT_CONTROLLER_REF_TOO_SHORT" 26 "ABORT_CONTROLLER_SOLVER" 31 "ABORT_CONTROLLER_STALE_LOCALIZATION" 30 "ABORT_CONTROLLER_STALE_REFERENCE" 10 "ABORT_CRUISE_FAULT" 11 "ABORT_CRUISE_NOT_ACTIVE" 2 "ABORT_DI_MIA" 16 "ABORT_EPAS_EAC_ERROR" 15 "ABORT_EPAS_EAC_NOT_ACTIVE" 4 "ABORT_EPAS_MIA" 39 "ABORT_EPAS_STEERING_ANGLE_INVALID" 3 "ABORT_ESP_MIA" 36 "ABORT_GORE_INCURSION" 5 "ABORT_GTW_MIA" 48 "ABORT_HEADLIGHT_OFF_AT_NIGHT" 47 "ABORT_IBOOSTER_MIA" 46 "ABORT_INTEGRATOR_HEALTH_CRITICAL" 41 "ABORT_INVALID_DI_PEDAL_POS" 42 "ABORT_INVALID_VEHICLE_SPEED" 29 "ABORT_MAP_HEALTH" 35 "ABORT_MISSION_PLANNER_NO_VISION_LANES_FOUND" 0 "ABORT_NONE" 49 "ABORT_ONCOMING_LANE" 43 "ABORT_PERCEPTION_HEALTH_VISION" 19 "ABORT_RADAR_BLIND" 20 "ABORT_RADAR_FAULT" 7 "ABORT_RADAR_MIA" 37 "ABORT_REACHED_END_OF_NAV_STOP" 255 "ABORT_REASON_MAX" 24 "ABORT_ROAD_ESTIMATOR_HEALTH" 6 "ABORT_SCCM_MIA" 44 "ABORT_SEATBELT_UNBUCKLED" 38 "ABORT_STEERING_SATURATED_LANE_DEPARTURE" 28 "ABORT_THERMAL_ISSUE" 13 "ABORT_TRAILER_MODE_ACTIVE" 12 "ABORT_USER_DISABLED" 45 "ABORT_USER_OVERRIDE_STRIKEOUT" 8 "ABORT_VCFRONT_MIA" 9 "ABORT_VCRIGHT_MIA" 14 "ABORT_VEHICLE_SPEED_ABOVE_MAX" 40 "ABORT_W048_FEATURES_DISABLED" 1 "ABORT_WATCHDOG_HEALTH";
VAL_ 583 DAS_behaviorReport 30 "BEHAVIOR_ACTIVE_SAFETY_SLOWDOWN" 40 "BEHAVIOR_CROSSWALK" 41 "BEHAVIOR_CROSS_TRAFFIC_AVOIDANCE" 2 "BEHAVIOR_CURVE_SPEED_ADAPTATION" 35 "BEHAVIOR_CUTIN_VEHICLE" 21 "BEHAVIOR_CUTIN_VEHICLE_LEFT" 22 "BEHAVIOR_CUTIN_VEHICLE_RIGHT" 14 "BEHAVIOR_DRIVABLE_SPACE_VIOLATION" 32 "BEHAVIOR_END_OF_NAV_ROUTE" 5 "BEHAVIOR_FLEET_SPEEDS" 8 "BEHAVIOR_IN_LANE_VEHICLE" 4 "BEHAVIOR_KEEP_CALM" 33 "BEHAVIOR_LANE_SPEED_DIFF" 13 "BEHAVIOR_MAP_LANE_GEOMETRY" 19 "BEHAVIOR_MERGE_VEHICLE_LEFT" 20 "BEHAVIOR_MERGE_VEHICLE_RIGHT" 29 "BEHAVIOR_MP_AP_INACTIVE" 23 "BEHAVIOR_MP_AP_RESTRICTION" 26 "BEHAVIOR_MP_AP_STATE_MACHINE" 27 "BEHAVIOR_MP_DI_CRUISE" 25 "BEHAVIOR_MP_DRIVER_MONITOR" 24 "BEHAVIOR_MP_NOT_BUCKLED" 28 "BEHAVIOR_MP_ULC" 17 "BEHAVIOR_NAV_FLEET_SPEEDS" 18 "BEHAVIOR_NAV_PATH_CSA" 3 "BEHAVIOR_RADAR_ONLY_BRAKING" 39 "BEHAVIOR_RELEVANT_VRU" 38 "BEHAVIOR_RISK_MANAGER" 43 "BEHAVIOR_ROUNDABOUT" 15 "BEHAVIOR_SLOWING_FOR_TARGET_LANE" 34 "BEHAVIOR_STATIC_OBJECT" 36 "BEHAVIOR_STATIC_OBJECT_MERGE_LEFT" 37 "BEHAVIOR_STATIC_OBJECT_MERGE_RIGHT" 31 "BEHAVIOR_STEERING_SATURATED" 9 "BEHAVIOR_TARGET_LANE_VEHICLE" 42 "BEHAVIOR_TOLLBOOTH" 11 "BEHAVIOR_TRAFFIC_CONTROL" 6 "BEHAVIOR_TRAFFIC_CONTROL_STOPPED_STATE" 7 "BEHAVIOR_UNDERTAKE_ASSIST_KEEP_CALM" 10 "BEHAVIOR_UNDERTAKE_VEHICLE" 1 "BEHAVIOR_VIEW_RANGE" 12 "BEHAVIOR_VISION_LANE_GEOMETRY" 16 "BEHAVIOR_VISION_SPEEDS";
VAL_ 583 DAS_controllerHealth 2 "CONTROLLER_CRITICAL" 1 "CONTROLLER_DEGRADED" 0 "CONTROLLER_HEALTHY" 3 "CONTROLLER_SOLVER_FAILURE";
VAL_ 583 DAS_controllerRef 4 "CONTROLLER_REFERENCE_BAD_REF_UPDATE" 0 "CONTROLLER_REFERENCE_HEALTHY" 6 "CONTROLLER_REFERENCE_INDETERMINATE" 5 "CONTROLLER_REFERENCE_REF_TOO_SHORT" 3 "CONTROLLER_REFERENCE_STALE_LOCALIZATION" 2 "CONTROLLER_REFERENCE_STALE_REFERENCE" 1 "CONTROLLER_REFERENCE_UNHEALTHY";
VAL_ 583 DAS_forkState 18 "FORK_ABORT_BLINKER_CHANGE" 17 "FORK_ABORT_CONTROL_INACTIVE" 21 "FORK_ABORT_DISALLOW" 19 "FORK_ABORT_NOT_LEFT_LANE" 20 "FORK_ABORT_NOT_RIGHT_LANE" 22 "FORK_ABORT_OTHER" 12 "FORK_ACTIVE_LEFT_NAV" 13 "FORK_ACTIVE_LEFT_USER" 14 "FORK_ACTIVE_RIGHT_NAV" 15 "FORK_ACTIVE_RIGHT_USER" 16 "FORK_FORK_COMPLETE" 8 "FORK_IDLE_BOTH_FORKS_AVAILABLE" 9 "FORK_IDLE_LEFT_FORK_AVAILABLE" 11 "FORK_IDLE_NO_FORKS_AVAILABLE" 10 "FORK_IDLE_RIGHT_FORK_AVAILABLE" 0 "FORK_INVALID" 25 "FORK_PRE_ACTIVE_LEFT_NAV" 26 "FORK_PRE_ACTIVE_RIGHT_NAV" 2 "FORK_UNAVAILABLE_AP_INACTIVE" 3 "FORK_UNAVAILABLE_CONSTRUCTION" 4 "FORK_UNAVAILABLE_CONTROLLED_ACCESS_TOO_FAR" 1 "FORK_UNAVAILABLE_DISABLED" 5 "FORK_UNAVAILABLE_DON_INACTIVE" 27 "FORK_UNAVAILABLE_INTERSECTION_ACTIVE" 7 "FORK_UNAVAILABLE_OTHER" 23 "FORK_UNAVAILABLE_TIGHT_TURN_RADIUS" 6 "FORK_UNAVAILABLE_TOLL_BOOTH" 24 "FORK_UNAVAILABLE_WEATHER";
VAL_ 583 DAS_laneChangeState 19 "LANE_CHANGE_ABORTING_ACC_AUTOSTEER_ACTIVATED" 26 "LANE_CHANGE_ABORTING_ALC_REQUEST_BEFORE_ULC_CONFIRM" 23 "LANE_CHANGE_ABORTING_BEHAVIOR_CHANGED" 22 "LANE_CHANGE_ABORTING_BELOW_MIN_SPEED" 14 "LANE_CHANGE_ABORTING_BLIND_SPOT_OCCUPIED" 12 "LANE_CHANGE_ABORTING_BLINKER" 32 "LANE_CHANGE_ABORTING_CONSTRUCTION_DETECTED" 43 "LANE_CHANGE_ABORTING_DESTINATION_LANE_UNSTABLE" 17 "LANE_CHANGE_ABORTING_FORK_AVAILABLE" 31 "LANE_CHANGE_ABORTING_GORE_POINT" 24 "LANE_CHANGE_ABORTING_HIGH_ALC_PROGRESS_ERROR" 11 "LANE_CHANGE_ABORTING_INACTIVE" 21 "LANE_CHANGE_ABORTING_INVALID_BEHAVIOR" 15 "LANE_CHANGE_ABORTING_INVALID_MODE" 16 "LANE_CHANGE_ABORTING_LINE_TYPE" 18 "LANE_CHANGE_ABORTING_LOST_VISION_POSE" 37 "LANE_CHANGE_ABORTING_NO_HANDS_ON" 40 "LANE_CHANGE_ABORTING_SNOOZED" 39 "LANE_CHANGE_ABORTING_SOURCE_AND_TARGET_LANES_MERGED" 34 "LANE_CHANGE_ABORTING_TIGHT_TURN_RADIUS" 13 "LANE_CHANGE_ABORTING_TIMEOUT" 33 "LANE_CHANGE_ABORTING_TOLL_BOOTH_DETECTED" 20 "LANE_CHANGE_ABORTING_ULC_BLINKER_TIMEOUT" 25 "LANE_CHANGE_ABORTING_ULC_CONFIRMATION_TIMEOUT" 35 "LANE_CHANGE_ABORTING_WEATHER" 10 "LANE_CHANGE_AVAILABLE_BOTH" 8 "LANE_CHANGE_AVAILABLE_LEFT_ONLY" 9 "LANE_CHANGE_AVAILABLE_RIGHT_ONLY" 29 "LANE_CHANGE_BLOCKED_LEFT" 30 "LANE_CHANGE_BLOCKED_RIGHT" 27 "LANE_CHANGE_IN_PROGRESS_LEFT" 28 "LANE_CHANGE_IN_PROGRESS_RIGHT" 42 "LANE_CHANGE_UNAVAILABLE_AUTOPILOT_ABORTING" 36 "LANE_CHANGE_UNAVAILABLE_BLINDSPOT_RESTRICTED" 41 "LANE_CHANGE_UNAVAILABLE_BLINKER_LATCHED" 0 "LANE_CHANGE_UNAVAILABLE_DISABLED" 5 "LANE_CHANGE_UNAVAILABLE_FORK_MODE" 4 "LANE_CHANGE_UNAVAILABLE_INACTIVE" 7 "LANE_CHANGE_UNAVAILABLE_INVALID_MODE" 3 "LANE_CHANGE_UNAVAILABLE_NO_LANES" 38 "LANE_CHANGE_UNAVAILABLE_NO_REAR_OBJECT" 1 "LANE_CHANGE_UNAVAILABLE_ROAD_NOT_APPROPRIATE" 2 "LANE_CHANGE_UNAVAILABLE_SPEED" 6 "LANE_CHANGE_UNAVAILABLE_ULTRASONICS_NOT_READY" 63 "LANE_CHANGE_UNKNOWN";
VAL_ 583 DAS_lastWatchdogCode 68 "ACTIVE_SAFETY_FAILED" 51 "AP_STATE_MACHINE_FAILED" 50 "ARBITER_FAILED" 57 "ATLAS_FAILED" 79 "BEV_GRAPH_FAILED" 77 "BRIDGE_FAILED" 67 "CAMERA_FAILED" 45 "CAN_RX_FAILED" 46 "CAN_TX_FAILED" 78 "CITY_STREETS_BEHAVIOR_FAILED" 74 "CLIP_LOGGER_FAILED" 52 "CONTROLLER_FAILED" 75 "DRIVABLE_SPACE_TRACKER_FAILED" 65 "DRIVER_MONITOR_FAILED" 70 "DYNAMICS_FAILED" 71 "FIELD_CALIBRATION_FAILED" 49 "GPS_FAILED" 73 "HW_MONITOR_FAILED" 61 "IMU_FAILED" 48 "INERTIATOR_FAILED" 63 "LANE_CHANGE_BEHAVIOR_FAILED" 43 "LEGACY_FAILED" 53 "LOCALIZER_FAILED" 66 "MAP_MANAGER_FAILED" 54 "MISSION_PLANNER_FAILED" 0 "NO_TASK_FAILED" 72 "PARKING_BEHAVIOR_FAILED" 55 "PERCEPTION_FAILED" 60 "RAIN_LIGHT_SENSING_FAILED" 56 "ROAD_ESTIMATOR_FAILED" 76 "SCHEDULER_FAILED" 41 "SNAPSHOT_FAILED" 59 "SNAPSHOT_TRIGGER_CLIENT_FAILED" 58 "STAY_IN_LANE_BEHAVIOR_FAILED" 40 "TELEMETRY_FAILED" 39 "TELEMETRY_PACKAGER_FAILED" 47 "TEMPERATURE_MONITOR_FAILED" 62 "UBX_LOG_FAILED" 69 "UI_SERVER_FAILED" 80 "ULTRASONICS_FAILED" 30 "UNKNOWN_TASK_FAILED" 42 "VISION_FAILED" 44 "WATCHDOG_FAILED";
VAL_ 583 DAS_mapAvailability 1 "APM_MAP_AVAILABLE" 0 "APM_MAP_NOT_AVAILABLE";
VAL_ 583 DAS_roadEstimator 3 "ROAD_ESTIMATOR_CRITICAL" 2 "ROAD_ESTIMATOR_DEGRADED" 0 "ROAD_ESTIMATOR_HEALTHY" 1 "ROAD_ESTIMATOR_UNSTABLE_MEASUREMENTS";
VAL_ 583 DAS_rqstedBehaviorStatus 19 "RQST_BEHAVIOR_BAD_ORIGIN_UPDATE" 9 "RQST_BEHAVIOR_BLOCKED_BY_BLINDSPOT_CAMERA_INVALID_L" 14 "RQST_BEHAVIOR_BLOCKED_BY_BLINDSPOT_CAMERA_INVALID_R" 8 "RQST_BEHAVIOR_BLOCKED_BY_BLINDSPOT_CAMERA_L" 13 "RQST_BEHAVIOR_BLOCKED_BY_BLINDSPOT_CAMERA_R" 11 "RQST_BEHAVIOR_BLOCKED_BY_LANE_TYPE_L" 16 "RQST_BEHAVIOR_BLOCKED_BY_LANE_TYPE_R" 20 "RQST_BEHAVIOR_BLOCKED_BY_SLOW_TARGET_L" 21 "RQST_BEHAVIOR_BLOCKED_BY_SLOW_TARGET_R" 10 "RQST_BEHAVIOR_BLOCKED_BY_ULTRASOUND_AND_CAMERA_L" 15 "RQST_BEHAVIOR_BLOCKED_BY_ULTRASOUND_AND_CAMERA_R" 7 "RQST_BEHAVIOR_BLOCKED_BY_ULTRASOUND_L" 12 "RQST_BEHAVIOR_BLOCKED_BY_ULTRASOUND_R" 6 "RQST_BEHAVIOR_BUILD_ARGUMENT_FAIL" 22 "RQST_BEHAVIOR_INVALID_PLAN" 3 "RQST_BEHAVIOR_MAP_NOT_INITIALIZED" 2 "RQST_BEHAVIOR_NO_DEST_POLYLANE" 4 "RQST_BEHAVIOR_NO_SOURCE_LANE_ON_MAP" 1 "RQST_BEHAVIOR_NO_SRC_POLYLANE" 5 "RQST_BEHAVIOR_NO_TARGET_LANE_ON_MAP" 18 "RQST_BEHAVIOR_OUT_OF_DATE" 17 "RQST_BEHAVIOR_ROAD_NOT_APPROPRIATE" 0 "RQST_BEHAVIOR_VALID";
VAL_ 586 DAS_accSmartSpeedState 2 "ACTIVE_INTEGRATING" 1 "ACTIVE_OFFRAMP" 3 "ACTIVE_ONRAMP" 0 "NOT_ACTIVE" 5 "OFFRAMP_DELAY" 4 "SET_SPEED_SET_REQUESTED" 7 "SNA";
VAL_ 586 DAS_autosteerBottsDotsUsage 1 "AVAILABLE" 3 "BLACKLISTED" 2 "FUSED" 0 "REJECTED_UNAVAILABLE";
VAL_ 586 DAS_autosteerHPPUsage 1 "AVAILABLE" 3 "BLACKLISTED" 2 "FUSED" 0 "REJECTED_UNAVAILABLE";
VAL_ 586 DAS_autosteerHealthState 4 "HEALTH_ABORTING" 2 "HEALTH_DEGRADED" 5 "HEALTH_FAULT" 1 "HEALTH_NOMINAL" 3 "HEALTH_SEVERELY_DEGRADED" 0 "HEALTH_UNAVAILABLE";
VAL_ 586 DAS_autosteerModelUsage 1 "AVAILABLE" 3 "BLACKLISTED" 2 "FUSED" 0 "REJECTED_UNAVAILABLE";
VAL_ 586 DAS_autosteerNavigationUsage 1 "AVAILABLE" 3 "BLACKLISTED" 2 "FUSED" 0 "REJECTED_UNAVAILABLE";
VAL_ 586 DAS_autosteerVehiclesUsage 1 "AVAILABLE" 3 "BLACKLISTED" 2 "FUSED" 0 "REJECTED_UNAVAILABLE";
VAL_ 586 DAS_behaviorType 0 "DAS_BEHAVIOR_INVALID" 1 "DAS_BEHAVIOR_IN_LANE" 2 "DAS_BEHAVIOR_LANE_CHANGE_LEFT" 3 "DAS_BEHAVIOR_LANE_CHANGE_RIGHT";
VAL_ 586 DAS_lastAutosteerAbortReason 29 "UI_ABORT_REASON_ACC_CANCEL" 32 "UI_ABORT_REASON_AEB" 14 "UI_ABORT_REASON_APP_ME_STATE_NOT_VISION" 30 "UI_ABORT_REASON_CAMERA_FAILSAFES" 16 "UI_ABORT_REASON_CAM_MSG_MIA" 17 "UI_ABORT_REASON_CAM_WATCHDOG" 23 "UI_ABORT_REASON_CID_SWITCH_DISABLED" 21 "UI_ABORT_REASON_COMPONENT_MIA" 22 "UI_ABORT_REASON_CRUISE_FAULT" 24 "UI_ABORT_REASON_DRIVING_OFF_NAV" 20 "UI_ABORT_REASON_EPAS_EAC_DENIED" 28 "UI_ABORT_REASON_EPAS_ERROR_CODE" 26 "UI_ABORT_REASON_FOLLOWER_OUTPUT_INVALID" 0 "UI_ABORT_REASON_HM_LANE_VIEW_RANGE" 2 "UI_ABORT_REASON_HM_STEERING_ERROR" 1 "UI_ABORT_REASON_HM_VIRTUAL_LANE_NO_INPUTS" 15 "UI_ABORT_REASON_ME_MAIN_STATE_NOT_VISION" 31 "UI_ABORT_REASON_NO_ABORT" 27 "UI_ABORT_REASON_PLANNER_OUTPUT_INVALID" 33 "UI_ABORT_REASON_SEATBELT_UNBUCKLED" 19 "UI_ABORT_REASON_SIDE_COLLISION_IMMINENT" 18 "UI_ABORT_REASON_TRAILER_MODE" 34 "UI_ABORT_REASON_USER_OVERRIDE_STRIKEOUT" 25 "UI_ABORT_REASON_VEHICLE_SPEED_ABOVE_MAX";
VAL_ 586 DAS_lastLinePreferenceReason 1 "AGREEMENT_WITH_NEIGHBOR_LANES" 4 "AVOID_ONCOMING_LANES" 5 "COUNTRY_DRIVING_SIDE" 3 "NAVIGATION_BRANCH" 2 "NEIGHBOR_LANE_PROBABILIY" 15 "NONE" 0 "OTHER_LANE_DISAGREES_WITH_MODEL";
VAL_ 586 DAS_navAvailable 1 "DAS_NAV_AVAILABLE" 0 "DAS_NAV_UNAVAILABLE";
VAL_ 586 DAS_offsetSide 0 "NO_OFFSET" 3 "OFFSET_BOTH_OBJECTS" 2 "OFFSET_LEFT_OBJECT" 1 "OFFSET_RIGHT_OBJECT";
VAL_ 586 DAS_plannerState 0 "TP_EXTSTATE_DISABLED" 2 "TP_EXTSTATE_FOLLOW" 7 "TP_EXTSTATE_LANECHANGE_ABORT" 4 "TP_EXTSTATE_LANECHANGE_IN_PROGRESS" 3 "TP_EXTSTATE_LANECHANGE_REQUESTED" 6 "TP_EXTSTATE_LANECHANGE_WAIT_FOR_FWD_OBSTACLE" 5 "TP_EXTSTATE_LANECHANGE_WAIT_FOR_SIDE_OBSTACLE" 1 "TP_EXTSTATE_VL";
VAL_ 586 DAS_rearLeftVehDetectedCurrent 1 "VEHICLE_DETECTED" 0 "VEHICLE_NOT_DETECTED";
VAL_ 586 DAS_rearLeftVehDetectedTrip 1 "VEHICLE_DETECTED" 0 "VEHICLE_NOT_DETECTED";
VAL_ 586 DAS_rearRightVehDetectedTrip 1 "VEHICLE_DETECTED" 0 "VEHICLE_NOT_DETECTED";
VAL_ 586 DAS_rearVehDetectedThisCycle 1 "VEHICLE_DETECTED" 0 "VEHICLE_NOT_DETECTED";
VAL_ 586 DAS_roadSurfaceType 2 "ROAD_SURFACE_ENHANCED" 1 "ROAD_SURFACE_NORMAL" 0 "ROAD_SURFACE_SNA";
VAL_ 586 DAS_ulcInProgress 1 "ULC_ACTIVE" 0 "ULC_INACTIVE";
VAL_ 586 DAS_ulcType 1 "ULC_TYPE_NAV" 0 "ULC_TYPE_NONE" 2 "ULC_TYPE_SPEED";
VAL_ 605 CP_UHF_controlState 3 "CP_UHF_CALIBRATE" 6 "CP_UHF_CHECK_RX" 1 "CP_UHF_CONFIG" 10 "CP_UHF_FAULT" 8 "CP_UHF_HANDLE_FOUND" 2 "CP_UHF_IDLE" 0 "CP_UHF_INIT" 4 "CP_UHF_PREPARE_RX" 7 "CP_UHF_READ_RXFIFO" 5 "CP_UHF_RX" 9 "CP_UHF_SLEEP";
VAL_ 605 CP_chargeCablePresent 0 "CABLE_NOT_PRESENT" 1 "CABLE_PRESENT";
VAL_ 605 CP_chargeCableState 2 "CHARGE_CABLE_CONNECTED" 1 "CHARGE_CABLE_NOT_CONNECTED" 0 "CHARGE_CABLE_UNKNOWN_SNA";
VAL_ 605 CP_coldWeatherMode 1 "CP_COLD_WEATHER_LATCH_MITIGATION" 0 "CP_COLD_WEATHER_NONE";
VAL_ 605 CP_doorControlState 5 "CP_doorClosing" 1 "CP_doorIdle" 0 "CP_doorInit" 2 "CP_doorOpenRequested" 3 "CP_doorOpening" 6 "CP_doorSenseClosed" 4 "CP_doorSenseOpen";
VAL_ 605 CP_faultLineSensed 0 "FAULT_LINE_CLEARED" 1 "FAULT_LINE_SET";
VAL_ 605 CP_inductiveDoorState 7 "CP_INDUCTIVE_DOOR_FAULT" 0 "CP_INDUCTIVE_DOOR_INIT" 1 "CP_INDUCTIVE_DOOR_INIT_FROM_CHARGE" 2 "CP_INDUCTIVE_DOOR_INIT_FROM_DRIVE" 4 "CP_INDUCTIVE_DOOR_NOT_PRESENT" 6 "CP_INDUCTIVE_DOOR_OFF_CHARGE" 5 "CP_INDUCTIVE_DOOR_OFF_DRIVE" 3 "CP_INDUCTIVE_DOOR_PRESENT";
VAL_ 605 CP_inductiveSensorState 7 "CP_INDUCTIVE_SENSOR_CONFIG" 5 "CP_INDUCTIVE_SENSOR_FAULT" 0 "CP_INDUCTIVE_SENSOR_INIT" 3 "CP_INDUCTIVE_SENSOR_PAUSE" 1 "CP_INDUCTIVE_SENSOR_POLL" 6 "CP_INDUCTIVE_SENSOR_RESET" 2 "CP_INDUCTIVE_SENSOR_SHUTDOWN" 4 "CP_INDUCTIVE_SENSOR_WAIT_FOR_INIT";
VAL_ 605 CP_latch2ControlState 2 "CP_latchDisengageRequested" 4 "CP_latchDisengaged" 3 "CP_latchDisengaging" 5 "CP_latchEngaging" 1 "CP_latchIdle" 0 "CP_latchInit";
VAL_ 605 CP_latch2State 3 "CP_LATCH_BLOCKING" 1 "CP_LATCH_DISENGAGED" 2 "CP_LATCH_ENGAGED" 0 "CP_LATCH_SNA";
VAL_ 605 CP_latchControlState 2 "CP_latchDisengageRequested" 4 "CP_latchDisengaged" 3 "CP_latchDisengaging" 5 "CP_latchEngaging" 1 "CP_latchIdle" 0 "CP_latchInit";
VAL_ 605 CP_latchState 3 "CP_LATCH_BLOCKING" 1 "CP_LATCH_DISENGAGED" 2 "CP_LATCH_ENGAGED" 0 "CP_LATCH_SNA";
VAL_ 605 CP_ledColor 7 "CP_LEDS_AMBER" 3 "CP_LEDS_BLUE" 9 "CP_LEDS_DEBUG" 6 "CP_LEDS_FLASHING_AMBER" 10 "CP_LEDS_FLASHING_BLUE" 5 "CP_LEDS_FLASHING_GREEN" 2 "CP_LEDS_GREEN" 0 "CP_LEDS_OFF" 8 "CP_LEDS_RAVE" 1 "CP_LEDS_RED" 4 "CP_LEDS_WHITE";
VAL_ 605 CP_type 1 "CP_TYPE_EURO_IEC" 2 "CP_TYPE_GB" 3 "CP_TYPE_IEC_CCS" 0 "CP_TYPE_US_TESLA";
VAL_ 697 DAS_accState 1 "ACC_CANCEL_CAMERA_BLIND" 0 "ACC_CANCEL_GENERIC" 13 "ACC_CANCEL_GENERIC_SILENT" 14 "ACC_CANCEL_OUT_OF_CALIBRATION" 12 "ACC_CANCEL_PATH_NOT_CLEAR" 2 "ACC_CANCEL_RADAR_BLIND" 3 "ACC_HOLD" 4 "ACC_ON" 8 "APC_ABORT" 5 "APC_BACKWARD" 7 "APC_COMPLETE" 6 "APC_FORWARD" 9 "APC_PAUSE" 11 "APC_SELFPARK_START" 10 "APC_UNPARK_COMPLETE" 15 "FAULT_SNA";
VAL_ 697 DAS_accelMax 511 "SNA";
VAL_ 697 DAS_accelMin 511 "SNA";
VAL_ 697 DAS_aebEvent 1 "AEB_ACTIVE" 2 "AEB_FAULT" 0 "AEB_NOT_ACTIVE" 3 "AEB_SNA";
VAL_ 697 DAS_jerkMax 255 "SNA";
VAL_ 697 DAS_jerkMin 511 "SNA";
VAL_ 697 DAS_setSpeed 4095 "SNA";
VAL_ 723 UI_isSunUp 0 "SUN_DOWN" 3 "SUN_SNA" 1 "SUN_UP";
VAL_ 723 UI_solarAzimuthAngle 32768 "SNA";
VAL_ 723 UI_solarAzimuthAngleCarRef 255 "SNA";
VAL_ 723 UI_solarElevationAngle 127 "SNA";
VAL_ 777 DAS_objectId 3 "CUTIN_VEHICLE" 0 "LEAD_VEHICLES" 1 "LEFT_VEHICLES" 2 "RIGHT_VEHICLES" 4 "ROAD_SIGN" 5 "VEHICLE_HEADINGS";
VAL_ 777 DAS_cutinVehDx 255 "SNA";
VAL_ 777 DAS_cutinVehHeading 255 "SNA";
VAL_ 777 DAS_cutinVehId 127 "SNA";
VAL_ 777 DAS_cutinVehType 4 "BICYCLE" 2 "CAR" 3 "MOTORCYCLE" 5 "PEDESTRIAN" 1 "TRUCK" 0 "UNKNOWN";
VAL_ 777 DAS_cutinVehVxRel 15 "SNA";
VAL_ 777 DAS_leadVeh2Dx 255 "SNA";
VAL_ 777 DAS_leadVeh2Heading 255 "SNA";
VAL_ 777 DAS_leadVeh2Id 0 "SNA";
VAL_ 777 DAS_leadVeh2Type 4 "BICYCLE" 2 "CAR" 3 "MOTORCYCLE" 5 "PEDESTRIAN" 1 "TRUCK" 0 "UNKNOWN";
VAL_ 777 DAS_leadVeh2VxRel 15 "SNA";
VAL_ 777 DAS_leadVehDx 255 "SNA";
VAL_ 777 DAS_leadVehHeading 255 "SNA";
VAL_ 777 DAS_leadVehId 127 "SNA";
VAL_ 777 DAS_leadVehType 4 "BICYCLE" 2 "CAR" 6 "IPSO" 3 "MOTORCYCLE" 5 "PEDESTRIAN" 1 "TRUCK" 0 "UNKNOWN";
VAL_ 777 DAS_leadVehVxRel 15 "SNA";
VAL_ 777 DAS_leftVeh2Dx 255 "SNA";
VAL_ 777 DAS_leftVeh2Heading 255 "SNA";
VAL_ 777 DAS_leftVeh2Id 0 "SNA";
VAL_ 777 DAS_leftVeh2Type 4 "BICYCLE" 2 "CAR" 3 "MOTORCYCLE" 5 "PEDESTRIAN" 1 "TRUCK" 0 "UNKNOWN";
VAL_ 777 DAS_leftVeh2VxRel 15 "SNA";
VAL_ 777 DAS_leftVehDx 255 "SNA";
VAL_ 777 DAS_leftVehHeading 255 "SNA";
VAL_ 777 DAS_leftVehId 127 "SNA";
VAL_ 777 DAS_leftVehType 4 "BICYCLE" 2 "CAR" 3 "MOTORCYCLE" 5 "PEDESTRIAN" 1 "TRUCK" 0 "UNKNOWN";
VAL_ 777 DAS_leftVehVxRel 15 "SNA";
VAL_ 777 DAS_rightVeh2Dx 255 "SNA";
VAL_ 777 DAS_rightVeh2Heading 255 "SNA";
VAL_ 777 DAS_rightVeh2Id 0 "SNA";
VAL_ 777 DAS_rightVeh2Type 4 "BICYCLE" 2 "CAR" 3 "MOTORCYCLE" 5 "PEDESTRIAN" 1 "TRUCK" 0 "UNKNOWN";
VAL_ 777 DAS_rightVeh2VxRel 15 "SNA";
VAL_ 777 DAS_rightVehDx 255 "SNA";
VAL_ 777 DAS_rightVehHeading 255 "SNA";
VAL_ 777 DAS_rightVehId 127 "SNA";
VAL_ 777 DAS_rightVehType 4 "BICYCLE" 2 "CAR" 3 "MOTORCYCLE" 5 "PEDESTRIAN" 1 "TRUCK" 0 "UNKNOWN";
VAL_ 777 DAS_rightVehVxRel 15 "SNA";
VAL_ 777 DAS_roadSignArrow 0 "CIRCLE" 1 "LEFT" 2 "RIGHT" 3 "STRAIGHT" 4 "UNKNOWN";
VAL_ 777 DAS_roadSignColor 3 "GREEN" 0 "NONE" 1 "RED" 4 "RED_YELLOW" 2 "YELLOW";
VAL_ 777 DAS_roadSignId 255 "SNA" 0 "STOP_SIGN" 1 "TRAFFIC_LIGHT";
VAL_ 777 DAS_roadSignOrientation 2 "HORIZONTAL_3_LIGHT" 0 "UNKNOWN" 1 "VERTICAL_3_LIGHT";
VAL_ 777 DAS_roadSignSource 1 "NAV" 0 "NONE" 2 "VISION";
VAL_ 777 DAS_roadSignStopLineDist 1023 "SNA";
